VERSION ""

NS_ :

BS_:

BU_:  Battery  Charger  Host

BO_ 2552103157 ALTC_Alternator_Control: 8 Battery
 SG_ ALT_Pack_Max_Volt_Setpoint : 0|16@1+ (0.001,0) [0|65.535] "V" Host

BO_ 2565341429 BATT_dm11Response: 8 Battery
 SG_ BATT_dm11Resv : 0|64@1+ (1,0) [0|255] "" Host

BO_ 2565472256 HOST_J1939_DM_Request: 3 Host
 SG_ HOST_requested_pgn : 0|24@1+ (1,0) [0|281474976710655] "" Battery

BO_ 2565472502 BATT_dmRequest_0: 3 Battery
 SG_ BATT_dm1ReqPgn_0 : 0|24@1+ (1,0) [0|255] "" Host

BO_ 2565472503 BATT_dmRequest_1: 3 Battery
 SG_ BATT_dm1ReqPgn_1 : 0|24@1+ (1,0) [0|255] "" Host

BO_ 2565472504 BATT_dmRequest_2: 3 Battery
 SG_ BATT_dm1ReqPgn_2 : 0|24@1+ (1,0) [0|255] "" Host

BO_ 2565472505 BATT_dmRequest_3: 3 Battery
 SG_ BATT_dm1ReqPgn_3 : 0|24@1+ (1,0) [0|255] "" Host

BO_ 2565472506 BATT_dmRequest_4: 3 Battery
 SG_ BATT_dm1ReqPgn_4 : 0|24@1+ (1,0) [0|255] "" Host

BO_ 2565472507 BATT_dmRequest_5: 3 Battery
 SG_ BATT_dm1ReqPgn_5 : 0|24@1+ (1,0) [0|255] "" Host

BO_ 2565472508 BATT_dmRequest_6: 3 Battery
 SG_ BATT_dm1ReqPgn_6 : 0|24@1+ (1,0) [0|255] "" Host

BO_ 2565472509 BATT_dmRequest_7: 3 Battery
 SG_ BATT_dm1ReqPgn_7 : 0|24@1+ (1,0) [0|255] "" Host

BO_ 2565472510 BATT_dmRequest_8: 3 Battery
 SG_ BATT_dm1ReqPgn_8 : 0|24@1+ (1,0) [0|255] "" Host

BO_ 2565472511 BATT_dmRequest_9: 3 Battery
 SG_ BATT_dm1ReqPgn_9 : 0|24@1+ (1,0) [0|255] "" Host

BO_ 2565538038 BATT_dmTransportMsg_0: 8 Battery
 SG_ BATT_dmPayLoad_0 : 8|56@1+ (1,0) [0|72057594037927904] "" Host
 SG_ BATT_dmSeqNum_0 : 0|8@1+ (1,0) [0|255] "" Host

BO_ 2565538039 BATT_dmTransportMsg_1: 8 Battery
 SG_ BATT_dmPayLoad_1 : 8|56@1+ (1,0) [0|72057594037927904] "" Host
 SG_ BATT_dmSeqNum_1 : 0|8@1+ (1,0) [0|255] "" Host

BO_ 2565538040 BATT_dmTransportMsg_2: 8 Battery
 SG_ BATT_dmPayLoad_2 : 8|56@1+ (1,0) [0|72057594037927904] "" Host
 SG_ BATT_dmSeqNum_2 : 0|8@1+ (1,0) [0|255] "" Host

BO_ 2565538041 BATT_dmTransportMsg_3: 8 Battery
 SG_ BATT_dmPayLoad_3 : 8|56@1+ (1,0) [0|72057594037927904] "" Host
 SG_ BATT_dmSeqNum_3 : 0|8@1+ (1,0) [0|255] "" Host

BO_ 2565538042 BATT_dmTransportMsg_4: 8 Battery
 SG_ BATT_dmPayLoad_4 : 8|56@1+ (1,0) [0|72057594037927904] "" Host
 SG_ BATT_dmSeqNum_4 : 0|8@1+ (1,0) [0|255] "" Host

BO_ 2565538043 BATT_dmTransportMsg_5: 8 Battery
 SG_ BATT_dmPayLoad_5 : 8|56@1+ (1,0) [0|72057594037927904] "" Host
 SG_ BATT_dmSeqNum_5 : 0|8@1+ (1,0) [0|255] "" Host

BO_ 2565538044 BATT_dmTransportMsg_6: 8 Battery
 SG_ BATT_dmPayLoad_6 : 8|56@1+ (1,0) [0|72057594037927904] "" Host
 SG_ BATT_dmSeqNum_6 : 0|8@1+ (1,0) [0|255] "" Host

BO_ 2565538045 BATT_dmTransportMsg_7: 8 Battery
 SG_ BATT_dmPayLoad_7 : 8|56@1+ (1,0) [0|72057594037927904] "" Host
 SG_ BATT_dmSeqNum_7 : 0|8@1+ (1,0) [0|255] "" Host

BO_ 2565538046 BATT_dmTransportMsg_8: 8 Battery
 SG_ BATT_dmPayLoad_8 : 8|56@1+ (1,0) [0|72057594037927904] "" Host
 SG_ BATT_dmSeqNum_8 : 0|8@1+ (1,0) [0|255] "" Host

BO_ 2565538047 BATT_dmTransportMsg_9: 8 Battery
 SG_ BATT_dmPayLoad_9 : 8|56@1+ (1,0) [0|72057594037927904] "" Host
 SG_ BATT_dmSeqNum_9 : 0|8@1+ (1,0) [0|255] "" Host

BO_ 2565603574 BATT_dmBam_0: 8 Battery
 SG_ BATT_bamResv_0 : 32|8@1+ (1,0) [0|255] "" Host
 SG_ BATT_bamPgn_0 : 40|24@1+ (1,0) [0|255] "" Host
 SG_ BATT_bamNumOfPackets_0 : 24|8@1+ (1,0) [0|255] "" Host
 SG_ BATT_bamDataLength_0 : 8|16@1+ (1,0) [0|255] "" Host
 SG_ BATT_bamCtrlByte_0 : 0|8@1+ (1,0) [0|255] "" Host

BO_ 2565603575 BATT_dmBam_1: 8 Battery
 SG_ BATT_bamResv_1 : 32|8@1+ (1,0) [0|255] "" Host
 SG_ BATT_bamPgn_1 : 40|24@1+ (1,0) [0|255] "" Host
 SG_ BATT_bamNumOfPackets_1 : 24|8@1+ (1,0) [0|255] "" Host
 SG_ BATT_bamDataLength_1 : 8|16@1+ (1,0) [0|255] "" Host
 SG_ BATT_bamCtrlByte_1 : 0|8@1+ (1,0) [0|255] "" Host

BO_ 2565603576 BATT_dmBam_2: 8 Battery
 SG_ BATT_bamResv_2 : 32|8@1+ (1,0) [0|255] "" Host
 SG_ BATT_bamPgn_2 : 40|24@1+ (1,0) [0|255] "" Host
 SG_ BATT_bamNumOfPackets_2 : 24|8@1+ (1,0) [0|255] "" Host
 SG_ BATT_bamDataLength_2 : 8|16@1+ (1,0) [0|255] "" Host
 SG_ BATT_bamCtrlByte_2 : 0|8@1+ (1,0) [0|255] "" Host

BO_ 2565603577 BATT_dmBam_3: 8 Battery
 SG_ BATT_bamResv_3 : 32|8@1+ (1,0) [0|255] "" Host
 SG_ BATT_bamPgn_3 : 40|24@1+ (1,0) [0|255] "" Host
 SG_ BATT_bamNumOfPackets_3 : 24|8@1+ (1,0) [0|255] "" Host
 SG_ BATT_bamDataLength_3 : 8|16@1+ (1,0) [0|255] "" Host
 SG_ BATT_bamCtrlByte_3 : 0|8@1+ (1,0) [0|255] "" Host

BO_ 2565603578 BATT_dmBam_4: 8 Battery
 SG_ BATT_bamResv_4 : 32|8@1+ (1,0) [0|255] "" Host
 SG_ BATT_bamPgn_4 : 40|24@1+ (1,0) [0|255] "" Host
 SG_ BATT_bamNumOfPackets_4 : 24|8@1+ (1,0) [0|255] "" Host
 SG_ BATT_bamDataLength_4 : 8|16@1+ (1,0) [0|255] "" Host
 SG_ BATT_bamCtrlByte_4 : 0|8@1+ (1,0) [0|255] "" Host

BO_ 2565603579 BATT_dmBam_5: 8 Battery
 SG_ BATT_bamResv_5 : 32|8@1+ (1,0) [0|255] "" Host
 SG_ BATT_bamPgn_5 : 40|24@1+ (1,0) [0|255] "" Host
 SG_ BATT_bamNumOfPackets_5 : 24|8@1+ (1,0) [0|255] "" Host
 SG_ BATT_bamDataLength_5 : 8|16@1+ (1,0) [0|255] "" Host
 SG_ BATT_bamCtrlByte_5 : 0|8@1+ (1,0) [0|255] "" Host

BO_ 2565603580 BATT_dmBam_6: 8 Battery
 SG_ BATT_bamResv_6 : 32|8@1+ (1,0) [0|255] "" Host
 SG_ BATT_bamPgn_6 : 40|24@1+ (1,0) [0|255] "" Host
 SG_ BATT_bamNumOfPackets_6 : 24|8@1+ (1,0) [0|255] "" Host
 SG_ BATT_bamDataLength_6 : 8|16@1+ (1,0) [0|255] "" Host
 SG_ BATT_bamCtrlByte_6 : 0|8@1+ (1,0) [0|255] "" Host

BO_ 2565603581 BATT_dmBam_7: 8 Battery
 SG_ BATT_bamResv_7 : 32|8@1+ (1,0) [0|255] "" Host
 SG_ BATT_bamPgn_7 : 40|24@1+ (1,0) [0|255] "" Host
 SG_ BATT_bamNumOfPackets_7 : 24|8@1+ (1,0) [0|255] "" Host
 SG_ BATT_bamDataLength_7 : 8|16@1+ (1,0) [0|255] "" Host
 SG_ BATT_bamCtrlByte_7 : 0|8@1+ (1,0) [0|255] "" Host

BO_ 2565603582 BATT_dmBam_8: 8 Battery
 SG_ BATT_bamResv_8 : 32|8@1+ (1,0) [0|255] "" Host
 SG_ BATT_bamPgn_8 : 40|24@1+ (1,0) [0|255] "" Host
 SG_ BATT_bamNumOfPackets_8 : 24|8@1+ (1,0) [0|255] "" Host
 SG_ BATT_bamDataLength_8 : 8|16@1+ (1,0) [0|255] "" Host
 SG_ BATT_bamCtrlByte_8 : 0|8@1+ (1,0) [0|255] "" Host

BO_ 2565603583 BATT_dmBam_9: 8 Battery
 SG_ BATT_bamResv_9 : 32|8@1+ (1,0) [0|255] "" Host
 SG_ BATT_bamPgn_9 : 40|24@1+ (1,0) [0|255] "" Host
 SG_ BATT_bamNumOfPackets_9 : 24|8@1+ (1,0) [0|255] "" Host
 SG_ BATT_bamDataLength_9 : 8|16@1+ (1,0) [0|255] "" Host
 SG_ BATT_bamCtrlByte_9 : 0|8@1+ (1,0) [0|255] "" Host

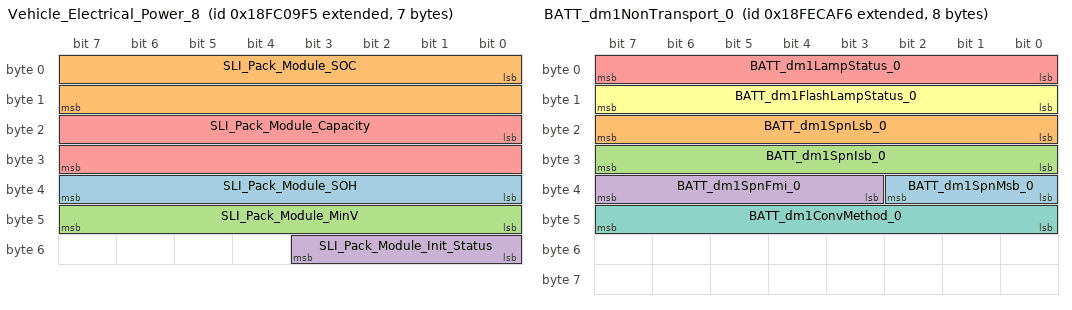
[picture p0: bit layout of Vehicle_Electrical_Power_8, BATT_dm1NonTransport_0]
BO_ 2566654453 Vehicle_Electrical_Power_8: 7 Battery
 SG_ SLI_Pack_Module_SOH : 32|8@1+ (0.5,0) [0|125] "%" Host
 SG_ SLI_Pack_Module_SOC : 0|16@1+ (0.002,0) [0|160.637] "%" Host
 SG_ SLI_Pack_Module_MinV : 40|8@1+ (0.2,0) [0|50] "V" Host
 SG_ SLI_Pack_Module_Init_Status : 48|4@1+ (1,0) [0|15] "" Host
 SG_ SLI_Pack_Module_Capacity : 16|16@1+ (1,0) [0|64255] "Ah" Host

BO_ 2566654709 Vehicle_Electrical_Power_7: 8 Battery
 SG_ SLI_Pack_Module_Voltage : 24|16@1+ (0.05,0) [0|3212.75] "V" Host
 SG_ SLI_Pack_Module_Temp : 16|8@1+ (1,-40) [-40|210] "C" Host
 SG_ SLI_Pack_Module_SOC_Net_Current : 0|16@1+ (0.05,-1600) [-1600|1612.75] "A" Host

BO_ 2566834934 BATT_dm1NonTransport_0: 8 Battery
 SG_ BATT_dm1SpnMsb_0 : 32|3@1+ (1,0) [0|7] "" Host
 SG_ BATT_dm1SpnLsb_0 : 16|8@1+ (1,0) [0|255] "" Host
 SG_ BATT_dm1SpnIsb_0 : 24|8@1+ (1,0) [0|255] "" Host
 SG_ BATT_dm1SpnFmi_0 : 35|5@1+ (1,0) [0|255] "" Host
 SG_ BATT_dm1LampStatus_0 : 0|8@1+ (1,0) [0|255] "" Host
 SG_ BATT_dm1FlashLampStatus_0 : 8|8@1+ (1,0) [0|255] "" Host
 SG_ BATT_dm1ConvMethod_0 : 40|8@1+ (1,0) [0|255] "" Host

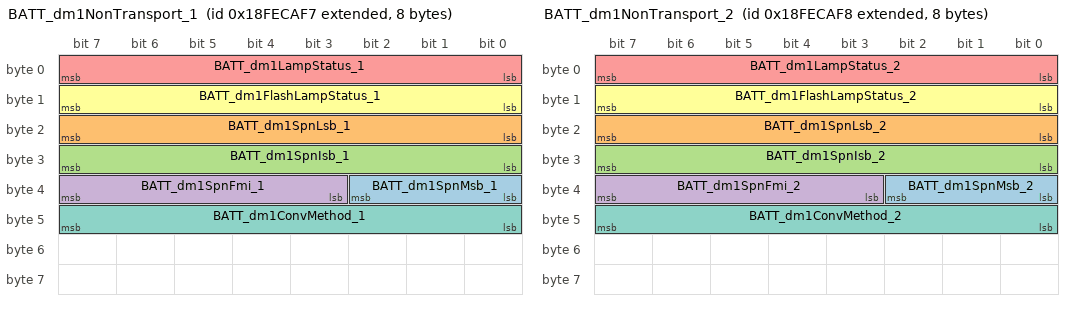
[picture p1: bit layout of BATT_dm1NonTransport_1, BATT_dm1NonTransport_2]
BO_ 2566834935 BATT_dm1NonTransport_1: 8 Battery
 SG_ BATT_dm1SpnMsb_1 : 32|3@1+ (1,0) [0|7] "" Host
 SG_ BATT_dm1SpnLsb_1 : 16|8@1+ (1,0) [0|255] "" Host
 SG_ BATT_dm1SpnIsb_1 : 24|8@1+ (1,0) [0|255] "" Host
 SG_ BATT_dm1SpnFmi_1 : 35|5@1+ (1,0) [0|255] "" Host
 SG_ BATT_dm1LampStatus_1 : 0|8@1+ (1,0) [0|255] "" Host
 SG_ BATT_dm1FlashLampStatus_1 : 8|8@1+ (1,0) [0|255] "" Host
 SG_ BATT_dm1ConvMethod_1 : 40|8@1+ (1,0) [0|255] "" Host

BO_ 2566834936 BATT_dm1NonTransport_2: 8 Battery
 SG_ BATT_dm1SpnMsb_2 : 32|3@1+ (1,0) [0|7] "" Host
 SG_ BATT_dm1SpnLsb_2 : 16|8@1+ (1,0) [0|255] "" Host
 SG_ BATT_dm1SpnIsb_2 : 24|8@1+ (1,0) [0|255] "" Host
 SG_ BATT_dm1SpnFmi_2 : 35|5@1+ (1,0) [0|255] "" Host
 SG_ BATT_dm1LampStatus_2 : 0|8@1+ (1,0) [0|255] "" Host
 SG_ BATT_dm1FlashLampStatus_2 : 8|8@1+ (1,0) [0|255] "" Host
 SG_ BATT_dm1ConvMethod_2 : 40|8@1+ (1,0) [0|255] "" Host

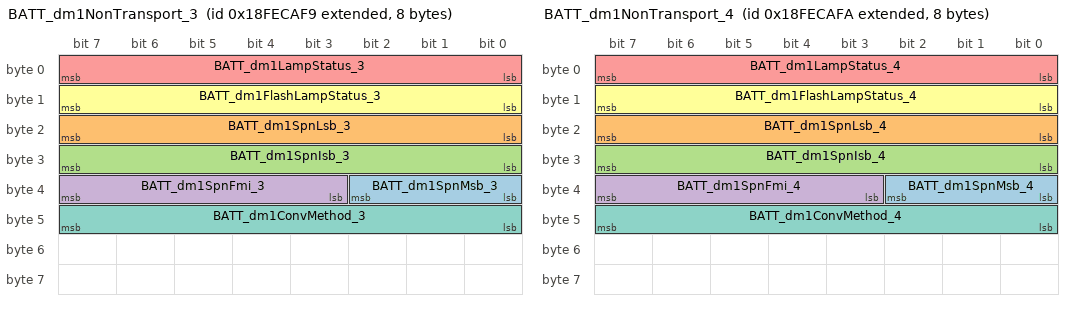
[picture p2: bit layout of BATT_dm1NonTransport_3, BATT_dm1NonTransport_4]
BO_ 2566834937 BATT_dm1NonTransport_3: 8 Battery
 SG_ BATT_dm1SpnMsb_3 : 32|3@1+ (1,0) [0|7] "" Host
 SG_ BATT_dm1SpnLsb_3 : 16|8@1+ (1,0) [0|255] "" Host
 SG_ BATT_dm1SpnIsb_3 : 24|8@1+ (1,0) [0|255] "" Host
 SG_ BATT_dm1SpnFmi_3 : 35|5@1+ (1,0) [0|255] "" Host
 SG_ BATT_dm1LampStatus_3 : 0|8@1+ (1,0) [0|255] "" Host
 SG_ BATT_dm1FlashLampStatus_3 : 8|8@1+ (1,0) [0|255] "" Host
 SG_ BATT_dm1ConvMethod_3 : 40|8@1+ (1,0) [0|255] "" Host

BO_ 2566834938 BATT_dm1NonTransport_4: 8 Battery
 SG_ BATT_dm1SpnMsb_4 : 32|3@1+ (1,0) [0|7] "" Host
 SG_ BATT_dm1SpnLsb_4 : 16|8@1+ (1,0) [0|255] "" Host
 SG_ BATT_dm1SpnIsb_4 : 24|8@1+ (1,0) [0|255] "" Host
 SG_ BATT_dm1SpnFmi_4 : 35|5@1+ (1,0) [0|255] "" Host
 SG_ BATT_dm1LampStatus_4 : 0|8@1+ (1,0) [0|255] "" Host
 SG_ BATT_dm1FlashLampStatus_4 : 8|8@1+ (1,0) [0|255] "" Host
 SG_ BATT_dm1ConvMethod_4 : 40|8@1+ (1,0) [0|255] "" Host

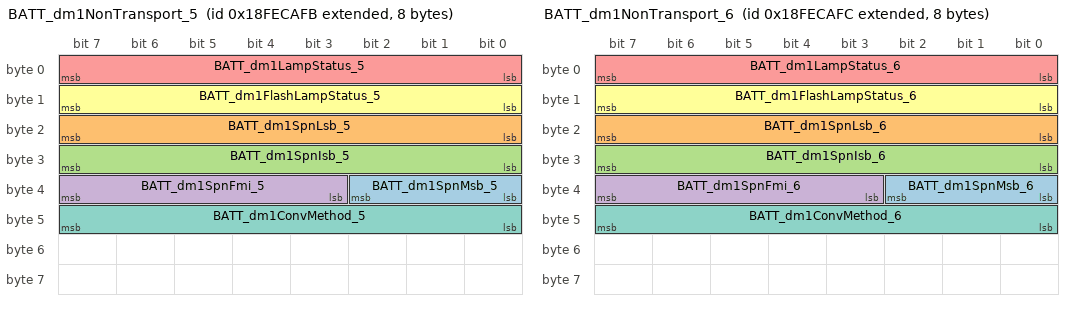
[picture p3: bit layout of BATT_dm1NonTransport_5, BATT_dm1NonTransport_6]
BO_ 2566834939 BATT_dm1NonTransport_5: 8 Battery
 SG_ BATT_dm1SpnMsb_5 : 32|3@1+ (1,0) [0|7] "" Host
 SG_ BATT_dm1SpnLsb_5 : 16|8@1+ (1,0) [0|255] "" Host
 SG_ BATT_dm1SpnIsb_5 : 24|8@1+ (1,0) [0|255] "" Host
 SG_ BATT_dm1SpnFmi_5 : 35|5@1+ (1,0) [0|255] "" Host
 SG_ BATT_dm1LampStatus_5 : 0|8@1+ (1,0) [0|255] "" Host
 SG_ BATT_dm1FlashLampStatus_5 : 8|8@1+ (1,0) [0|255] "" Host
 SG_ BATT_dm1ConvMethod_5 : 40|8@1+ (1,0) [0|255] "" Host

BO_ 2566834940 BATT_dm1NonTransport_6: 8 Battery
 SG_ BATT_dm1SpnMsb_6 : 32|3@1+ (1,0) [0|7] "" Host
 SG_ BATT_dm1SpnLsb_6 : 16|8@1+ (1,0) [0|255] "" Host
 SG_ BATT_dm1SpnIsb_6 : 24|8@1+ (1,0) [0|255] "" Host
 SG_ BATT_dm1SpnFmi_6 : 35|5@1+ (1,0) [0|255] "" Host
 SG_ BATT_dm1LampStatus_6 : 0|8@1+ (1,0) [0|255] "" Host
 SG_ BATT_dm1FlashLampStatus_6 : 8|8@1+ (1,0) [0|255] "" Host
 SG_ BATT_dm1ConvMethod_6 : 40|8@1+ (1,0) [0|255] "" Host

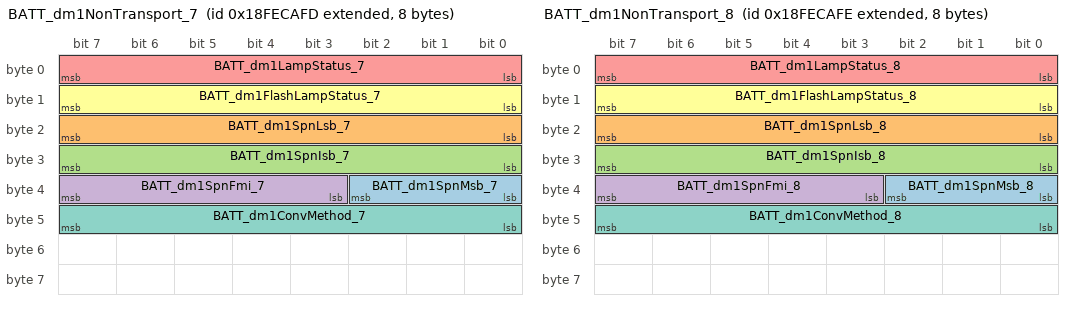
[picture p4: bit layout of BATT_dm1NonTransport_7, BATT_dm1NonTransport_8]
BO_ 2566834941 BATT_dm1NonTransport_7: 8 Battery
 SG_ BATT_dm1SpnMsb_7 : 32|3@1+ (1,0) [0|7] "" Host
 SG_ BATT_dm1SpnLsb_7 : 16|8@1+ (1,0) [0|255] "" Host
 SG_ BATT_dm1SpnIsb_7 : 24|8@1+ (1,0) [0|255] "" Host
 SG_ BATT_dm1SpnFmi_7 : 35|5@1+ (1,0) [0|255] "" Host
 SG_ BATT_dm1LampStatus_7 : 0|8@1+ (1,0) [0|255] "" Host
 SG_ BATT_dm1FlashLampStatus_7 : 8|8@1+ (1,0) [0|255] "" Host
 SG_ BATT_dm1ConvMethod_7 : 40|8@1+ (1,0) [0|255] "" Host

BO_ 2566834942 BATT_dm1NonTransport_8: 8 Battery
 SG_ BATT_dm1SpnMsb_8 : 32|3@1+ (1,0) [0|7] "" Host
 SG_ BATT_dm1SpnLsb_8 : 16|8@1+ (1,0) [0|255] "" Host
 SG_ BATT_dm1SpnIsb_8 : 24|8@1+ (1,0) [0|255] "" Host
 SG_ BATT_dm1SpnFmi_8 : 35|5@1+ (1,0) [0|255] "" Host
 SG_ BATT_dm1LampStatus_8 : 0|8@1+ (1,0) [0|255] "" Host
 SG_ BATT_dm1FlashLampStatus_8 : 8|8@1+ (1,0) [0|255] "" Host
 SG_ BATT_dm1ConvMethod_8 : 40|8@1+ (1,0) [0|255] "" Host

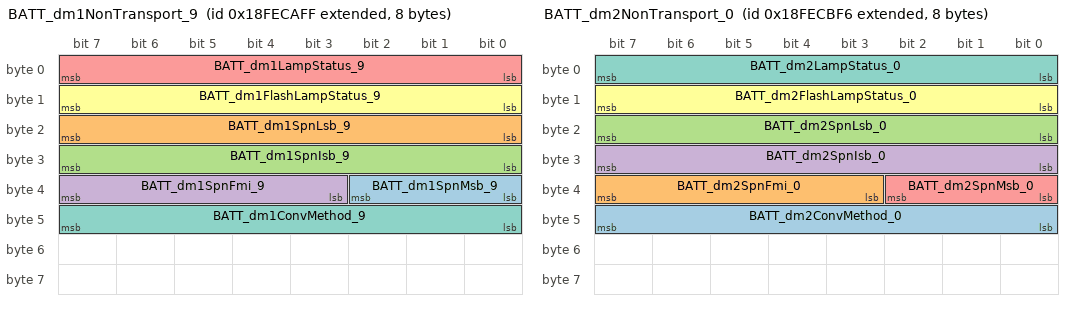
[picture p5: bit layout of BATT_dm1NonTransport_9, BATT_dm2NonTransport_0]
BO_ 2566834943 BATT_dm1NonTransport_9: 8 Battery
 SG_ BATT_dm1SpnMsb_9 : 32|3@1+ (1,0) [0|7] "" Host
 SG_ BATT_dm1SpnLsb_9 : 16|8@1+ (1,0) [0|255] "" Host
 SG_ BATT_dm1SpnIsb_9 : 24|8@1+ (1,0) [0|255] "" Host
 SG_ BATT_dm1SpnFmi_9 : 35|5@1+ (1,0) [0|255] "" Host
 SG_ BATT_dm1LampStatus_9 : 0|8@1+ (1,0) [0|255] "" Host
 SG_ BATT_dm1FlashLampStatus_9 : 8|8@1+ (1,0) [0|255] "" Host
 SG_ BATT_dm1ConvMethod_9 : 40|8@1+ (1,0) [0|255] "" Host

BO_ 2566835190 BATT_dm2NonTransport_0: 8 Battery
 SG_ BATT_dm2ConvMethod_0 : 40|8@1+ (1,0) [0|255] "" Host
 SG_ BATT_dm2SpnFmi_0 : 35|5@1+ (1,0) [0|255] "" Host
 SG_ BATT_dm2SpnLsb_0 : 16|8@1+ (1,0) [0|255] "" Host
 SG_ BATT_dm2SpnIsb_0 : 24|8@1+ (1,0) [0|255] "" Host
 SG_ BATT_dm2SpnMsb_0 : 32|3@1+ (1,0) [0|255] "" Host
 SG_ BATT_dm2FlashLampStatus_0 : 8|8@1+ (1,0) [0|255] "" Host
 SG_ BATT_dm2LampStatus_0 : 0|8@1+ (1,0) [0|255] "" Host

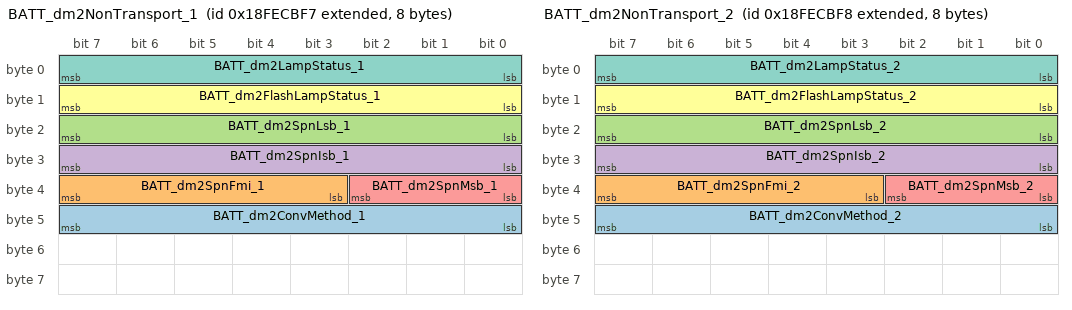
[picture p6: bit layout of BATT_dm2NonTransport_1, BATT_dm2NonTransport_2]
BO_ 2566835191 BATT_dm2NonTransport_1: 8 Battery
 SG_ BATT_dm2ConvMethod_1 : 40|8@1+ (1,0) [0|255] "" Host
 SG_ BATT_dm2SpnFmi_1 : 35|5@1+ (1,0) [0|255] "" Host
 SG_ BATT_dm2SpnLsb_1 : 16|8@1+ (1,0) [0|255] "" Host
 SG_ BATT_dm2SpnIsb_1 : 24|8@1+ (1,0) [0|255] "" Host
 SG_ BATT_dm2SpnMsb_1 : 32|3@1+ (1,0) [0|255] "" Host
 SG_ BATT_dm2FlashLampStatus_1 : 8|8@1+ (1,0) [0|255] "" Host
 SG_ BATT_dm2LampStatus_1 : 0|8@1+ (1,0) [0|255] "" Host

BO_ 2566835192 BATT_dm2NonTransport_2: 8 Battery
 SG_ BATT_dm2ConvMethod_2 : 40|8@1+ (1,0) [0|255] "" Host
 SG_ BATT_dm2SpnFmi_2 : 35|5@1+ (1,0) [0|255] "" Host
 SG_ BATT_dm2SpnLsb_2 : 16|8@1+ (1,0) [0|255] "" Host
 SG_ BATT_dm2SpnIsb_2 : 24|8@1+ (1,0) [0|255] "" Host
 SG_ BATT_dm2SpnMsb_2 : 32|3@1+ (1,0) [0|255] "" Host
 SG_ BATT_dm2FlashLampStatus_2 : 8|8@1+ (1,0) [0|255] "" Host
 SG_ BATT_dm2LampStatus_2 : 0|8@1+ (1,0) [0|255] "" Host

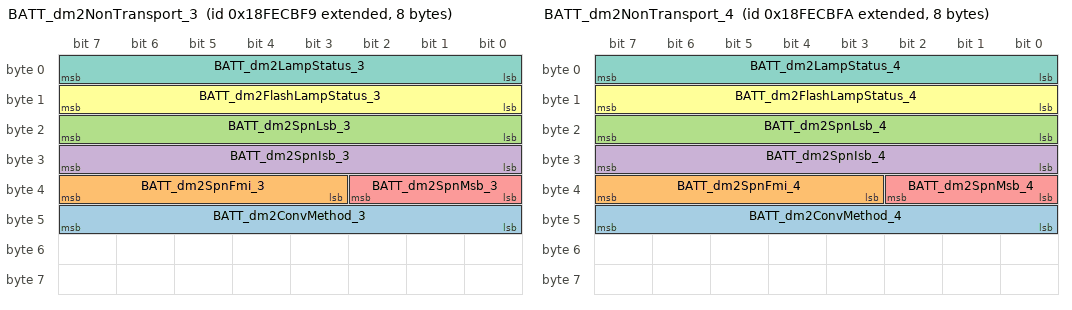
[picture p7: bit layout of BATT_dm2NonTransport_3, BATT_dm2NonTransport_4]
BO_ 2566835193 BATT_dm2NonTransport_3: 8 Battery
 SG_ BATT_dm2ConvMethod_3 : 40|8@1+ (1,0) [0|255] "" Host
 SG_ BATT_dm2SpnFmi_3 : 35|5@1+ (1,0) [0|255] "" Host
 SG_ BATT_dm2SpnLsb_3 : 16|8@1+ (1,0) [0|255] "" Host
 SG_ BATT_dm2SpnIsb_3 : 24|8@1+ (1,0) [0|255] "" Host
 SG_ BATT_dm2SpnMsb_3 : 32|3@1+ (1,0) [0|255] "" Host
 SG_ BATT_dm2FlashLampStatus_3 : 8|8@1+ (1,0) [0|255] "" Host
 SG_ BATT_dm2LampStatus_3 : 0|8@1+ (1,0) [0|255] "" Host

BO_ 2566835194 BATT_dm2NonTransport_4: 8 Battery
 SG_ BATT_dm2ConvMethod_4 : 40|8@1+ (1,0) [0|255] "" Host
 SG_ BATT_dm2SpnFmi_4 : 35|5@1+ (1,0) [0|255] "" Host
 SG_ BATT_dm2SpnLsb_4 : 16|8@1+ (1,0) [0|255] "" Host
 SG_ BATT_dm2SpnIsb_4 : 24|8@1+ (1,0) [0|255] "" Host
 SG_ BATT_dm2SpnMsb_4 : 32|3@1+ (1,0) [0|255] "" Host
 SG_ BATT_dm2FlashLampStatus_4 : 8|8@1+ (1,0) [0|255] "" Host
 SG_ BATT_dm2LampStatus_4 : 0|8@1+ (1,0) [0|255] "" Host

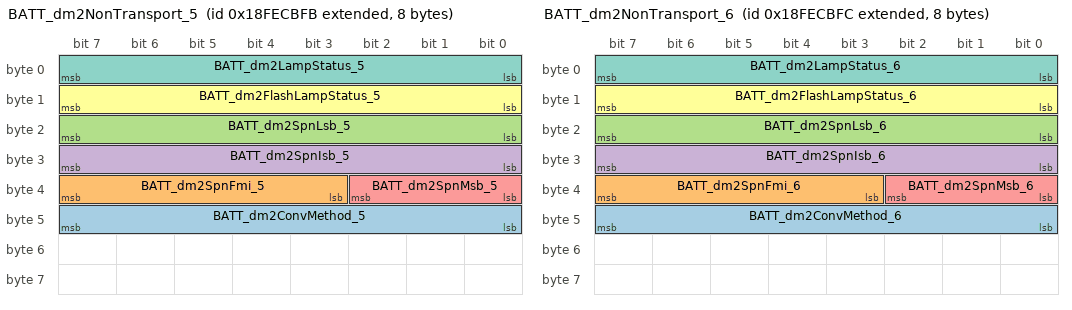
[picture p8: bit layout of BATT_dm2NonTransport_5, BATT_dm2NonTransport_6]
BO_ 2566835195 BATT_dm2NonTransport_5: 8 Battery
 SG_ BATT_dm2ConvMethod_5 : 40|8@1+ (1,0) [0|255] "" Host
 SG_ BATT_dm2SpnFmi_5 : 35|5@1+ (1,0) [0|255] "" Host
 SG_ BATT_dm2SpnLsb_5 : 16|8@1+ (1,0) [0|255] "" Host
 SG_ BATT_dm2SpnIsb_5 : 24|8@1+ (1,0) [0|255] "" Host
 SG_ BATT_dm2SpnMsb_5 : 32|3@1+ (1,0) [0|255] "" Host
 SG_ BATT_dm2FlashLampStatus_5 : 8|8@1+ (1,0) [0|255] "" Host
 SG_ BATT_dm2LampStatus_5 : 0|8@1+ (1,0) [0|255] "" Host

BO_ 2566835196 BATT_dm2NonTransport_6: 8 Battery
 SG_ BATT_dm2ConvMethod_6 : 40|8@1+ (1,0) [0|255] "" Host
 SG_ BATT_dm2SpnFmi_6 : 35|5@1+ (1,0) [0|255] "" Host
 SG_ BATT_dm2SpnLsb_6 : 16|8@1+ (1,0) [0|255] "" Host
 SG_ BATT_dm2SpnIsb_6 : 24|8@1+ (1,0) [0|255] "" Host
 SG_ BATT_dm2SpnMsb_6 : 32|3@1+ (1,0) [0|255] "" Host
 SG_ BATT_dm2FlashLampStatus_6 : 8|8@1+ (1,0) [0|255] "" Host
 SG_ BATT_dm2LampStatus_6 : 0|8@1+ (1,0) [0|255] "" Host

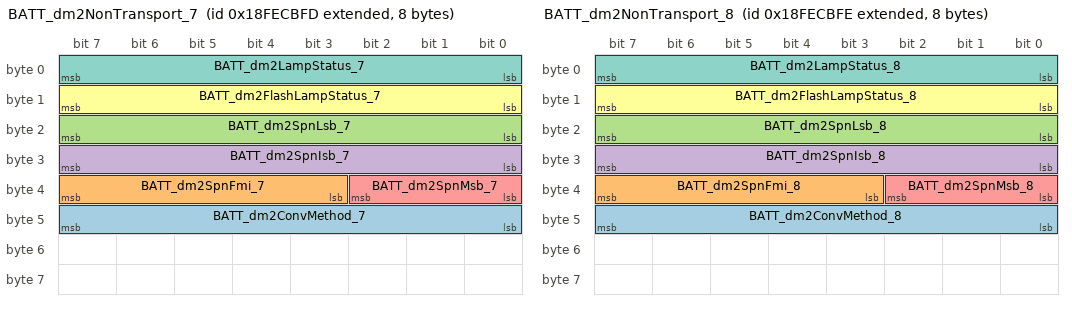
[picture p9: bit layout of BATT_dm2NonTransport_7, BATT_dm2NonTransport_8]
BO_ 2566835197 BATT_dm2NonTransport_7: 8 Battery
 SG_ BATT_dm2ConvMethod_7 : 40|8@1+ (1,0) [0|255] "" Host
 SG_ BATT_dm2SpnFmi_7 : 35|5@1+ (1,0) [0|255] "" Host
 SG_ BATT_dm2SpnLsb_7 : 16|8@1+ (1,0) [0|255] "" Host
 SG_ BATT_dm2SpnIsb_7 : 24|8@1+ (1,0) [0|255] "" Host
 SG_ BATT_dm2SpnMsb_7 : 32|3@1+ (1,0) [0|255] "" Host
 SG_ BATT_dm2FlashLampStatus_7 : 8|8@1+ (1,0) [0|255] "" Host
 SG_ BATT_dm2LampStatus_7 : 0|8@1+ (1,0) [0|255] "" Host

BO_ 2566835198 BATT_dm2NonTransport_8: 8 Battery
 SG_ BATT_dm2ConvMethod_8 : 40|8@1+ (1,0) [0|255] "" Host
 SG_ BATT_dm2SpnFmi_8 : 35|5@1+ (1,0) [0|255] "" Host
 SG_ BATT_dm2SpnLsb_8 : 16|8@1+ (1,0) [0|255] "" Host
 SG_ BATT_dm2SpnIsb_8 : 24|8@1+ (1,0) [0|255] "" Host
 SG_ BATT_dm2SpnMsb_8 : 32|3@1+ (1,0) [0|255] "" Host
 SG_ BATT_dm2FlashLampStatus_8 : 8|8@1+ (1,0) [0|255] "" Host
 SG_ BATT_dm2LampStatus_8 : 0|8@1+ (1,0) [0|255] "" Host

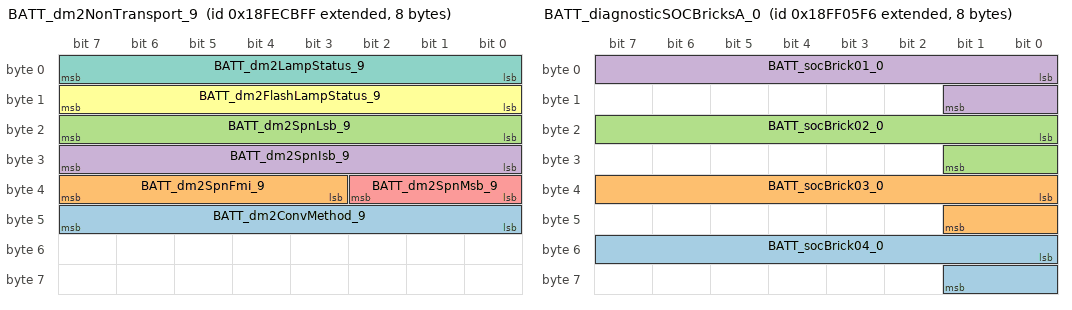
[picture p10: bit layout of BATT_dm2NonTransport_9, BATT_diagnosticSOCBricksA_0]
BO_ 2566835199 BATT_dm2NonTransport_9: 8 Battery
 SG_ BATT_dm2ConvMethod_9 : 40|8@1+ (1,0) [0|255] "" Host
 SG_ BATT_dm2SpnFmi_9 : 35|5@1+ (1,0) [0|255] "" Host
 SG_ BATT_dm2SpnLsb_9 : 16|8@1+ (1,0) [0|255] "" Host
 SG_ BATT_dm2SpnIsb_9 : 24|8@1+ (1,0) [0|255] "" Host
 SG_ BATT_dm2SpnMsb_9 : 32|3@1+ (1,0) [0|255] "" Host
 SG_ BATT_dm2FlashLampStatus_9 : 8|8@1+ (1,0) [0|255] "" Host
 SG_ BATT_dm2LampStatus_9 : 0|8@1+ (1,0) [0|255] "" Host

BO_ 2566849014 BATT_modDchLimits_0: 8 Battery
 SG_ BATT_vModDchLimit_0 : 48|16@1+ (0.005,0) [0|70] "V" Host,Battery
 SG_ BATT_iModDchLimit30s_0 : 32|16@1- (0.02,0) [-655.36|655.34] "A" Host,Battery
 SG_ BATT_iModDchLimit10s_0 : 16|16@1- (0.02,0) [-655.36|655.34] "A" Host,Battery
 SG_ BATT_iModDchLimitCont_0 : 0|16@1- (0.02,0) [-655.36|655.34] "A" Host,Battery

BO_ 2566849015 BATT_modDchLimits_1: 8 Battery
 SG_ BATT_vModDchLimit_1 : 48|16@1+ (0.005,0) [0|70] "V" Host,Battery
 SG_ BATT_iModDchLimit30s_1 : 32|16@1- (0.02,0) [-655.36|655.34] "A" Host,Battery
 SG_ BATT_iModDchLimit10s_1 : 16|16@1- (0.02,0) [-655.36|655.34] "A" Host,Battery
 SG_ BATT_iModDchLimitCont_1 : 0|16@1- (0.02,0) [-655.36|655.34] "A" Host,Battery

BO_ 2566849016 BATT_modDchLimits_2: 8 Battery
 SG_ BATT_vModDchLimit_2 : 48|16@1+ (0.005,0) [0|70] "V" Host,Battery
 SG_ BATT_iModDchLimit30s_2 : 32|16@1- (0.02,0) [-655.36|655.34] "A" Host,Battery
 SG_ BATT_iModDchLimit10s_2 : 16|16@1- (0.02,0) [-655.36|655.34] "A" Host,Battery
 SG_ BATT_iModDchLimitCont_2 : 0|16@1- (0.02,0) [-655.36|655.34] "A" Host,Battery

BO_ 2566849017 BATT_modDchLimits_3: 8 Battery
 SG_ BATT_vModDchLimit_3 : 48|16@1+ (0.005,0) [0|70] "V" Host,Battery
 SG_ BATT_iModDchLimit30s_3 : 32|16@1- (0.02,0) [-655.36|655.34] "A" Host,Battery
 SG_ BATT_iModDchLimit10s_3 : 16|16@1- (0.02,0) [-655.36|655.34] "A" Host,Battery
 SG_ BATT_iModDchLimitCont_3 : 0|16@1- (0.02,0) [-655.36|655.34] "A" Host,Battery

BO_ 2566849018 BATT_modDchLimits_4: 8 Battery
 SG_ BATT_vModDchLimit_4 : 48|16@1+ (0.005,0) [0|70] "V" Host,Battery
 SG_ BATT_iModDchLimit30s_4 : 32|16@1- (0.02,0) [-655.36|655.34] "A" Host,Battery
 SG_ BATT_iModDchLimit10s_4 : 16|16@1- (0.02,0) [-655.36|655.34] "A" Host,Battery
 SG_ BATT_iModDchLimitCont_4 : 0|16@1- (0.02,0) [-655.36|655.34] "A" Host,Battery

BO_ 2566849019 BATT_modDchLimits_5: 8 Battery
 SG_ BATT_vModDchLimit_5 : 48|16@1+ (0.005,0) [0|70] "V" Host,Battery
 SG_ BATT_iModDchLimit30s_5 : 32|16@1- (0.02,0) [-655.36|655.34] "A" Host,Battery
 SG_ BATT_iModDchLimit10s_5 : 16|16@1- (0.02,0) [-655.36|655.34] "A" Host,Battery
 SG_ BATT_iModDchLimitCont_5 : 0|16@1- (0.02,0) [-655.36|655.34] "A" Host,Battery

BO_ 2566849020 BATT_modDchLimits_6: 8 Battery
 SG_ BATT_vModDchLimit_6 : 48|16@1+ (0.005,0) [0|70] "V" Host,Battery
 SG_ BATT_iModDchLimit30s_6 : 32|16@1- (0.02,0) [-655.36|655.34] "A" Host,Battery
 SG_ BATT_iModDchLimit10s_6 : 16|16@1- (0.02,0) [-655.36|655.34] "A" Host,Battery
 SG_ BATT_iModDchLimitCont_6 : 0|16@1- (0.02,0) [-655.36|655.34] "A" Host,Battery

BO_ 2566849021 BATT_modDchLimits_7: 8 Battery
 SG_ BATT_vModDchLimit_7 : 48|16@1+ (0.005,0) [0|70] "V" Host,Battery
 SG_ BATT_iModDchLimit30s_7 : 32|16@1- (0.02,0) [-655.36|655.34] "A" Host,Battery
 SG_ BATT_iModDchLimit10s_7 : 16|16@1- (0.02,0) [-655.36|655.34] "A" Host,Battery
 SG_ BATT_iModDchLimitCont_7 : 0|16@1- (0.02,0) [-655.36|655.34] "A" Host,Battery

BO_ 2566849022 BATT_modDchLimits_8: 8 Battery
 SG_ BATT_vModDchLimit_8 : 48|16@1+ (0.005,0) [0|70] "V" Host,Battery
 SG_ BATT_iModDchLimit30s_8 : 32|16@1- (0.02,0) [-655.36|655.34] "A" Host,Battery
 SG_ BATT_iModDchLimit10s_8 : 16|16@1- (0.02,0) [-655.36|655.34] "A" Host,Battery
 SG_ BATT_iModDchLimitCont_8 : 0|16@1- (0.02,0) [-655.36|655.34] "A" Host,Battery

BO_ 2566849023 BATT_modDchLimits_9: 8 Battery
 SG_ BATT_vModDchLimit_9 : 48|16@1+ (0.005,0) [0|70] "V" Host,Battery
 SG_ BATT_iModDchLimit30s_9 : 32|16@1- (0.02,0) [-655.36|655.34] "A" Host,Battery
 SG_ BATT_iModDchLimit10s_9 : 16|16@1- (0.02,0) [-655.36|655.34] "A" Host,Battery
 SG_ BATT_iModDchLimitCont_9 : 0|16@1- (0.02,0) [-655.36|655.34] "A" Host,Battery

BO_ 2566849526 BATT_diagnosticSOHRBricksA_0: 8 Battery
 SG_ BATT_sohrBrick04_0 : 48|16@1+ (0.00075,0) [0|49.15125] "Ah" Host
 SG_ BATT_sohrBrick03_0 : 32|16@1+ (0.00075,0) [0|49.15125] "Ah" Host
 SG_ BATT_sohrBrick02_0 : 16|16@1+ (0.00075,0) [0|49.15125] "Ah" Host
 SG_ BATT_sohrBrick01_0 : 0|16@1+ (0.00075,0) [0|49.15125] "Ah" Host

BO_ 2566849527 BATT_diagnosticSOHRBricksA_1: 8 Battery
 SG_ BATT_sohrBrick04_1 : 48|16@1+ (0.00075,0) [0|49.15125] "Ah" Host
 SG_ BATT_sohrBrick03_1 : 32|16@1+ (0.00075,0) [0|49.15125] "Ah" Host
 SG_ BATT_sohrBrick02_1 : 16|16@1+ (0.00075,0) [0|49.15125] "Ah" Host
 SG_ BATT_sohrBrick01_1 : 0|16@1+ (0.00075,0) [0|49.15125] "Ah" Host

BO_ 2566849528 BATT_diagnosticSOHRBricksA_2: 8 Battery
 SG_ BATT_sohrBrick04_2 : 48|16@1+ (0.00075,0) [0|49.15125] "Ah" Host
 SG_ BATT_sohrBrick03_2 : 32|16@1+ (0.00075,0) [0|49.15125] "Ah" Host
 SG_ BATT_sohrBrick02_2 : 16|16@1+ (0.00075,0) [0|49.15125] "Ah" Host
 SG_ BATT_sohrBrick01_2 : 0|16@1+ (0.00075,0) [0|49.15125] "Ah" Host

BO_ 2566849529 BATT_diagnosticSOHRBricksA_3: 8 Battery
 SG_ BATT_sohrBrick04_3 : 48|16@1+ (0.00075,0) [0|49.15125] "Ah" Host
 SG_ BATT_sohrBrick03_3 : 32|16@1+ (0.00075,0) [0|49.15125] "Ah" Host
 SG_ BATT_sohrBrick02_3 : 16|16@1+ (0.00075,0) [0|49.15125] "Ah" Host
 SG_ BATT_sohrBrick01_3 : 0|16@1+ (0.00075,0) [0|49.15125] "Ah" Host

BO_ 2566849530 BATT_diagnosticSOHRBricksA_4: 8 Battery
 SG_ BATT_sohrBrick04_4 : 48|16@1+ (0.00075,0) [0|49.15125] "Ah" Host
 SG_ BATT_sohrBrick03_4 : 32|16@1+ (0.00075,0) [0|49.15125] "Ah" Host
 SG_ BATT_sohrBrick02_4 : 16|16@1+ (0.00075,0) [0|49.15125] "Ah" Host
 SG_ BATT_sohrBrick01_4 : 0|16@1+ (0.00075,0) [0|49.15125] "Ah" Host

BO_ 2566849531 BATT_diagnosticSOHRBricksA_5: 8 Battery
 SG_ BATT_sohrBrick04_5 : 48|16@1+ (0.00075,0) [0|49.15125] "Ah" Host
 SG_ BATT_sohrBrick03_5 : 32|16@1+ (0.00075,0) [0|49.15125] "Ah" Host
 SG_ BATT_sohrBrick02_5 : 16|16@1+ (0.00075,0) [0|49.15125] "Ah" Host
 SG_ BATT_sohrBrick01_5 : 0|16@1+ (0.00075,0) [0|49.15125] "Ah" Host

BO_ 2566849532 BATT_diagnosticSOHRBricksA_6: 8 Battery
 SG_ BATT_sohrBrick04_6 : 48|16@1+ (0.00075,0) [0|49.15125] "Ah" Host
 SG_ BATT_sohrBrick03_6 : 32|16@1+ (0.00075,0) [0|49.15125] "Ah" Host
 SG_ BATT_sohrBrick02_6 : 16|16@1+ (0.00075,0) [0|49.15125] "Ah" Host
 SG_ BATT_sohrBrick01_6 : 0|16@1+ (0.00075,0) [0|49.15125] "Ah" Host

BO_ 2566849533 BATT_diagnosticSOHRBricksA_7: 8 Battery
 SG_ BATT_sohrBrick04_7 : 48|16@1+ (0.00075,0) [0|49.15125] "Ah" Host
 SG_ BATT_sohrBrick03_7 : 32|16@1+ (0.00075,0) [0|49.15125] "Ah" Host
 SG_ BATT_sohrBrick02_7 : 16|16@1+ (0.00075,0) [0|49.15125] "Ah" Host
 SG_ BATT_sohrBrick01_7 : 0|16@1+ (0.00075,0) [0|49.15125] "Ah" Host

BO_ 2566849534 BATT_diagnosticSOHRBricksA_8: 8 Battery
 SG_ BATT_sohrBrick04_8 : 48|16@1+ (0.00075,0) [0|49.15125] "Ah" Host
 SG_ BATT_sohrBrick03_8 : 32|16@1+ (0.00075,0) [0|49.15125] "Ah" Host
 SG_ BATT_sohrBrick02_8 : 16|16@1+ (0.00075,0) [0|49.15125] "Ah" Host
 SG_ BATT_sohrBrick01_8 : 0|16@1+ (0.00075,0) [0|49.15125] "Ah" Host

BO_ 2566849535 BATT_diagnosticSOHRBricksA_9: 8 Battery
 SG_ BATT_sohrBrick04_9 : 48|16@1+ (0.00075,0) [0|49.15125] "Ah" Host
 SG_ BATT_sohrBrick03_9 : 32|16@1+ (0.00075,0) [0|49.15125] "Ah" Host
 SG_ BATT_sohrBrick02_9 : 16|16@1+ (0.00075,0) [0|49.15125] "Ah" Host
 SG_ BATT_sohrBrick01_9 : 0|16@1+ (0.00075,0) [0|49.15125] "Ah" Host

BO_ 2566850038 BATT_diagnosticSOCBricksA_0: 8 Battery
 SG_ BATT_socBrick04_0 : 48|10@1+ (0.1,0) [0|102.3] "%" Host
 SG_ BATT_socBrick03_0 : 32|10@1+ (0.1,0) [0|102.3] "%" Host
 SG_ BATT_socBrick02_0 : 16|10@1+ (0.1,0) [0|102.3] "%" Host
 SG_ BATT_socBrick01_0 : 0|10@1+ (0.1,0) [0|102.3] "%" Host

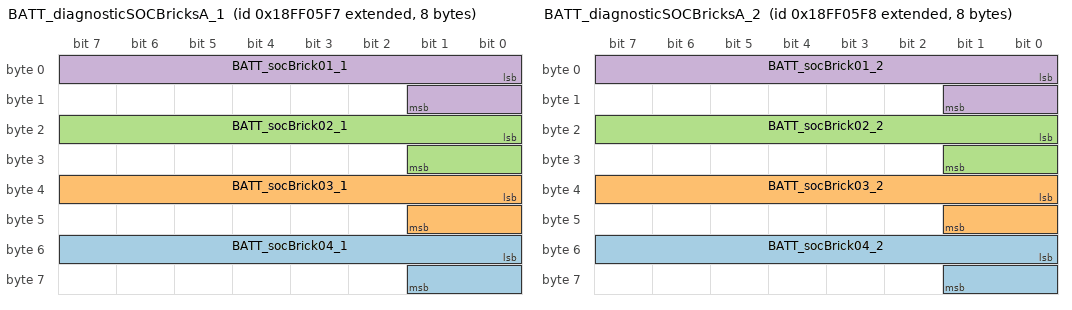
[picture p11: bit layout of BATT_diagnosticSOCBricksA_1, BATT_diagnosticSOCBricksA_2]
BO_ 2566850039 BATT_diagnosticSOCBricksA_1: 8 Battery
 SG_ BATT_socBrick04_1 : 48|10@1+ (0.1,0) [0|102.3] "%" Host
 SG_ BATT_socBrick03_1 : 32|10@1+ (0.1,0) [0|102.3] "%" Host
 SG_ BATT_socBrick02_1 : 16|10@1+ (0.1,0) [0|102.3] "%" Host
 SG_ BATT_socBrick01_1 : 0|10@1+ (0.1,0) [0|102.3] "%" Host

BO_ 2566850040 BATT_diagnosticSOCBricksA_2: 8 Battery
 SG_ BATT_socBrick04_2 : 48|10@1+ (0.1,0) [0|102.3] "%" Host
 SG_ BATT_socBrick03_2 : 32|10@1+ (0.1,0) [0|102.3] "%" Host
 SG_ BATT_socBrick02_2 : 16|10@1+ (0.1,0) [0|102.3] "%" Host
 SG_ BATT_socBrick01_2 : 0|10@1+ (0.1,0) [0|102.3] "%" Host

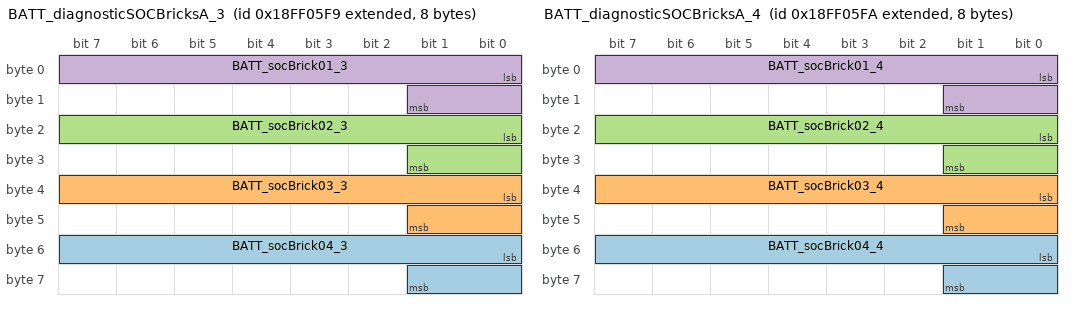
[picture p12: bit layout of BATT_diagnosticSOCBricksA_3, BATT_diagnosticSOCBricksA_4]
BO_ 2566850041 BATT_diagnosticSOCBricksA_3: 8 Battery
 SG_ BATT_socBrick04_3 : 48|10@1+ (0.1,0) [0|102.3] "%" Host
 SG_ BATT_socBrick03_3 : 32|10@1+ (0.1,0) [0|102.3] "%" Host
 SG_ BATT_socBrick02_3 : 16|10@1+ (0.1,0) [0|102.3] "%" Host
 SG_ BATT_socBrick01_3 : 0|10@1+ (0.1,0) [0|102.3] "%" Host

BO_ 2566850042 BATT_diagnosticSOCBricksA_4: 8 Battery
 SG_ BATT_socBrick04_4 : 48|10@1+ (0.1,0) [0|102.3] "%" Host
 SG_ BATT_socBrick03_4 : 32|10@1+ (0.1,0) [0|102.3] "%" Host
 SG_ BATT_socBrick02_4 : 16|10@1+ (0.1,0) [0|102.3] "%" Host
 SG_ BATT_socBrick01_4 : 0|10@1+ (0.1,0) [0|102.3] "%" Host

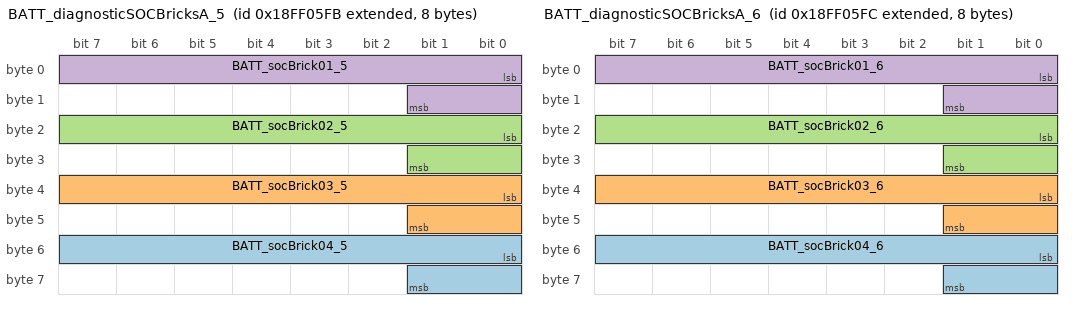
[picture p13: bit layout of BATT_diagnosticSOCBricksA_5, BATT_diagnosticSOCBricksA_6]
BO_ 2566850043 BATT_diagnosticSOCBricksA_5: 8 Battery
 SG_ BATT_socBrick04_5 : 48|10@1+ (0.1,0) [0|102.3] "%" Host
 SG_ BATT_socBrick03_5 : 32|10@1+ (0.1,0) [0|102.3] "%" Host
 SG_ BATT_socBrick02_5 : 16|10@1+ (0.1,0) [0|102.3] "%" Host
 SG_ BATT_socBrick01_5 : 0|10@1+ (0.1,0) [0|102.3] "%" Host

BO_ 2566850044 BATT_diagnosticSOCBricksA_6: 8 Battery
 SG_ BATT_socBrick04_6 : 48|10@1+ (0.1,0) [0|102.3] "%" Host
 SG_ BATT_socBrick03_6 : 32|10@1+ (0.1,0) [0|102.3] "%" Host
 SG_ BATT_socBrick02_6 : 16|10@1+ (0.1,0) [0|102.3] "%" Host
 SG_ BATT_socBrick01_6 : 0|10@1+ (0.1,0) [0|102.3] "%" Host

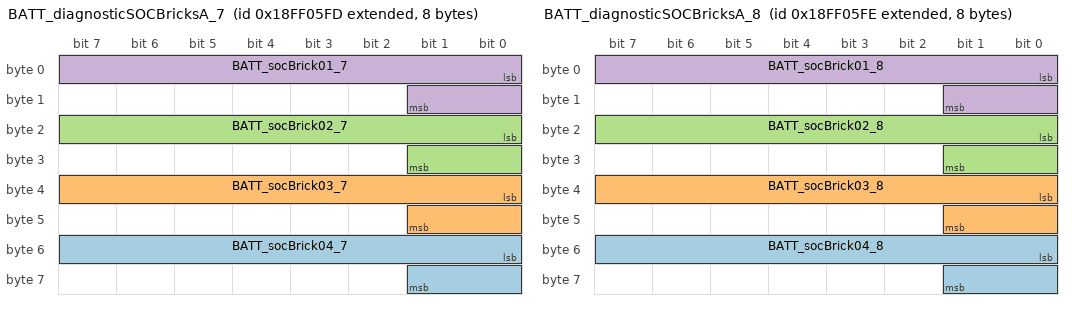
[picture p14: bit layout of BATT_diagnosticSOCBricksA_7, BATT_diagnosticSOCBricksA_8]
BO_ 2566850045 BATT_diagnosticSOCBricksA_7: 8 Battery
 SG_ BATT_socBrick04_7 : 48|10@1+ (0.1,0) [0|102.3] "%" Host
 SG_ BATT_socBrick03_7 : 32|10@1+ (0.1,0) [0|102.3] "%" Host
 SG_ BATT_socBrick02_7 : 16|10@1+ (0.1,0) [0|102.3] "%" Host
 SG_ BATT_socBrick01_7 : 0|10@1+ (0.1,0) [0|102.3] "%" Host

BO_ 2566850046 BATT_diagnosticSOCBricksA_8: 8 Battery
 SG_ BATT_socBrick04_8 : 48|10@1+ (0.1,0) [0|102.3] "%" Host
 SG_ BATT_socBrick03_8 : 32|10@1+ (0.1,0) [0|102.3] "%" Host
 SG_ BATT_socBrick02_8 : 16|10@1+ (0.1,0) [0|102.3] "%" Host
 SG_ BATT_socBrick01_8 : 0|10@1+ (0.1,0) [0|102.3] "%" Host

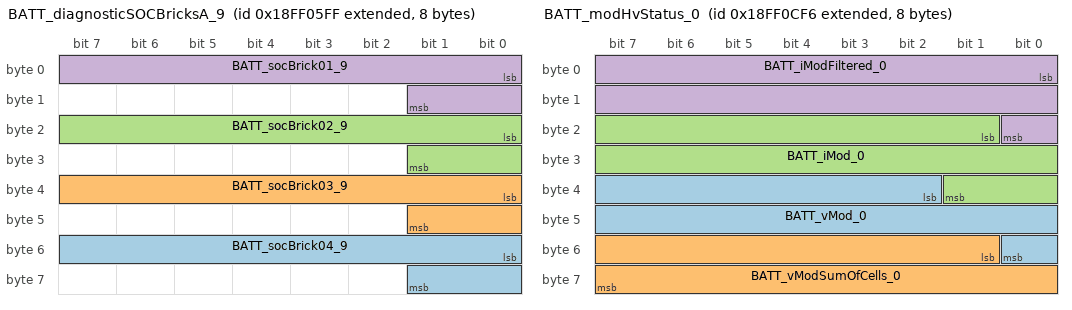
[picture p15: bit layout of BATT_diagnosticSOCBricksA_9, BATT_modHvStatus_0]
BO_ 2566850047 BATT_diagnosticSOCBricksA_9: 8 Battery
 SG_ BATT_socBrick04_9 : 48|10@1+ (0.1,0) [0|102.3] "%" Host
 SG_ BATT_socBrick03_9 : 32|10@1+ (0.1,0) [0|102.3] "%" Host
 SG_ BATT_socBrick02_9 : 16|10@1+ (0.1,0) [0|102.3] "%" Host
 SG_ BATT_socBrick01_9 : 0|10@1+ (0.1,0) [0|102.3] "%" Host

BO_ 2566850806 BATT_diagnosticResBricksA_0: 8 Battery
 SG_ BATT_resBrick04_0 : 48|16@1+ (0.01,0) [0|655.35] "mOhms" Host
 SG_ BATT_resBrick03_0 : 32|16@1+ (0.01,0) [0|655.35] "mOhms" Host
 SG_ BATT_resBrick02_0 : 16|16@1+ (0.01,0) [0|655.35] "mOhms" Host
 SG_ BATT_resBrick01_0 : 0|16@1+ (0.01,0) [0|655.35] "mOhms" Host

BO_ 2566850807 BATT_diagnosticResBricksA_1: 8 Battery
 SG_ BATT_resBrick04_1 : 48|16@1+ (0.01,0) [0|655.35] "mOhms" Host
 SG_ BATT_resBrick03_1 : 32|16@1+ (0.01,0) [0|655.35] "mOhms" Host
 SG_ BATT_resBrick02_1 : 16|16@1+ (0.01,0) [0|655.35] "mOhms" Host
 SG_ BATT_resBrick01_1 : 0|16@1+ (0.01,0) [0|655.35] "mOhms" Host

BO_ 2566850808 BATT_diagnosticResBricksA_2: 8 Battery
 SG_ BATT_resBrick04_2 : 48|16@1+ (0.01,0) [0|655.35] "mOhms" Host
 SG_ BATT_resBrick03_2 : 32|16@1+ (0.01,0) [0|655.35] "mOhms" Host
 SG_ BATT_resBrick02_2 : 16|16@1+ (0.01,0) [0|655.35] "mOhms" Host
 SG_ BATT_resBrick01_2 : 0|16@1+ (0.01,0) [0|655.35] "mOhms" Host

BO_ 2566850809 BATT_diagnosticResBricksA_3: 8 Battery
 SG_ BATT_resBrick04_3 : 48|16@1+ (0.01,0) [0|655.35] "mOhms" Host
 SG_ BATT_resBrick03_3 : 32|16@1+ (0.01,0) [0|655.35] "mOhms" Host
 SG_ BATT_resBrick02_3 : 16|16@1+ (0.01,0) [0|655.35] "mOhms" Host
 SG_ BATT_resBrick01_3 : 0|16@1+ (0.01,0) [0|655.35] "mOhms" Host

BO_ 2566850810 BATT_diagnosticResBricksA_4: 8 Battery
 SG_ BATT_resBrick04_4 : 48|16@1+ (0.01,0) [0|655.35] "mOhms" Host
 SG_ BATT_resBrick03_4 : 32|16@1+ (0.01,0) [0|655.35] "mOhms" Host
 SG_ BATT_resBrick02_4 : 16|16@1+ (0.01,0) [0|655.35] "mOhms" Host
 SG_ BATT_resBrick01_4 : 0|16@1+ (0.01,0) [0|655.35] "mOhms" Host

BO_ 2566850811 BATT_diagnosticResBricksA_5: 8 Battery
 SG_ BATT_resBrick04_5 : 48|16@1+ (0.01,0) [0|655.35] "mOhms" Host
 SG_ BATT_resBrick03_5 : 32|16@1+ (0.01,0) [0|655.35] "mOhms" Host
 SG_ BATT_resBrick02_5 : 16|16@1+ (0.01,0) [0|655.35] "mOhms" Host
 SG_ BATT_resBrick01_5 : 0|16@1+ (0.01,0) [0|655.35] "mOhms" Host

BO_ 2566850812 BATT_diagnosticResBricksA_6: 8 Battery
 SG_ BATT_resBrick04_6 : 48|16@1+ (0.01,0) [0|655.35] "mOhms" Host
 SG_ BATT_resBrick03_6 : 32|16@1+ (0.01,0) [0|655.35] "mOhms" Host
 SG_ BATT_resBrick02_6 : 16|16@1+ (0.01,0) [0|655.35] "mOhms" Host
 SG_ BATT_resBrick01_6 : 0|16@1+ (0.01,0) [0|655.35] "mOhms" Host

BO_ 2566850813 BATT_diagnosticResBricksA_7: 8 Battery
 SG_ BATT_resBrick04_7 : 48|16@1+ (0.01,0) [0|655.35] "mOhms" Host
 SG_ BATT_resBrick03_7 : 32|16@1+ (0.01,0) [0|655.35] "mOhms" Host
 SG_ BATT_resBrick02_7 : 16|16@1+ (0.01,0) [0|655.35] "mOhms" Host
 SG_ BATT_resBrick01_7 : 0|16@1+ (0.01,0) [0|655.35] "mOhms" Host

BO_ 2566850814 BATT_diagnosticResBricksA_8: 8 Battery
 SG_ BATT_resBrick04_8 : 48|16@1+ (0.01,0) [0|655.35] "mOhms" Host
 SG_ BATT_resBrick03_8 : 32|16@1+ (0.01,0) [0|655.35] "mOhms" Host
 SG_ BATT_resBrick02_8 : 16|16@1+ (0.01,0) [0|655.35] "mOhms" Host
 SG_ BATT_resBrick01_8 : 0|16@1+ (0.01,0) [0|655.35] "mOhms" Host

BO_ 2566850815 BATT_diagnosticResBricksA_9: 8 Battery
 SG_ BATT_resBrick04_9 : 48|16@1+ (0.01,0) [0|655.35] "mOhms" Host
 SG_ BATT_resBrick03_9 : 32|16@1+ (0.01,0) [0|655.35] "mOhms" Host
 SG_ BATT_resBrick02_9 : 16|16@1+ (0.01,0) [0|655.35] "mOhms" Host
 SG_ BATT_resBrick01_9 : 0|16@1+ (0.01,0) [0|655.35] "mOhms" Host

BO_ 2566851062 BATT_modTemperaturesA: 8 Battery
 SG_ BATT_tModule2 : 32|16@1- (0.1,0) [-40|125] "deg C" Host
 SG_ BATT_tModule1 : 16|16@1- (0.1,0) [-40|125] "deg C" Host
 SG_ BATT_tBoard : 0|16@1- (0.1,0) [-40|125] "deg C" Host

BO_ 2566851318 BATT_modStatus_0: 8 Battery
 SG_ BATT_modUVP_0 : 13|1@1+ (1,0) [0|1] "" Battery
 SG_ BATT_modWeldStat_0 : 12|1@1+ (1,0) [0|1] "" Battery
 SG_ BATT_modNumModsDataValid_0 : 60|4@1+ (1,0) [0|15] "" Battery,Host
 SG_ BATT_modNumModsOnNetwork_0 : 52|4@1+ (1,0) [0|15] "" Battery,Host
 SG_ BATT_modNumModsOnHvBus_0 : 56|4@1+ (1,0) [0|15] "" Battery,Host
 SG_ BATT_modNumModsConfigured_0 : 48|4@1+ (1,0) [0|15] "" Battery,Host
 SG_ BATT_ArbitrationComplete_0 : 15|1@1+ (1,0) [0|1] "" Battery,Host
 SG_ BATT_modStateRequested_0 : 46|2@1+ (1,0) [0|3] "" Battery,Host
 SG_ BATT_modDataValid_0 : 7|1@1+ (1,0) [0|1] "" Battery,Host
 SG_ BATT_prechargeState_0 : 43|3@1+ (1,0) [0|7] "" Battery,Host
 SG_ BATT_fetPchgCommand_0 : 42|1@1+ (1,0) [0|1] "" Battery,Host
 SG_ BATT_fetDsgCommand_0 : 40|1@1+ (1,0) [0|1] "" Battery,Host
 SG_ BATT_fetChgCommand_0 : 41|1@1+ (1,0) [0|1] "" Battery,Host
 SG_ BATT_fetDsgStatus_0 : 36|4@1+ (1,0) [0|15] "" Battery,Host
 SG_ BATT_fetChgStatus_0 : 32|4@1+ (1,0) [0|15] "" Battery,Host
 SG_ BATT_timeRampdown_0 : 24|6@1+ (1,0) [0|63] "seconds" Battery,Host
 SG_ BATT_inhRegen_0 : 31|1@1+ (1,0) [0|1] "" Battery,Host
 SG_ BATT_inhFullPower_0 : 23|1@1+ (1,0) [0|1] "" Battery,Host
 SG_ BATT_inhDriveEntry_0 : 22|1@1+ (1,0) [0|1] "" Battery,Host
 SG_ BATT_inhDrive_0 : 21|1@1+ (1,0) [0|1] "" Battery,Host
 SG_ BATT_inhContPower_0 : 30|1@1+ (1,0) [0|1] "" Battery,Host
 SG_ BATT_inhChargeEntry_0 : 19|1@1+ (1,0) [0|1] "" Battery,Host
 SG_ BATT_inhCharge_0 : 20|1@1+ (1,0) [0|1] "" Battery,Host
 SG_ BATT_modPackState_0 : 8|4@1+ (1,0) [0|15] "" Battery,Host
 SG_ BATT_modChildState_0 : 3|4@1+ (1,0) [0|15] "" Battery,Host
 SG_ BATT_modParentState_0 : 0|3@1+ (1,0) [0|4] "" Battery,Host

BO_ 2566851319 BATT_modStatus_1: 8 Battery
 SG_ BATT_modUVP_1 : 13|1@1+ (1,0) [0|1] "" Battery
 SG_ BATT_modWeldStat_1 : 12|1@1+ (1,0) [0|1] "" Battery
 SG_ BATT_modNumModsDataValid_1 : 60|4@1+ (1,0) [0|15] "" Battery,Host
 SG_ BATT_modNumModsOnNetwork_1 : 52|4@1+ (1,0) [0|15] "" Battery,Host
 SG_ BATT_modNumModsOnHvBus_1 : 56|4@1+ (1,0) [0|15] "" Battery,Host
 SG_ BATT_modNumModsConfigured_1 : 48|4@1+ (1,0) [0|15] "" Battery,Host
 SG_ BATT_ArbitrationComplete_1 : 15|1@1+ (1,0) [0|1] "" Battery,Host
 SG_ BATT_modStateRequested_1 : 46|2@1+ (1,0) [0|3] "" Battery,Host
 SG_ BATT_modDataValid_1 : 7|1@1+ (1,0) [0|1] "" Battery,Host
 SG_ BATT_prechargeState_1 : 43|3@1+ (1,0) [0|7] "" Battery,Host
 SG_ BATT_fetPchgCommand_1 : 42|1@1+ (1,0) [0|1] "" Battery,Host
 SG_ BATT_fetDsgCommand_1 : 40|1@1+ (1,0) [0|1] "" Battery,Host
 SG_ BATT_fetChgCommand_1 : 41|1@1+ (1,0) [0|1] "" Battery,Host
 SG_ BATT_fetDsgStatus_1 : 36|4@1+ (1,0) [0|15] "" Battery,Host
 SG_ BATT_fetChgStatus_1 : 32|4@1+ (1,0) [0|15] "" Battery,Host
 SG_ BATT_timeRampdown_1 : 24|6@1+ (1,0) [0|63] "seconds" Battery,Host
 SG_ BATT_inhRegen_1 : 31|1@1+ (1,0) [0|1] "" Battery,Host
 SG_ BATT_inhFullPower_1 : 23|1@1+ (1,0) [0|1] "" Battery,Host
 SG_ BATT_inhDriveEntry_1 : 22|1@1+ (1,0) [0|1] "" Battery,Host
 SG_ BATT_inhDrive_1 : 21|1@1+ (1,0) [0|1] "" Battery,Host
 SG_ BATT_inhContPower_1 : 30|1@1+ (1,0) [0|1] "" Battery,Host
 SG_ BATT_inhChargeEntry_1 : 19|1@1+ (1,0) [0|1] "" Battery,Host
 SG_ BATT_inhCharge_1 : 20|1@1+ (1,0) [0|1] "" Battery,Host
 SG_ BATT_modPackState_1 : 8|4@1+ (1,0) [0|15] "" Battery,Host
 SG_ BATT_modChildState_1 : 3|4@1+ (1,0) [0|15] "" Battery,Host
 SG_ BATT_modParentState_1 : 0|3@1+ (1,0) [0|4] "" Battery,Host

BO_ 2566851320 BATT_modStatus_2: 8 Battery
 SG_ BATT_modUVP_2 : 13|1@1+ (1,0) [0|1] "" Battery
 SG_ BATT_modWeldStat_2 : 12|1@1+ (1,0) [0|1] "" Battery
 SG_ BATT_modNumModsDataValid_2 : 60|4@1+ (1,0) [0|15] "" Battery,Host
 SG_ BATT_modNumModsOnNetwork_2 : 52|4@1+ (1,0) [0|15] "" Battery,Host
 SG_ BATT_modNumModsOnHvBus_2 : 56|4@1+ (1,0) [0|15] "" Battery,Host
 SG_ BATT_modNumModsConfigured_2 : 48|4@1+ (1,0) [0|15] "" Battery,Host
 SG_ BATT_ArbitrationComplete_2 : 15|1@1+ (1,0) [0|1] "" Battery,Host
 SG_ BATT_modStateRequested_2 : 46|2@1+ (1,0) [0|3] "" Battery,Host
 SG_ BATT_modDataValid_2 : 7|1@1+ (1,0) [0|1] "" Battery,Host
 SG_ BATT_prechargeState_2 : 43|3@1+ (1,0) [0|7] "" Battery,Host
 SG_ BATT_fetPchgCommand_2 : 42|1@1+ (1,0) [0|1] "" Battery,Host
 SG_ BATT_fetDsgCommand_2 : 40|1@1+ (1,0) [0|1] "" Battery,Host
 SG_ BATT_fetChgCommand_2 : 41|1@1+ (1,0) [0|1] "" Battery,Host
 SG_ BATT_fetDsgStatus_2 : 36|4@1+ (1,0) [0|15] "" Battery,Host
 SG_ BATT_fetChgStatus_2 : 32|4@1+ (1,0) [0|15] "" Battery,Host
 SG_ BATT_timeRampdown_2 : 24|6@1+ (1,0) [0|63] "seconds" Battery,Host
 SG_ BATT_inhRegen_2 : 31|1@1+ (1,0) [0|1] "" Battery,Host
 SG_ BATT_inhFullPower_2 : 23|1@1+ (1,0) [0|1] "" Battery,Host
 SG_ BATT_inhDriveEntry_2 : 22|1@1+ (1,0) [0|1] "" Battery,Host
 SG_ BATT_inhDrive_2 : 21|1@1+ (1,0) [0|1] "" Battery,Host
 SG_ BATT_inhContPower_2 : 30|1@1+ (1,0) [0|1] "" Battery,Host
 SG_ BATT_inhChargeEntry_2 : 19|1@1+ (1,0) [0|1] "" Battery,Host
 SG_ BATT_inhCharge_2 : 20|1@1+ (1,0) [0|1] "" Battery,Host
 SG_ BATT_modPackState_2 : 8|4@1+ (1,0) [0|15] "" Battery,Host
 SG_ BATT_modChildState_2 : 3|4@1+ (1,0) [0|15] "" Battery,Host
 SG_ BATT_modParentState_2 : 0|3@1+ (1,0) [0|4] "" Battery,Host

BO_ 2566851321 BATT_modStatus_3: 8 Battery
 SG_ BATT_modUVP_3 : 13|1@1+ (1,0) [0|1] "" Battery
 SG_ BATT_modWeldStat_3 : 12|1@1+ (1,0) [0|1] "" Battery
 SG_ BATT_modNumModsDataValid_3 : 60|4@1+ (1,0) [0|15] "" Battery,Host
 SG_ BATT_modNumModsOnNetwork_3 : 52|4@1+ (1,0) [0|15] "" Battery,Host
 SG_ BATT_modNumModsOnHvBus_3 : 56|4@1+ (1,0) [0|15] "" Battery,Host
 SG_ BATT_modNumModsConfigured_3 : 48|4@1+ (1,0) [0|15] "" Battery,Host
 SG_ BATT_ArbitrationComplete_3 : 15|1@1+ (1,0) [0|1] "" Battery,Host
 SG_ BATT_modStateRequested_3 : 46|2@1+ (1,0) [0|3] "" Battery,Host
 SG_ BATT_modDataValid_3 : 7|1@1+ (1,0) [0|1] "" Battery,Host
 SG_ BATT_prechargeState_3 : 43|3@1+ (1,0) [0|7] "" Battery,Host
 SG_ BATT_fetPchgCommand_3 : 42|1@1+ (1,0) [0|1] "" Battery,Host
 SG_ BATT_fetDsgCommand_3 : 40|1@1+ (1,0) [0|1] "" Battery,Host
 SG_ BATT_fetChgCommand_3 : 41|1@1+ (1,0) [0|1] "" Battery,Host
 SG_ BATT_fetDsgStatus_3 : 36|4@1+ (1,0) [0|15] "" Battery,Host
 SG_ BATT_fetChgStatus_3 : 32|4@1+ (1,0) [0|15] "" Battery,Host
 SG_ BATT_timeRampdown_3 : 24|6@1+ (1,0) [0|63] "seconds" Battery,Host
 SG_ BATT_inhRegen_3 : 31|1@1+ (1,0) [0|1] "" Battery,Host
 SG_ BATT_inhFullPower_3 : 23|1@1+ (1,0) [0|1] "" Battery,Host
 SG_ BATT_inhDriveEntry_3 : 22|1@1+ (1,0) [0|1] "" Battery,Host
 SG_ BATT_inhDrive_3 : 21|1@1+ (1,0) [0|1] "" Battery,Host
 SG_ BATT_inhContPower_3 : 30|1@1+ (1,0) [0|1] "" Battery,Host
 SG_ BATT_inhChargeEntry_3 : 19|1@1+ (1,0) [0|1] "" Battery,Host
 SG_ BATT_inhCharge_3 : 20|1@1+ (1,0) [0|1] "" Battery,Host
 SG_ BATT_modPackState_3 : 8|4@1+ (1,0) [0|15] "" Battery,Host
 SG_ BATT_modChildState_3 : 3|4@1+ (1,0) [0|15] "" Battery,Host
 SG_ BATT_modParentState_3 : 0|3@1+ (1,0) [0|4] "" Battery,Host

BO_ 2566851322 BATT_modStatus_4: 8 Battery
 SG_ BATT_modUVP_4 : 13|1@1+ (1,0) [0|1] "" Battery
 SG_ BATT_modWeldStat_4 : 12|1@1+ (1,0) [0|1] "" Battery
 SG_ BATT_modNumModsDataValid_4 : 60|4@1+ (1,0) [0|15] "" Battery,Host
 SG_ BATT_modNumModsOnNetwork_4 : 52|4@1+ (1,0) [0|15] "" Battery,Host
 SG_ BATT_modNumModsOnHvBus_4 : 56|4@1+ (1,0) [0|15] "" Battery,Host
 SG_ BATT_modNumModsConfigured_4 : 48|4@1+ (1,0) [0|15] "" Battery,Host
 SG_ BATT_ArbitrationComplete_4 : 15|1@1+ (1,0) [0|1] "" Battery,Host
 SG_ BATT_modStateRequested_4 : 46|2@1+ (1,0) [0|3] "" Battery,Host
 SG_ BATT_modDataValid_4 : 7|1@1+ (1,0) [0|1] "" Battery,Host
 SG_ BATT_prechargeState_4 : 43|3@1+ (1,0) [0|7] "" Battery,Host
 SG_ BATT_fetPchgCommand_4 : 42|1@1+ (1,0) [0|1] "" Battery,Host
 SG_ BATT_fetDsgCommand_4 : 40|1@1+ (1,0) [0|1] "" Battery,Host
 SG_ BATT_fetChgCommand_4 : 41|1@1+ (1,0) [0|1] "" Battery,Host
 SG_ BATT_fetDsgStatus_4 : 36|4@1+ (1,0) [0|15] "" Battery,Host
 SG_ BATT_fetChgStatus_4 : 32|4@1+ (1,0) [0|15] "" Battery,Host
 SG_ BATT_timeRampdown_4 : 24|6@1+ (1,0) [0|63] "seconds" Battery,Host
 SG_ BATT_inhRegen_4 : 31|1@1+ (1,0) [0|1] "" Battery,Host
 SG_ BATT_inhFullPower_4 : 23|1@1+ (1,0) [0|1] "" Battery,Host
 SG_ BATT_inhDriveEntry_4 : 22|1@1+ (1,0) [0|1] "" Battery,Host
 SG_ BATT_inhDrive_4 : 21|1@1+ (1,0) [0|1] "" Battery,Host
 SG_ BATT_inhContPower_4 : 30|1@1+ (1,0) [0|1] "" Battery,Host
 SG_ BATT_inhChargeEntry_4 : 19|1@1+ (1,0) [0|1] "" Battery,Host
 SG_ BATT_inhCharge_4 : 20|1@1+ (1,0) [0|1] "" Battery,Host
 SG_ BATT_modPackState_4 : 8|4@1+ (1,0) [0|15] "" Battery,Host
 SG_ BATT_modChildState_4 : 3|4@1+ (1,0) [0|15] "" Battery,Host
 SG_ BATT_modParentState_4 : 0|3@1+ (1,0) [0|4] "" Battery,Host

BO_ 2566851323 BATT_modStatus_5: 8 Battery
 SG_ BATT_modUVP_5 : 13|1@1+ (1,0) [0|1] "" Battery
 SG_ BATT_modWeldStat_5 : 12|1@1+ (1,0) [0|1] "" Battery
 SG_ BATT_modNumModsDataValid_5 : 60|4@1+ (1,0) [0|15] "" Battery,Host
 SG_ BATT_modNumModsOnNetwork_5 : 52|4@1+ (1,0) [0|15] "" Battery,Host
 SG_ BATT_modNumModsOnHvBus_5 : 56|4@1+ (1,0) [0|15] "" Battery,Host
 SG_ BATT_modNumModsConfigured_5 : 48|4@1+ (1,0) [0|15] "" Battery,Host
 SG_ BATT_ArbitrationComplete_5 : 15|1@1+ (1,0) [0|1] "" Battery,Host
 SG_ BATT_modStateRequested_5 : 46|2@1+ (1,0) [0|3] "" Battery,Host
 SG_ BATT_modDataValid_5 : 7|1@1+ (1,0) [0|1] "" Battery,Host
 SG_ BATT_prechargeState_5 : 43|3@1+ (1,0) [0|7] "" Battery,Host
 SG_ BATT_fetPchgCommand_5 : 42|1@1+ (1,0) [0|1] "" Battery,Host
 SG_ BATT_fetDsgCommand_5 : 40|1@1+ (1,0) [0|1] "" Battery,Host
 SG_ BATT_fetChgCommand_5 : 41|1@1+ (1,0) [0|1] "" Battery,Host
 SG_ BATT_fetDsgStatus_5 : 36|4@1+ (1,0) [0|15] "" Battery,Host
 SG_ BATT_fetChgStatus_5 : 32|4@1+ (1,0) [0|15] "" Battery,Host
 SG_ BATT_timeRampdown_5 : 24|6@1+ (1,0) [0|63] "seconds" Battery,Host
 SG_ BATT_inhRegen_5 : 31|1@1+ (1,0) [0|1] "" Battery,Host
 SG_ BATT_inhFullPower_5 : 23|1@1+ (1,0) [0|1] "" Battery,Host
 SG_ BATT_inhDriveEntry_5 : 22|1@1+ (1,0) [0|1] "" Battery,Host
 SG_ BATT_inhDrive_5 : 21|1@1+ (1,0) [0|1] "" Battery,Host
 SG_ BATT_inhContPower_5 : 30|1@1+ (1,0) [0|1] "" Battery,Host
 SG_ BATT_inhChargeEntry_5 : 19|1@1+ (1,0) [0|1] "" Battery,Host
 SG_ BATT_inhCharge_5 : 20|1@1+ (1,0) [0|1] "" Battery,Host
 SG_ BATT_modPackState_5 : 8|4@1+ (1,0) [0|15] "" Battery,Host
 SG_ BATT_modChildState_5 : 3|4@1+ (1,0) [0|15] "" Battery,Host
 SG_ BATT_modParentState_5 : 0|3@1+ (1,0) [0|4] "" Battery,Host

BO_ 2566851324 BATT_modStatus_6: 8 Battery
 SG_ BATT_modUVP_6 : 13|1@1+ (1,0) [0|1] "" Battery
 SG_ BATT_modWeldStat_6 : 12|1@1+ (1,0) [0|1] "" Battery
 SG_ BATT_modNumModsDataValid_6 : 60|4@1+ (1,0) [0|15] "" Battery,Host
 SG_ BATT_modNumModsOnNetwork_6 : 52|4@1+ (1,0) [0|15] "" Battery,Host
 SG_ BATT_modNumModsOnHvBus_6 : 56|4@1+ (1,0) [0|15] "" Battery,Host
 SG_ BATT_modNumModsConfigured_6 : 48|4@1+ (1,0) [0|15] "" Battery,Host
 SG_ BATT_ArbitrationComplete_6 : 15|1@1+ (1,0) [0|1] "" Battery,Host
 SG_ BATT_modStateRequested_6 : 46|2@1+ (1,0) [0|3] "" Battery,Host
 SG_ BATT_modDataValid_6 : 7|1@1+ (1,0) [0|1] "" Battery,Host
 SG_ BATT_prechargeState_6 : 43|3@1+ (1,0) [0|7] "" Battery,Host
 SG_ BATT_fetPchgCommand_6 : 42|1@1+ (1,0) [0|1] "" Battery,Host
 SG_ BATT_fetDsgCommand_6 : 40|1@1+ (1,0) [0|1] "" Battery,Host
 SG_ BATT_fetChgCommand_6 : 41|1@1+ (1,0) [0|1] "" Battery,Host
 SG_ BATT_fetDsgStatus_6 : 36|4@1+ (1,0) [0|15] "" Battery,Host
 SG_ BATT_fetChgStatus_6 : 32|4@1+ (1,0) [0|15] "" Battery,Host
 SG_ BATT_timeRampdown_6 : 24|6@1+ (1,0) [0|63] "seconds" Battery,Host
 SG_ BATT_inhRegen_6 : 31|1@1+ (1,0) [0|1] "" Battery,Host
 SG_ BATT_inhFullPower_6 : 23|1@1+ (1,0) [0|1] "" Battery,Host
 SG_ BATT_inhDriveEntry_6 : 22|1@1+ (1,0) [0|1] "" Battery,Host
 SG_ BATT_inhDrive_6 : 21|1@1+ (1,0) [0|1] "" Battery,Host
 SG_ BATT_inhContPower_6 : 30|1@1+ (1,0) [0|1] "" Battery,Host
 SG_ BATT_inhChargeEntry_6 : 19|1@1+ (1,0) [0|1] "" Battery,Host
 SG_ BATT_inhCharge_6 : 20|1@1+ (1,0) [0|1] "" Battery,Host
 SG_ BATT_modPackState_6 : 8|4@1+ (1,0) [0|15] "" Battery,Host
 SG_ BATT_modChildState_6 : 3|4@1+ (1,0) [0|15] "" Battery,Host
 SG_ BATT_modParentState_6 : 0|3@1+ (1,0) [0|4] "" Battery,Host

BO_ 2566851325 BATT_modStatus_7: 8 Battery
 SG_ BATT_modUVP_7 : 13|1@1+ (1,0) [0|1] "" Battery
 SG_ BATT_modWeldStat_7 : 12|1@1+ (1,0) [0|1] "" Battery
 SG_ BATT_modNumModsDataValid_7 : 60|4@1+ (1,0) [0|15] "" Battery,Host
 SG_ BATT_modNumModsOnNetwork_7 : 52|4@1+ (1,0) [0|15] "" Battery,Host
 SG_ BATT_modNumModsOnHvBus_7 : 56|4@1+ (1,0) [0|15] "" Battery,Host
 SG_ BATT_modNumModsConfigured_7 : 48|4@1+ (1,0) [0|15] "" Battery,Host
 SG_ BATT_ArbitrationComplete_7 : 15|1@1+ (1,0) [0|1] "" Battery,Host
 SG_ BATT_modStateRequested_7 : 46|2@1+ (1,0) [0|3] "" Battery,Host
 SG_ BATT_modDataValid_7 : 7|1@1+ (1,0) [0|1] "" Battery,Host
 SG_ BATT_prechargeState_7 : 43|3@1+ (1,0) [0|7] "" Battery,Host
 SG_ BATT_fetPchgCommand_7 : 42|1@1+ (1,0) [0|1] "" Battery,Host
 SG_ BATT_fetDsgCommand_7 : 40|1@1+ (1,0) [0|1] "" Battery,Host
 SG_ BATT_fetChgCommand_7 : 41|1@1+ (1,0) [0|1] "" Battery,Host
 SG_ BATT_fetDsgStatus_7 : 36|4@1+ (1,0) [0|15] "" Battery,Host
 SG_ BATT_fetChgStatus_7 : 32|4@1+ (1,0) [0|15] "" Battery,Host
 SG_ BATT_timeRampdown_7 : 24|6@1+ (1,0) [0|63] "seconds" Battery,Host
 SG_ BATT_inhRegen_7 : 31|1@1+ (1,0) [0|1] "" Battery,Host
 SG_ BATT_inhFullPower_7 : 23|1@1+ (1,0) [0|1] "" Battery,Host
 SG_ BATT_inhDriveEntry_7 : 22|1@1+ (1,0) [0|1] "" Battery,Host
 SG_ BATT_inhDrive_7 : 21|1@1+ (1,0) [0|1] "" Battery,Host
 SG_ BATT_inhContPower_7 : 30|1@1+ (1,0) [0|1] "" Battery,Host
 SG_ BATT_inhChargeEntry_7 : 19|1@1+ (1,0) [0|1] "" Battery,Host
 SG_ BATT_inhCharge_7 : 20|1@1+ (1,0) [0|1] "" Battery,Host
 SG_ BATT_modPackState_7 : 8|4@1+ (1,0) [0|15] "" Battery,Host
 SG_ BATT_modChildState_7 : 3|4@1+ (1,0) [0|15] "" Battery,Host
 SG_ BATT_modParentState_7 : 0|3@1+ (1,0) [0|4] "" Battery,Host

BO_ 2566851326 BATT_modStatus_8: 8 Battery
 SG_ BATT_modUVP_8 : 13|1@1+ (1,0) [0|1] "" Battery
 SG_ BATT_modWeldStat_8 : 12|1@1+ (1,0) [0|1] "" Battery
 SG_ BATT_modNumModsDataValid_8 : 60|4@1+ (1,0) [0|15] "" Battery,Host
 SG_ BATT_modNumModsOnNetwork_8 : 52|4@1+ (1,0) [0|15] "" Battery,Host
 SG_ BATT_modNumModsOnHvBus_8 : 56|4@1+ (1,0) [0|15] "" Battery,Host
 SG_ BATT_modNumModsConfigured_8 : 48|4@1+ (1,0) [0|15] "" Battery,Host
 SG_ BATT_ArbitrationComplete_8 : 15|1@1+ (1,0) [0|1] "" Battery,Host
 SG_ BATT_modStateRequested_8 : 46|2@1+ (1,0) [0|3] "" Battery,Host
 SG_ BATT_modDataValid_8 : 7|1@1+ (1,0) [0|1] "" Battery,Host
 SG_ BATT_prechargeState_8 : 43|3@1+ (1,0) [0|7] "" Battery,Host
 SG_ BATT_fetPchgCommand_8 : 42|1@1+ (1,0) [0|1] "" Battery,Host
 SG_ BATT_fetDsgCommand_8 : 40|1@1+ (1,0) [0|1] "" Battery,Host
 SG_ BATT_fetChgCommand_8 : 41|1@1+ (1,0) [0|1] "" Battery,Host
 SG_ BATT_fetDsgStatus_8 : 36|4@1+ (1,0) [0|15] "" Battery,Host
 SG_ BATT_fetChgStatus_8 : 32|4@1+ (1,0) [0|15] "" Battery,Host
 SG_ BATT_timeRampdown_8 : 24|6@1+ (1,0) [0|63] "seconds" Battery,Host
 SG_ BATT_inhRegen_8 : 31|1@1+ (1,0) [0|1] "" Battery,Host
 SG_ BATT_inhFullPower_8 : 23|1@1+ (1,0) [0|1] "" Battery,Host
 SG_ BATT_inhDriveEntry_8 : 22|1@1+ (1,0) [0|1] "" Battery,Host
 SG_ BATT_inhDrive_8 : 21|1@1+ (1,0) [0|1] "" Battery,Host
 SG_ BATT_inhContPower_8 : 30|1@1+ (1,0) [0|1] "" Battery,Host
 SG_ BATT_inhChargeEntry_8 : 19|1@1+ (1,0) [0|1] "" Battery,Host
 SG_ BATT_inhCharge_8 : 20|1@1+ (1,0) [0|1] "" Battery,Host
 SG_ BATT_modPackState_8 : 8|4@1+ (1,0) [0|15] "" Battery,Host
 SG_ BATT_modChildState_8 : 3|4@1+ (1,0) [0|15] "" Battery,Host
 SG_ BATT_modParentState_8 : 0|3@1+ (1,0) [0|4] "" Battery,Host

BO_ 2566851327 BATT_modStatus_9: 8 Battery
 SG_ BATT_modUVP_9 : 13|1@1+ (1,0) [0|1] "" Battery
 SG_ BATT_modWeldStat_9 : 12|1@1+ (1,0) [0|1] "" Battery
 SG_ BATT_modNumModsDataValid_9 : 60|4@1+ (1,0) [0|15] "" Battery,Host
 SG_ BATT_modNumModsOnNetwork_9 : 52|4@1+ (1,0) [0|15] "" Battery,Host
 SG_ BATT_modNumModsOnHvBus_9 : 56|4@1+ (1,0) [0|15] "" Battery,Host
 SG_ BATT_modNumModsConfigured_9 : 48|4@1+ (1,0) [0|15] "" Battery,Host
 SG_ BATT_ArbitrationComplete_9 : 15|1@1+ (1,0) [0|1] "" Battery,Host
 SG_ BATT_modStateRequested_9 : 46|2@1+ (1,0) [0|3] "" Battery,Host
 SG_ BATT_modDataValid_9 : 7|1@1+ (1,0) [0|1] "" Battery,Host
 SG_ BATT_prechargeState_9 : 43|3@1+ (1,0) [0|7] "" Battery,Host
 SG_ BATT_fetPchgCommand_9 : 42|1@1+ (1,0) [0|1] "" Battery,Host
 SG_ BATT_fetDsgCommand_9 : 40|1@1+ (1,0) [0|1] "" Battery,Host
 SG_ BATT_fetChgCommand_9 : 41|1@1+ (1,0) [0|1] "" Battery,Host
 SG_ BATT_fetDsgStatus_9 : 36|4@1+ (1,0) [0|15] "" Battery,Host
 SG_ BATT_fetChgStatus_9 : 32|4@1+ (1,0) [0|15] "" Battery,Host
 SG_ BATT_timeRampdown_9 : 24|6@1+ (1,0) [0|63] "seconds" Battery,Host
 SG_ BATT_inhRegen_9 : 31|1@1+ (1,0) [0|1] "" Battery,Host
 SG_ BATT_inhFullPower_9 : 23|1@1+ (1,0) [0|1] "" Battery,Host
 SG_ BATT_inhDriveEntry_9 : 22|1@1+ (1,0) [0|1] "" Battery,Host
 SG_ BATT_inhDrive_9 : 21|1@1+ (1,0) [0|1] "" Battery,Host
 SG_ BATT_inhContPower_9 : 30|1@1+ (1,0) [0|1] "" Battery,Host
 SG_ BATT_inhChargeEntry_9 : 19|1@1+ (1,0) [0|1] "" Battery,Host
 SG_ BATT_inhCharge_9 : 20|1@1+ (1,0) [0|1] "" Battery,Host
 SG_ BATT_modPackState_9 : 8|4@1+ (1,0) [0|15] "" Battery,Host
 SG_ BATT_modChildState_9 : 3|4@1+ (1,0) [0|15] "" Battery,Host
 SG_ BATT_modParentState_9 : 0|3@1+ (1,0) [0|4] "" Battery,Host

BO_ 2566851830 BATT_modHvStatus_0: 8 Battery
 SG_ BATT_vMod_0 : 34|15@1+ (0.01,0) [0|70] "V" Battery,Host
 SG_ BATT_vModSumOfCells_0 : 49|15@1+ (0.01,0) [0|70] "V" Battery,Host
 SG_ BATT_iMod_0 : 17|17@1- (0.01,-400) [-1055.36|255.35] "A" Battery,Host
 SG_ BATT_iModFiltered_0 : 0|17@1- (0.01,-400) [-1055.36|255.35] "A" Battery,Host

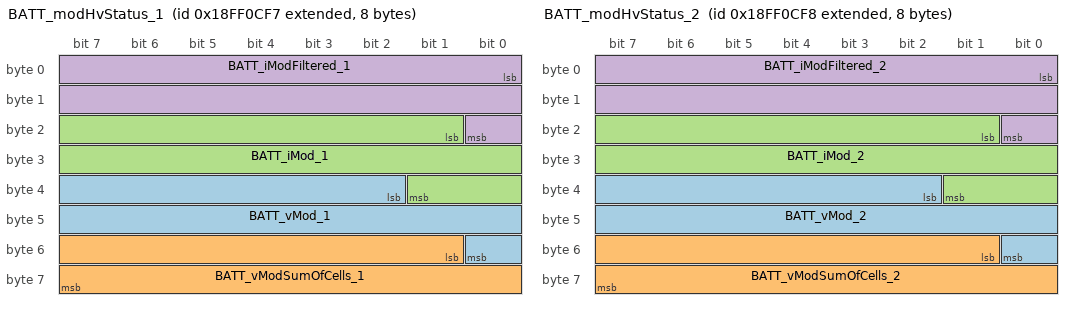
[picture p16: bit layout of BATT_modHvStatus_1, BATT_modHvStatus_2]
BO_ 2566851831 BATT_modHvStatus_1: 8 Battery
 SG_ BATT_vMod_1 : 34|15@1+ (0.01,0) [0|70] "V" Battery,Host
 SG_ BATT_vModSumOfCells_1 : 49|15@1+ (0.01,0) [0|70] "V" Battery,Host
 SG_ BATT_iMod_1 : 17|17@1- (0.01,-400) [-1055.36|255.35] "A" Battery,Host
 SG_ BATT_iModFiltered_1 : 0|17@1- (0.01,-400) [-1055.36|255.35] "A" Battery,Host

BO_ 2566851832 BATT_modHvStatus_2: 8 Battery
 SG_ BATT_vMod_2 : 34|15@1+ (0.01,0) [0|70] "V" Battery,Host
 SG_ BATT_vModSumOfCells_2 : 49|15@1+ (0.01,0) [0|70] "V" Battery,Host
 SG_ BATT_iMod_2 : 17|17@1- (0.01,-400) [-1055.36|255.35] "A" Battery,Host
 SG_ BATT_iModFiltered_2 : 0|17@1- (0.01,-400) [-1055.36|255.35] "A" Battery,Host

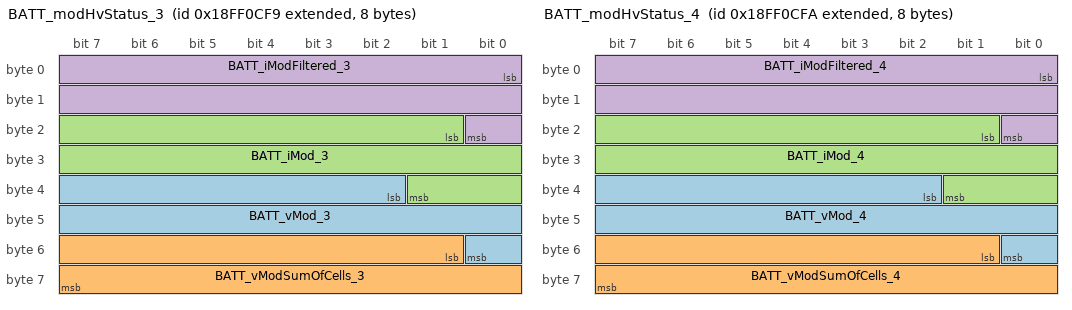
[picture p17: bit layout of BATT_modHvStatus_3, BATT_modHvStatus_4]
BO_ 2566851833 BATT_modHvStatus_3: 8 Battery
 SG_ BATT_vMod_3 : 34|15@1+ (0.01,0) [0|70] "V" Battery,Host
 SG_ BATT_vModSumOfCells_3 : 49|15@1+ (0.01,0) [0|70] "V" Battery,Host
 SG_ BATT_iMod_3 : 17|17@1- (0.01,-400) [-1055.36|255.35] "A" Battery,Host
 SG_ BATT_iModFiltered_3 : 0|17@1- (0.01,-400) [-1055.36|255.35] "A" Battery,Host

BO_ 2566851834 BATT_modHvStatus_4: 8 Battery
 SG_ BATT_vMod_4 : 34|15@1+ (0.01,0) [0|70] "V" Battery,Host
 SG_ BATT_vModSumOfCells_4 : 49|15@1+ (0.01,0) [0|70] "V" Battery,Host
 SG_ BATT_iMod_4 : 17|17@1- (0.01,-400) [-1055.36|255.35] "A" Battery,Host
 SG_ BATT_iModFiltered_4 : 0|17@1- (0.01,-400) [-1055.36|255.35] "A" Battery,Host

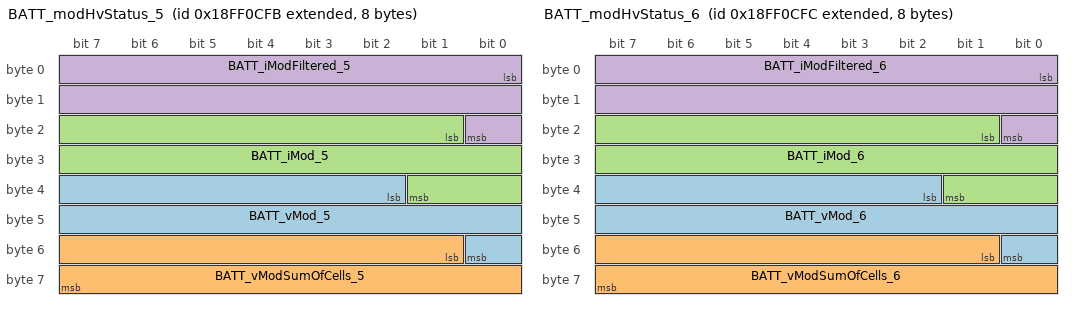
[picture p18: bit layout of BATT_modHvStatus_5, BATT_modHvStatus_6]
BO_ 2566851835 BATT_modHvStatus_5: 8 Battery
 SG_ BATT_vMod_5 : 34|15@1+ (0.01,0) [0|70] "V" Battery,Host
 SG_ BATT_vModSumOfCells_5 : 49|15@1+ (0.01,0) [0|70] "V" Battery,Host
 SG_ BATT_iMod_5 : 17|17@1- (0.01,-400) [-1055.36|255.35] "A" Battery,Host
 SG_ BATT_iModFiltered_5 : 0|17@1- (0.01,-400) [-1055.36|255.35] "A" Battery,Host

BO_ 2566851836 BATT_modHvStatus_6: 8 Battery
 SG_ BATT_vMod_6 : 34|15@1+ (0.01,0) [0|70] "V" Battery,Host
 SG_ BATT_vModSumOfCells_6 : 49|15@1+ (0.01,0) [0|70] "V" Battery,Host
 SG_ BATT_iMod_6 : 17|17@1- (0.01,-400) [-1055.36|255.35] "A" Battery,Host
 SG_ BATT_iModFiltered_6 : 0|17@1- (0.01,-400) [-1055.36|255.35] "A" Battery,Host

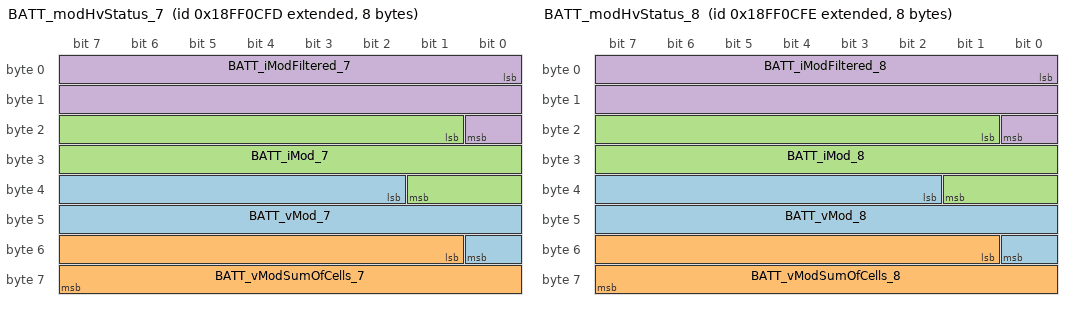
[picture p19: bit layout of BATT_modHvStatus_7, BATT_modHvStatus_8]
BO_ 2566851837 BATT_modHvStatus_7: 8 Battery
 SG_ BATT_vMod_7 : 34|15@1+ (0.01,0) [0|70] "V" Battery,Host
 SG_ BATT_vModSumOfCells_7 : 49|15@1+ (0.01,0) [0|70] "V" Battery,Host
 SG_ BATT_iMod_7 : 17|17@1- (0.01,-400) [-1055.36|255.35] "A" Battery,Host
 SG_ BATT_iModFiltered_7 : 0|17@1- (0.01,-400) [-1055.36|255.35] "A" Battery,Host

BO_ 2566851838 BATT_modHvStatus_8: 8 Battery
 SG_ BATT_vMod_8 : 34|15@1+ (0.01,0) [0|70] "V" Battery,Host
 SG_ BATT_vModSumOfCells_8 : 49|15@1+ (0.01,0) [0|70] "V" Battery,Host
 SG_ BATT_iMod_8 : 17|17@1- (0.01,-400) [-1055.36|255.35] "A" Battery,Host
 SG_ BATT_iModFiltered_8 : 0|17@1- (0.01,-400) [-1055.36|255.35] "A" Battery,Host

CM_ "Version 0.2.0";
CM_ BO_ 2552103157 "Battery limits";
CM_ BO_ 2565341429 "DM11- Acknowledgement";
CM_ SG_ 2565341429 BATT_dm11Resv "Reserved Bytes";
CM_ SG_ 2565472256 HOST_requested_pgn "Requested PGN";
CM_ BO_ 2565472502 "Diagnostic Message Request.";
CM_ SG_ 2565472502 BATT_dm1ReqPgn_0 "Requested PGN
DM2 - 0x00FECB
DM11 - 0x00FED3";
CM_ BO_ 2565472503 "Diagnostic Message Request.";
CM_ SG_ 2565472503 BATT_dm1ReqPgn_1 "Requested PGN
DM2 - 0x00FECB
DM11 - 0x00FED3";
CM_ BO_ 2565472504 "Diagnostic Message Request.";
CM_ SG_ 2565472504 BATT_dm1ReqPgn_2 "Requested PGN
DM2 - 0x00FECB
DM11 - 0x00FED3";
CM_ BO_ 2565472505 "Diagnostic Message Request.";
CM_ SG_ 2565472505 BATT_dm1ReqPgn_3 "Requested PGN
DM2 - 0x00FECB
DM11 - 0x00FED3";
CM_ BO_ 2565472506 "Diagnostic Message Request.";
CM_ SG_ 2565472506 BATT_dm1ReqPgn_4 "Requested PGN
DM2 - 0x00FECB
DM11 - 0x00FED3";
CM_ BO_ 2565472507 "Diagnostic Message Request.";
CM_ SG_ 2565472507 BATT_dm1ReqPgn_5 "Requested PGN
DM2 - 0x00FECB
DM11 - 0x00FED3";
CM_ BO_ 2565472508 "Diagnostic Message Request.";
CM_ SG_ 2565472508 BATT_dm1ReqPgn_6 "Requested PGN
DM2 - 0x00FECB
DM11 - 0x00FED3";
CM_ BO_ 2565472509 "Diagnostic Message Request.";
CM_ SG_ 2565472509 BATT_dm1ReqPgn_7 "Requested PGN
DM2 - 0x00FECB
DM11 - 0x00FED3";
CM_ BO_ 2565472510 "Diagnostic Message Request.";
CM_ SG_ 2565472510 BATT_dm1ReqPgn_8 "Requested PGN
DM2 - 0x00FECB
DM11 - 0x00FED3";
CM_ BO_ 2565472511 "Diagnostic Message Request.";
CM_ SG_ 2565472511 BATT_dm1ReqPgn_9 "Requested PGN
DM2 - 0x00FECB
DM11 - 0x00FED3";
CM_ BO_ 2565538038 "Transport protocol message";
CM_ SG_ 2565538038 BATT_dmPayLoad_0 "DM1 Tx protocol Pay Load";
CM_ SG_ 2565538038 BATT_dmSeqNum_0 "DM1 Tx Sequence number
";
CM_ BO_ 2565538039 "Transport protocol message";
CM_ SG_ 2565538039 BATT_dmPayLoad_1 "DM1 Tx protocol Pay Load";
CM_ SG_ 2565538039 BATT_dmSeqNum_1 "DM1 Tx Sequence number
";
CM_ BO_ 2565538040 "Transport protocol message";
CM_ SG_ 2565538040 BATT_dmPayLoad_2 "DM1 Tx protocol Pay Load";
CM_ SG_ 2565538040 BATT_dmSeqNum_2 "DM1 Tx Sequence number
";
CM_ BO_ 2565538041 "Transport protocol message";
CM_ SG_ 2565538041 BATT_dmPayLoad_3 "DM1 Tx protocol Pay Load";
CM_ SG_ 2565538041 BATT_dmSeqNum_3 "DM1 Tx Sequence number
";
CM_ BO_ 2565538042 "Transport protocol message";
CM_ SG_ 2565538042 BATT_dmPayLoad_4 "DM1 Tx protocol Pay Load";
CM_ SG_ 2565538042 BATT_dmSeqNum_4 "DM1 Tx Sequence number
";
CM_ BO_ 2565538043 "Transport protocol message";
CM_ SG_ 2565538043 BATT_dmPayLoad_5 "DM1 Tx protocol Pay Load";
CM_ SG_ 2565538043 BATT_dmSeqNum_5 "DM1 Tx Sequence number
";
CM_ BO_ 2565538044 "Transport protocol message";
CM_ SG_ 2565538044 BATT_dmPayLoad_6 "DM1 Tx protocol Pay Load";
CM_ SG_ 2565538044 BATT_dmSeqNum_6 "DM1 Tx Sequence number
";
CM_ BO_ 2565538045 "Transport protocol message";
CM_ SG_ 2565538045 BATT_dmPayLoad_7 "DM1 Tx protocol Pay Load";
CM_ SG_ 2565538045 BATT_dmSeqNum_7 "DM1 Tx Sequence number
";
CM_ BO_ 2565538046 "Transport protocol message";
CM_ SG_ 2565538046 BATT_dmPayLoad_8 "DM1 Tx protocol Pay Load";
CM_ SG_ 2565538046 BATT_dmSeqNum_8 "DM1 Tx Sequence number
";
CM_ BO_ 2565538047 "Transport protocol message";
CM_ SG_ 2565538047 BATT_dmPayLoad_9 "DM1 Tx protocol Pay Load";
CM_ SG_ 2565538047 BATT_dmSeqNum_9 "DM1 Tx Sequence number
";
CM_ BO_ 2565603574 "DM1- BAM (Broadcast Announcement Message)";
CM_ SG_ 2565603574 BATT_bamResv_0 "Reserved Byte- 0xFF";
CM_ SG_ 2565603574 BATT_bamPgn_0 "PGN - Message Identifier";
CM_ SG_ 2565603574 BATT_bamNumOfPackets_0 "Number of packets";
CM_ SG_ 2565603574 BATT_bamDataLength_0 "Total Data Length sent on transmit protocol - Message size in bytes
";
CM_ SG_ 2565603574 BATT_bamCtrlByte_0 "DM1 Tx Sequence number
";
CM_ BO_ 2565603575 "DM1- BAM (Broadcast Announcement Message)";
CM_ SG_ 2565603575 BATT_bamResv_1 "Reserved Byte- 0xFF";
CM_ SG_ 2565603575 BATT_bamPgn_1 "PGN - Message Identifier";
CM_ SG_ 2565603575 BATT_bamNumOfPackets_1 "Number of packets";
CM_ SG_ 2565603575 BATT_bamDataLength_1 "Total Data Length sent on transmit protocol - Message size in bytes
";
CM_ SG_ 2565603575 BATT_bamCtrlByte_1 "DM1 Tx Sequence number
";
CM_ BO_ 2565603576 "DM1- BAM (Broadcast Announcement Message)";
CM_ SG_ 2565603576 BATT_bamResv_2 "Reserved Byte- 0xFF";
CM_ SG_ 2565603576 BATT_bamPgn_2 "PGN - Message Identifier";
CM_ SG_ 2565603576 BATT_bamNumOfPackets_2 "Number of packets";
CM_ SG_ 2565603576 BATT_bamDataLength_2 "Total Data Length sent on transmit protocol - Message size in bytes
";
CM_ SG_ 2565603576 BATT_bamCtrlByte_2 "DM1 Tx Sequence number
";
CM_ BO_ 2565603577 "DM1- BAM (Broadcast Announcement Message)";
CM_ SG_ 2565603577 BATT_bamResv_3 "Reserved Byte- 0xFF";
CM_ SG_ 2565603577 BATT_bamPgn_3 "PGN - Message Identifier";
CM_ SG_ 2565603577 BATT_bamNumOfPackets_3 "Number of packets";
CM_ SG_ 2565603577 BATT_bamDataLength_3 "Total Data Length sent on transmit protocol - Message size in bytes
";
CM_ SG_ 2565603577 BATT_bamCtrlByte_3 "DM1 Tx Sequence number
";
CM_ BO_ 2565603578 "DM1- BAM (Broadcast Announcement Message)";
CM_ SG_ 2565603578 BATT_bamResv_4 "Reserved Byte- 0xFF";
CM_ SG_ 2565603578 BATT_bamPgn_4 "PGN - Message Identifier";
CM_ SG_ 2565603578 BATT_bamNumOfPackets_4 "Number of packets";
CM_ SG_ 2565603578 BATT_bamDataLength_4 "Total Data Length sent on transmit protocol - Message size in bytes
";
CM_ SG_ 2565603578 BATT_bamCtrlByte_4 "DM1 Tx Sequence number
";
CM_ BO_ 2565603579 "DM1- BAM (Broadcast Announcement Message)";
CM_ SG_ 2565603579 BATT_bamResv_5 "Reserved Byte- 0xFF";
CM_ SG_ 2565603579 BATT_bamPgn_5 "PGN - Message Identifier";
CM_ SG_ 2565603579 BATT_bamNumOfPackets_5 "Number of packets";
CM_ SG_ 2565603579 BATT_bamDataLength_5 "Total Data Length sent on transmit protocol - Message size in bytes
";
CM_ SG_ 2565603579 BATT_bamCtrlByte_5 "DM1 Tx Sequence number
";
CM_ BO_ 2565603580 "DM1- BAM (Broadcast Announcement Message)";
CM_ SG_ 2565603580 BATT_bamResv_6 "Reserved Byte- 0xFF";
CM_ SG_ 2565603580 BATT_bamPgn_6 "PGN - Message Identifier";
CM_ SG_ 2565603580 BATT_bamNumOfPackets_6 "Number of packets";
CM_ SG_ 2565603580 BATT_bamDataLength_6 "Total Data Length sent on transmit protocol - Message size in bytes
";
CM_ SG_ 2565603580 BATT_bamCtrlByte_6 "DM1 Tx Sequence number
";
CM_ BO_ 2565603581 "DM1- BAM (Broadcast Announcement Message)";
CM_ SG_ 2565603581 BATT_bamResv_7 "Reserved Byte- 0xFF";
CM_ SG_ 2565603581 BATT_bamPgn_7 "PGN - Message Identifier";
CM_ SG_ 2565603581 BATT_bamNumOfPackets_7 "Number of packets";
CM_ SG_ 2565603581 BATT_bamDataLength_7 "Total Data Length sent on transmit protocol - Message size in bytes
";
CM_ SG_ 2565603581 BATT_bamCtrlByte_7 "DM1 Tx Sequence number
";
CM_ BO_ 2565603582 "DM1- BAM (Broadcast Announcement Message)";
CM_ SG_ 2565603582 BATT_bamResv_8 "Reserved Byte- 0xFF";
CM_ SG_ 2565603582 BATT_bamPgn_8 "PGN - Message Identifier";
CM_ SG_ 2565603582 BATT_bamNumOfPackets_8 "Number of packets";
CM_ SG_ 2565603582 BATT_bamDataLength_8 "Total Data Length sent on transmit protocol - Message size in bytes
";
CM_ SG_ 2565603582 BATT_bamCtrlByte_8 "DM1 Tx Sequence number
";
CM_ BO_ 2565603583 "DM1- BAM (Broadcast Announcement Message)";
CM_ SG_ 2565603583 BATT_bamResv_9 "Reserved Byte- 0xFF";
CM_ SG_ 2565603583 BATT_bamPgn_9 "PGN - Message Identifier";
CM_ SG_ 2565603583 BATT_bamNumOfPackets_9 "Number of packets";
CM_ SG_ 2565603583 BATT_bamDataLength_9 "Total Data Length sent on transmit protocol - Message size in bytes
";
CM_ SG_ 2565603583 BATT_bamCtrlByte_9 "DM1 Tx Sequence number
";
CM_ BO_ 2566834934 "DM1- Non Transport Protocol
";
CM_ SG_ 2566834934 BATT_dm1SpnMsb_0 "SPN-MSB
";
CM_ SG_ 2566834934 BATT_dm1SpnLsb_0 "SPN-LSB";
CM_ SG_ 2566834934 BATT_dm1SpnIsb_0 "SPN-ISB";
CM_ SG_ 2566834934 BATT_dm1SpnFmi_0 "FMI";
CM_ SG_ 2566834934 BATT_dm1LampStatus_0 "Lamp Status";
CM_ SG_ 2566834934 BATT_dm1FlashLampStatus_0 "Flash Lamp Status";
CM_ SG_ 2566834934 BATT_dm1ConvMethod_0 "Conversion Method
";
CM_ BO_ 2566834935 "DM1- Non Transport Protocol
";
CM_ SG_ 2566834935 BATT_dm1SpnMsb_1 "SPN-MSB
";
CM_ SG_ 2566834935 BATT_dm1SpnLsb_1 "SPN-LSB";
CM_ SG_ 2566834935 BATT_dm1SpnIsb_1 "SPN-ISB";
CM_ SG_ 2566834935 BATT_dm1SpnFmi_1 "FMI";
CM_ SG_ 2566834935 BATT_dm1LampStatus_1 "Lamp Status";
CM_ SG_ 2566834935 BATT_dm1FlashLampStatus_1 "Flash Lamp Status";
CM_ SG_ 2566834935 BATT_dm1ConvMethod_1 "Conversion Method
";
CM_ BO_ 2566834936 "DM1- Non Transport Protocol
";
CM_ SG_ 2566834936 BATT_dm1SpnMsb_2 "SPN-MSB
";
CM_ SG_ 2566834936 BATT_dm1SpnLsb_2 "SPN-LSB";
CM_ SG_ 2566834936 BATT_dm1SpnIsb_2 "SPN-ISB";
CM_ SG_ 2566834936 BATT_dm1SpnFmi_2 "FMI";
CM_ SG_ 2566834936 BATT_dm1LampStatus_2 "Lamp Status";
CM_ SG_ 2566834936 BATT_dm1FlashLampStatus_2 "Flash Lamp Status";
CM_ SG_ 2566834936 BATT_dm1ConvMethod_2 "Conversion Method
";
CM_ BO_ 2566834937 "DM1- Non Transport Protocol
";
CM_ SG_ 2566834937 BATT_dm1SpnMsb_3 "SPN-MSB
";
CM_ SG_ 2566834937 BATT_dm1SpnLsb_3 "SPN-LSB";
CM_ SG_ 2566834937 BATT_dm1SpnIsb_3 "SPN-ISB";
CM_ SG_ 2566834937 BATT_dm1SpnFmi_3 "FMI";
CM_ SG_ 2566834937 BATT_dm1LampStatus_3 "Lamp Status";
CM_ SG_ 2566834937 BATT_dm1FlashLampStatus_3 "Flash Lamp Status";
CM_ SG_ 2566834937 BATT_dm1ConvMethod_3 "Conversion Method
";
CM_ BO_ 2566834938 "DM1- Non Transport Protocol
";
CM_ SG_ 2566834938 BATT_dm1SpnMsb_4 "SPN-MSB
";
CM_ SG_ 2566834938 BATT_dm1SpnLsb_4 "SPN-LSB";
CM_ SG_ 2566834938 BATT_dm1SpnIsb_4 "SPN-ISB";
CM_ SG_ 2566834938 BATT_dm1SpnFmi_4 "FMI";
CM_ SG_ 2566834938 BATT_dm1LampStatus_4 "Lamp Status";
CM_ SG_ 2566834938 BATT_dm1FlashLampStatus_4 "Flash Lamp Status";
CM_ SG_ 2566834938 BATT_dm1ConvMethod_4 "Conversion Method
";
CM_ BO_ 2566834939 "DM1- Non Transport Protocol
";
CM_ SG_ 2566834939 BATT_dm1SpnMsb_5 "SPN-MSB
";
CM_ SG_ 2566834939 BATT_dm1SpnLsb_5 "SPN-LSB";
CM_ SG_ 2566834939 BATT_dm1SpnIsb_5 "SPN-ISB";
CM_ SG_ 2566834939 BATT_dm1SpnFmi_5 "FMI";
CM_ SG_ 2566834939 BATT_dm1LampStatus_5 "Lamp Status";
CM_ SG_ 2566834939 BATT_dm1FlashLampStatus_5 "Flash Lamp Status";
CM_ SG_ 2566834939 BATT_dm1ConvMethod_5 "Conversion Method
";
CM_ BO_ 2566834940 "DM1- Non Transport Protocol
";
CM_ SG_ 2566834940 BATT_dm1SpnMsb_6 "SPN-MSB
";
CM_ SG_ 2566834940 BATT_dm1SpnLsb_6 "SPN-LSB";
CM_ SG_ 2566834940 BATT_dm1SpnIsb_6 "SPN-ISB";
CM_ SG_ 2566834940 BATT_dm1SpnFmi_6 "FMI";
CM_ SG_ 2566834940 BATT_dm1LampStatus_6 "Lamp Status";
CM_ SG_ 2566834940 BATT_dm1FlashLampStatus_6 "Flash Lamp Status";
CM_ SG_ 2566834940 BATT_dm1ConvMethod_6 "Conversion Method
";
CM_ BO_ 2566834941 "DM1- Non Transport Protocol
";
CM_ SG_ 2566834941 BATT_dm1SpnMsb_7 "SPN-MSB
";
CM_ SG_ 2566834941 BATT_dm1SpnLsb_7 "SPN-LSB";
CM_ SG_ 2566834941 BATT_dm1SpnIsb_7 "SPN-ISB";
CM_ SG_ 2566834941 BATT_dm1SpnFmi_7 "FMI";
CM_ SG_ 2566834941 BATT_dm1LampStatus_7 "Lamp Status";
CM_ SG_ 2566834941 BATT_dm1FlashLampStatus_7 "Flash Lamp Status";
CM_ SG_ 2566834941 BATT_dm1ConvMethod_7 "Conversion Method
";
CM_ BO_ 2566834942 "DM1- Non Transport Protocol
";
CM_ SG_ 2566834942 BATT_dm1SpnMsb_8 "SPN-MSB
";
CM_ SG_ 2566834942 BATT_dm1SpnLsb_8 "SPN-LSB";
CM_ SG_ 2566834942 BATT_dm1SpnIsb_8 "SPN-ISB";
CM_ SG_ 2566834942 BATT_dm1SpnFmi_8 "FMI";
CM_ SG_ 2566834942 BATT_dm1LampStatus_8 "Lamp Status";
CM_ SG_ 2566834942 BATT_dm1FlashLampStatus_8 "Flash Lamp Status";
CM_ SG_ 2566834942 BATT_dm1ConvMethod_8 "Conversion Method
";
CM_ BO_ 2566834943 "DM1- Non Transport Protocol
";
CM_ SG_ 2566834943 BATT_dm1SpnMsb_9 "SPN-MSB
";
CM_ SG_ 2566834943 BATT_dm1SpnLsb_9 "SPN-LSB";
CM_ SG_ 2566834943 BATT_dm1SpnIsb_9 "SPN-ISB";
CM_ SG_ 2566834943 BATT_dm1SpnFmi_9 "FMI";
CM_ SG_ 2566834943 BATT_dm1LampStatus_9 "Lamp Status";
CM_ SG_ 2566834943 BATT_dm1FlashLampStatus_9 "Flash Lamp Status";
CM_ SG_ 2566834943 BATT_dm1ConvMethod_9 "Conversion Method
";
CM_ BO_ 2566835190 "DM1- Non Transport Protocol
";
CM_ SG_ 2566835190 BATT_dm2ConvMethod_0 "Conversion Method
";
CM_ SG_ 2566835190 BATT_dm2SpnFmi_0 "FMI";
CM_ SG_ 2566835190 BATT_dm2SpnLsb_0 "SPN-LSB";
CM_ SG_ 2566835190 BATT_dm2SpnIsb_0 "SPN-ISB";
CM_ SG_ 2566835190 BATT_dm2SpnMsb_0 "SPN-MSB
";
CM_ SG_ 2566835190 BATT_dm2FlashLampStatus_0 "Flash Lamp Status";
CM_ SG_ 2566835190 BATT_dm2LampStatus_0 "Lamp Status";
CM_ BO_ 2566835191 "DM1- Non Transport Protocol
";
CM_ SG_ 2566835191 BATT_dm2ConvMethod_1 "Conversion Method
";
CM_ SG_ 2566835191 BATT_dm2SpnFmi_1 "FMI";
CM_ SG_ 2566835191 BATT_dm2SpnLsb_1 "SPN-LSB";
CM_ SG_ 2566835191 BATT_dm2SpnIsb_1 "SPN-ISB";
CM_ SG_ 2566835191 BATT_dm2SpnMsb_1 "SPN-MSB
";
CM_ SG_ 2566835191 BATT_dm2FlashLampStatus_1 "Flash Lamp Status";
CM_ SG_ 2566835191 BATT_dm2LampStatus_1 "Lamp Status";
CM_ BO_ 2566835192 "DM1- Non Transport Protocol
";
CM_ SG_ 2566835192 BATT_dm2ConvMethod_2 "Conversion Method
";
CM_ SG_ 2566835192 BATT_dm2SpnFmi_2 "FMI";
CM_ SG_ 2566835192 BATT_dm2SpnLsb_2 "SPN-LSB";
CM_ SG_ 2566835192 BATT_dm2SpnIsb_2 "SPN-ISB";
CM_ SG_ 2566835192 BATT_dm2SpnMsb_2 "SPN-MSB
";
CM_ SG_ 2566835192 BATT_dm2FlashLampStatus_2 "Flash Lamp Status";
CM_ SG_ 2566835192 BATT_dm2LampStatus_2 "Lamp Status";
CM_ BO_ 2566835193 "DM1- Non Transport Protocol
";
CM_ SG_ 2566835193 BATT_dm2ConvMethod_3 "Conversion Method
";
CM_ SG_ 2566835193 BATT_dm2SpnFmi_3 "FMI";
CM_ SG_ 2566835193 BATT_dm2SpnLsb_3 "SPN-LSB";
CM_ SG_ 2566835193 BATT_dm2SpnIsb_3 "SPN-ISB";
CM_ SG_ 2566835193 BATT_dm2SpnMsb_3 "SPN-MSB
";
CM_ SG_ 2566835193 BATT_dm2FlashLampStatus_3 "Flash Lamp Status";
CM_ SG_ 2566835193 BATT_dm2LampStatus_3 "Lamp Status";
CM_ BO_ 2566835194 "DM1- Non Transport Protocol
";
CM_ SG_ 2566835194 BATT_dm2ConvMethod_4 "Conversion Method
";
CM_ SG_ 2566835194 BATT_dm2SpnFmi_4 "FMI";
CM_ SG_ 2566835194 BATT_dm2SpnLsb_4 "SPN-LSB";
CM_ SG_ 2566835194 BATT_dm2SpnIsb_4 "SPN-ISB";
CM_ SG_ 2566835194 BATT_dm2SpnMsb_4 "SPN-MSB
";
CM_ SG_ 2566835194 BATT_dm2FlashLampStatus_4 "Flash Lamp Status";
CM_ SG_ 2566835194 BATT_dm2LampStatus_4 "Lamp Status";
CM_ BO_ 2566835195 "DM1- Non Transport Protocol
";
CM_ SG_ 2566835195 BATT_dm2ConvMethod_5 "Conversion Method
";
CM_ SG_ 2566835195 BATT_dm2SpnFmi_5 "FMI";
CM_ SG_ 2566835195 BATT_dm2SpnLsb_5 "SPN-LSB";
CM_ SG_ 2566835195 BATT_dm2SpnIsb_5 "SPN-ISB";
CM_ SG_ 2566835195 BATT_dm2SpnMsb_5 "SPN-MSB
";
CM_ SG_ 2566835195 BATT_dm2FlashLampStatus_5 "Flash Lamp Status";
CM_ SG_ 2566835195 BATT_dm2LampStatus_5 "Lamp Status";
CM_ BO_ 2566835196 "DM1- Non Transport Protocol
";
CM_ SG_ 2566835196 BATT_dm2ConvMethod_6 "Conversion Method
";
CM_ SG_ 2566835196 BATT_dm2SpnFmi_6 "FMI";
CM_ SG_ 2566835196 BATT_dm2SpnLsb_6 "SPN-LSB";
CM_ SG_ 2566835196 BATT_dm2SpnIsb_6 "SPN-ISB";
CM_ SG_ 2566835196 BATT_dm2SpnMsb_6 "SPN-MSB
";
CM_ SG_ 2566835196 BATT_dm2FlashLampStatus_6 "Flash Lamp Status";
CM_ SG_ 2566835196 BATT_dm2LampStatus_6 "Lamp Status";
CM_ BO_ 2566835197 "DM1- Non Transport Protocol
";
CM_ SG_ 2566835197 BATT_dm2ConvMethod_7 "Conversion Method
";
CM_ SG_ 2566835197 BATT_dm2SpnFmi_7 "FMI";
CM_ SG_ 2566835197 BATT_dm2SpnLsb_7 "SPN-LSB";
CM_ SG_ 2566835197 BATT_dm2SpnIsb_7 "SPN-ISB";
CM_ SG_ 2566835197 BATT_dm2SpnMsb_7 "SPN-MSB
";
CM_ SG_ 2566835197 BATT_dm2FlashLampStatus_7 "Flash Lamp Status";
CM_ SG_ 2566835197 BATT_dm2LampStatus_7 "Lamp Status";
CM_ BO_ 2566835198 "DM1- Non Transport Protocol
";
CM_ SG_ 2566835198 BATT_dm2ConvMethod_8 "Conversion Method
";
CM_ SG_ 2566835198 BATT_dm2SpnFmi_8 "FMI";
CM_ SG_ 2566835198 BATT_dm2SpnLsb_8 "SPN-LSB";
CM_ SG_ 2566835198 BATT_dm2SpnIsb_8 "SPN-ISB";
CM_ SG_ 2566835198 BATT_dm2SpnMsb_8 "SPN-MSB
";
CM_ SG_ 2566835198 BATT_dm2FlashLampStatus_8 "Flash Lamp Status";
CM_ SG_ 2566835198 BATT_dm2LampStatus_8 "Lamp Status";
CM_ BO_ 2566835199 "DM1- Non Transport Protocol
";
CM_ SG_ 2566835199 BATT_dm2ConvMethod_9 "Conversion Method
";
CM_ SG_ 2566835199 BATT_dm2SpnFmi_9 "FMI";
CM_ SG_ 2566835199 BATT_dm2SpnLsb_9 "SPN-LSB";
CM_ SG_ 2566835199 BATT_dm2SpnIsb_9 "SPN-ISB";
CM_ SG_ 2566835199 BATT_dm2SpnMsb_9 "SPN-MSB
";
CM_ SG_ 2566835199 BATT_dm2FlashLampStatus_9 "Flash Lamp Status";
CM_ SG_ 2566835199 BATT_dm2LampStatus_9 "Lamp Status";
CM_ BO_ 2566849014 "Battery limits";
CM_ SG_ 2566849014 BATT_vModDchLimit_0 "Voltage discharge limit sent to inverter";
CM_ SG_ 2566849014 BATT_iModDchLimit30s_0 "Current discharge limit in A";
CM_ SG_ 2566849014 BATT_iModDchLimit10s_0 "Current discharge limit in A";
CM_ SG_ 2566849014 BATT_iModDchLimitCont_0 "Current discharge limit in A";
CM_ BO_ 2566849015 "Battery limits";
CM_ SG_ 2566849015 BATT_vModDchLimit_1 "Voltage discharge limit sent to inverter";
CM_ SG_ 2566849015 BATT_iModDchLimit30s_1 "Current discharge limit in A";
CM_ SG_ 2566849015 BATT_iModDchLimit10s_1 "Current discharge limit in A";
CM_ SG_ 2566849015 BATT_iModDchLimitCont_1 "Current discharge limit in A";
CM_ BO_ 2566849016 "Battery limits";
CM_ SG_ 2566849016 BATT_vModDchLimit_2 "Voltage discharge limit sent to inverter";
CM_ SG_ 2566849016 BATT_iModDchLimit30s_2 "Current discharge limit in A";
CM_ SG_ 2566849016 BATT_iModDchLimit10s_2 "Current discharge limit in A";
CM_ SG_ 2566849016 BATT_iModDchLimitCont_2 "Current discharge limit in A";
CM_ BO_ 2566849017 "Battery limits";
CM_ SG_ 2566849017 BATT_vModDchLimit_3 "Voltage discharge limit sent to inverter";
CM_ SG_ 2566849017 BATT_iModDchLimit30s_3 "Current discharge limit in A";
CM_ SG_ 2566849017 BATT_iModDchLimit10s_3 "Current discharge limit in A";
CM_ SG_ 2566849017 BATT_iModDchLimitCont_3 "Current discharge limit in A";
CM_ BO_ 2566849018 "Battery limits";
CM_ SG_ 2566849018 BATT_vModDchLimit_4 "Voltage discharge limit sent to inverter";
CM_ SG_ 2566849018 BATT_iModDchLimit30s_4 "Current discharge limit in A";
CM_ SG_ 2566849018 BATT_iModDchLimit10s_4 "Current discharge limit in A";
CM_ SG_ 2566849018 BATT_iModDchLimitCont_4 "Current discharge limit in A";
CM_ BO_ 2566849019 "Battery limits";
CM_ SG_ 2566849019 BATT_vModDchLimit_5 "Voltage discharge limit sent to inverter";
CM_ SG_ 2566849019 BATT_iModDchLimit30s_5 "Current discharge limit in A";
CM_ SG_ 2566849019 BATT_iModDchLimit10s_5 "Current discharge limit in A";
CM_ SG_ 2566849019 BATT_iModDchLimitCont_5 "Current discharge limit in A";
CM_ BO_ 2566849020 "Battery limits";
CM_ SG_ 2566849020 BATT_vModDchLimit_6 "Voltage discharge limit sent to inverter";
CM_ SG_ 2566849020 BATT_iModDchLimit30s_6 "Current discharge limit in A";
CM_ SG_ 2566849020 BATT_iModDchLimit10s_6 "Current discharge limit in A";
CM_ SG_ 2566849020 BATT_iModDchLimitCont_6 "Current discharge limit in A";
CM_ BO_ 2566849021 "Battery limits";
CM_ SG_ 2566849021 BATT_vModDchLimit_7 "Voltage discharge limit sent to inverter";
CM_ SG_ 2566849021 BATT_iModDchLimit30s_7 "Current discharge limit in A";
CM_ SG_ 2566849021 BATT_iModDchLimit10s_7 "Current discharge limit in A";
CM_ SG_ 2566849021 BATT_iModDchLimitCont_7 "Current discharge limit in A";
CM_ BO_ 2566849022 "Battery limits";
CM_ SG_ 2566849022 BATT_vModDchLimit_8 "Voltage discharge limit sent to inverter";
CM_ SG_ 2566849022 BATT_iModDchLimit30s_8 "Current discharge limit in A";
CM_ SG_ 2566849022 BATT_iModDchLimit10s_8 "Current discharge limit in A";
CM_ SG_ 2566849022 BATT_iModDchLimitCont_8 "Current discharge limit in A";
CM_ BO_ 2566849023 "Battery limits";
CM_ SG_ 2566849023 BATT_vModDchLimit_9 "Voltage discharge limit sent to inverter";
CM_ SG_ 2566849023 BATT_iModDchLimit30s_9 "Current discharge limit in A";
CM_ SG_ 2566849023 BATT_iModDchLimit10s_9 "Current discharge limit in A";
CM_ SG_ 2566849023 BATT_iModDchLimitCont_9 "Current discharge limit in A";
CM_ SG_ 2566851062 BATT_tModule2 "Battery temperature as measured by thermistor two";
CM_ SG_ 2566851062 BATT_tModule1 "Battery temperature as measured by thermistor one";
CM_ SG_ 2566851062 BATT_tBoard "Ambient/Board temperature measured";
CM_ BO_ 2566851318 "Battery status";
CM_ SG_ 2566851318 BATT_modUVP_0 "Inhibit Full Power";
CM_ SG_ 2566851318 BATT_modWeldStat_0 "Inhibit Full Power";
CM_ SG_ 2566851318 BATT_modNumModsDataValid_0 "Number of parallel modules with valid data";
CM_ SG_ 2566851318 BATT_modNumModsOnNetwork_0 "Number of modules on the network";
CM_ SG_ 2566851318 BATT_modNumModsOnHvBus_0 "Number of modules on the HV bus";
CM_ SG_ 2566851318 BATT_modNumModsConfigured_0 "Number of parallel modules configured for the Module";
CM_ SG_ 2566851318 BATT_ArbitrationComplete_0 "1 - Node ID Arbitration Completed (default)
0 - Node ID Arbitration Active";
CM_ SG_ 2566851318 BATT_modStateRequested_0 "Reports the requested battery state ";
CM_ SG_ 2566851318 BATT_modDataValid_0 "Module data valid";
CM_ SG_ 2566851318 BATT_prechargeState_0 "Precharge state";
CM_ SG_ 2566851318 BATT_fetPchgCommand_0 "PCHG FET commanded state";
CM_ SG_ 2566851318 BATT_fetDsgCommand_0 "DSG FETs commanded state";
CM_ SG_ 2566851318 BATT_fetChgCommand_0 "CHG FETs commanded state";
CM_ SG_ 2566851318 BATT_fetDsgStatus_0 "DSG FETs status";
CM_ SG_ 2566851318 BATT_fetChgStatus_0 "CHG FETs status";
CM_ SG_ 2566851318 BATT_timeRampdown_0 "Ramp down time";
CM_ SG_ 2566851318 BATT_inhRegen_0 "Inhibit Regen";
CM_ SG_ 2566851318 BATT_inhFullPower_0 "Inhibit Full Power";
CM_ SG_ 2566851318 BATT_inhDriveEntry_0 "Inhibit Drive Entry";
CM_ SG_ 2566851318 BATT_inhDrive_0 "Inhibit Drive";
CM_ SG_ 2566851318 BATT_inhContPower_0 "Inhibit Continuous Power";
CM_ SG_ 2566851318 BATT_inhChargeEntry_0 "Inhibit Charge Entry";
CM_ SG_ 2566851318 BATT_inhCharge_0 "Inhibit Charge";
CM_ SG_ 2566851318 BATT_modPackState_0 "Module reported pack state";
CM_ SG_ 2566851318 BATT_modChildState_0 "Reports the current state of the battery";
CM_ SG_ 2566851318 BATT_modParentState_0 "Reports the current state of the battery";
CM_ BO_ 2566851319 "Battery status";
CM_ SG_ 2566851319 BATT_modUVP_1 "Inhibit Full Power";
CM_ SG_ 2566851319 BATT_modWeldStat_1 "Inhibit Full Power";
CM_ SG_ 2566851319 BATT_modNumModsDataValid_1 "Number of parallel modules with valid data";
CM_ SG_ 2566851319 BATT_modNumModsOnNetwork_1 "Number of modules on the network";
CM_ SG_ 2566851319 BATT_modNumModsOnHvBus_1 "Number of modules on the HV bus";
CM_ SG_ 2566851319 BATT_modNumModsConfigured_1 "Number of parallel modules configured for the Module";
CM_ SG_ 2566851319 BATT_ArbitrationComplete_1 "1 - Node ID Arbitration Completed (default)
0 - Node ID Arbitration Active";
CM_ SG_ 2566851319 BATT_modStateRequested_1 "Reports the requested battery state ";
CM_ SG_ 2566851319 BATT_modDataValid_1 "Module data valid";
CM_ SG_ 2566851319 BATT_prechargeState_1 "Precharge state";
CM_ SG_ 2566851319 BATT_fetPchgCommand_1 "PCHG FET commanded state";
CM_ SG_ 2566851319 BATT_fetDsgCommand_1 "DSG FETs commanded state";
CM_ SG_ 2566851319 BATT_fetChgCommand_1 "CHG FETs commanded state";
CM_ SG_ 2566851319 BATT_fetDsgStatus_1 "DSG FETs status";
CM_ SG_ 2566851319 BATT_fetChgStatus_1 "CHG FETs status";
CM_ SG_ 2566851319 BATT_timeRampdown_1 "Ramp down time";
CM_ SG_ 2566851319 BATT_inhRegen_1 "Inhibit Regen";
CM_ SG_ 2566851319 BATT_inhFullPower_1 "Inhibit Full Power";
CM_ SG_ 2566851319 BATT_inhDriveEntry_1 "Inhibit Drive Entry";
CM_ SG_ 2566851319 BATT_inhDrive_1 "Inhibit Drive";
CM_ SG_ 2566851319 BATT_inhContPower_1 "Inhibit Continuous Power";
CM_ SG_ 2566851319 BATT_inhChargeEntry_1 "Inhibit Charge Entry";
CM_ SG_ 2566851319 BATT_inhCharge_1 "Inhibit Charge";
CM_ SG_ 2566851319 BATT_modPackState_1 "Module reported pack state";
CM_ SG_ 2566851319 BATT_modChildState_1 "Reports the current state of the battery";
CM_ SG_ 2566851319 BATT_modParentState_1 "Reports the current state of the battery";
CM_ BO_ 2566851320 "Battery status";
CM_ SG_ 2566851320 BATT_modUVP_2 "Inhibit Full Power";
CM_ SG_ 2566851320 BATT_modWeldStat_2 "Inhibit Full Power";
CM_ SG_ 2566851320 BATT_modNumModsDataValid_2 "Number of parallel modules with valid data";
CM_ SG_ 2566851320 BATT_modNumModsOnNetwork_2 "Number of modules on the network";
CM_ SG_ 2566851320 BATT_modNumModsOnHvBus_2 "Number of modules on the HV bus";
CM_ SG_ 2566851320 BATT_modNumModsConfigured_2 "Number of parallel modules configured for the Module";
CM_ SG_ 2566851320 BATT_ArbitrationComplete_2 "1 - Node ID Arbitration Completed (default)
0 - Node ID Arbitration Active";
CM_ SG_ 2566851320 BATT_modStateRequested_2 "Reports the requested battery state ";
CM_ SG_ 2566851320 BATT_modDataValid_2 "Module data valid";
CM_ SG_ 2566851320 BATT_prechargeState_2 "Precharge state";
CM_ SG_ 2566851320 BATT_fetPchgCommand_2 "PCHG FET commanded state";
CM_ SG_ 2566851320 BATT_fetDsgCommand_2 "DSG FETs commanded state";
CM_ SG_ 2566851320 BATT_fetChgCommand_2 "CHG FETs commanded state";
CM_ SG_ 2566851320 BATT_fetDsgStatus_2 "DSG FETs status";
CM_ SG_ 2566851320 BATT_fetChgStatus_2 "CHG FETs status";
CM_ SG_ 2566851320 BATT_timeRampdown_2 "Ramp down time";
CM_ SG_ 2566851320 BATT_inhRegen_2 "Inhibit Regen";
CM_ SG_ 2566851320 BATT_inhFullPower_2 "Inhibit Full Power";
CM_ SG_ 2566851320 BATT_inhDriveEntry_2 "Inhibit Drive Entry";
CM_ SG_ 2566851320 BATT_inhDrive_2 "Inhibit Drive";
CM_ SG_ 2566851320 BATT_inhContPower_2 "Inhibit Continuous Power";
CM_ SG_ 2566851320 BATT_inhChargeEntry_2 "Inhibit Charge Entry";
CM_ SG_ 2566851320 BATT_inhCharge_2 "Inhibit Charge";
CM_ SG_ 2566851320 BATT_modPackState_2 "Module reported pack state";
CM_ SG_ 2566851320 BATT_modChildState_2 "Reports the current state of the battery";
CM_ SG_ 2566851320 BATT_modParentState_2 "Reports the current state of the battery";
CM_ BO_ 2566851321 "Battery status";
CM_ SG_ 2566851321 BATT_modUVP_3 "Inhibit Full Power";
CM_ SG_ 2566851321 BATT_modWeldStat_3 "Inhibit Full Power";
CM_ SG_ 2566851321 BATT_modNumModsDataValid_3 "Number of parallel modules with valid data";
CM_ SG_ 2566851321 BATT_modNumModsOnNetwork_3 "Number of modules on the network";
CM_ SG_ 2566851321 BATT_modNumModsOnHvBus_3 "Number of modules on the HV bus";
CM_ SG_ 2566851321 BATT_modNumModsConfigured_3 "Number of parallel modules configured for the Module";
CM_ SG_ 2566851321 BATT_ArbitrationComplete_3 "1 - Node ID Arbitration Completed (default)
0 - Node ID Arbitration Active";
CM_ SG_ 2566851321 BATT_modStateRequested_3 "Reports the requested battery state ";
CM_ SG_ 2566851321 BATT_modDataValid_3 "Module data valid";
CM_ SG_ 2566851321 BATT_prechargeState_3 "Precharge state";
CM_ SG_ 2566851321 BATT_fetPchgCommand_3 "PCHG FET commanded state";
CM_ SG_ 2566851321 BATT_fetDsgCommand_3 "DSG FETs commanded state";
CM_ SG_ 2566851321 BATT_fetChgCommand_3 "CHG FETs commanded state";
CM_ SG_ 2566851321 BATT_fetDsgStatus_3 "DSG FETs status";
CM_ SG_ 2566851321 BATT_fetChgStatus_3 "CHG FETs status";
CM_ SG_ 2566851321 BATT_timeRampdown_3 "Ramp down time";
CM_ SG_ 2566851321 BATT_inhRegen_3 "Inhibit Regen";
CM_ SG_ 2566851321 BATT_inhFullPower_3 "Inhibit Full Power";
CM_ SG_ 2566851321 BATT_inhDriveEntry_3 "Inhibit Drive Entry";
CM_ SG_ 2566851321 BATT_inhDrive_3 "Inhibit Drive";
CM_ SG_ 2566851321 BATT_inhContPower_3 "Inhibit Continuous Power";
CM_ SG_ 2566851321 BATT_inhChargeEntry_3 "Inhibit Charge Entry";
CM_ SG_ 2566851321 BATT_inhCharge_3 "Inhibit Charge";
CM_ SG_ 2566851321 BATT_modPackState_3 "Module reported pack state";
CM_ SG_ 2566851321 BATT_modChildState_3 "Reports the current state of the battery";
CM_ SG_ 2566851321 BATT_modParentState_3 "Reports the current state of the battery";
CM_ BO_ 2566851322 "Battery status";
CM_ SG_ 2566851322 BATT_modUVP_4 "Inhibit Full Power";
CM_ SG_ 2566851322 BATT_modWeldStat_4 "Inhibit Full Power";
CM_ SG_ 2566851322 BATT_modNumModsDataValid_4 "Number of parallel modules with valid data";
CM_ SG_ 2566851322 BATT_modNumModsOnNetwork_4 "Number of modules on the network";
CM_ SG_ 2566851322 BATT_modNumModsOnHvBus_4 "Number of modules on the HV bus";
CM_ SG_ 2566851322 BATT_modNumModsConfigured_4 "Number of parallel modules configured for the Module";
CM_ SG_ 2566851322 BATT_ArbitrationComplete_4 "1 - Node ID Arbitration Completed (default)
0 - Node ID Arbitration Active";
CM_ SG_ 2566851322 BATT_modStateRequested_4 "Reports the requested battery state ";
CM_ SG_ 2566851322 BATT_modDataValid_4 "Module data valid";
CM_ SG_ 2566851322 BATT_prechargeState_4 "Precharge state";
CM_ SG_ 2566851322 BATT_fetPchgCommand_4 "PCHG FET commanded state";
CM_ SG_ 2566851322 BATT_fetDsgCommand_4 "DSG FETs commanded state";
CM_ SG_ 2566851322 BATT_fetChgCommand_4 "CHG FETs commanded state";
CM_ SG_ 2566851322 BATT_fetDsgStatus_4 "DSG FETs status";
CM_ SG_ 2566851322 BATT_fetChgStatus_4 "CHG FETs status";
CM_ SG_ 2566851322 BATT_timeRampdown_4 "Ramp down time";
CM_ SG_ 2566851322 BATT_inhRegen_4 "Inhibit Regen";
CM_ SG_ 2566851322 BATT_inhFullPower_4 "Inhibit Full Power";
CM_ SG_ 2566851322 BATT_inhDriveEntry_4 "Inhibit Drive Entry";
CM_ SG_ 2566851322 BATT_inhDrive_4 "Inhibit Drive";
CM_ SG_ 2566851322 BATT_inhContPower_4 "Inhibit Continuous Power";
CM_ SG_ 2566851322 BATT_inhChargeEntry_4 "Inhibit Charge Entry";
CM_ SG_ 2566851322 BATT_inhCharge_4 "Inhibit Charge";
CM_ SG_ 2566851322 BATT_modPackState_4 "Module reported pack state";
CM_ SG_ 2566851322 BATT_modChildState_4 "Reports the current state of the battery";
CM_ SG_ 2566851322 BATT_modParentState_4 "Reports the current state of the battery";
CM_ BO_ 2566851323 "Battery status";
CM_ SG_ 2566851323 BATT_modUVP_5 "Inhibit Full Power";
CM_ SG_ 2566851323 BATT_modWeldStat_5 "Inhibit Full Power";
CM_ SG_ 2566851323 BATT_modNumModsDataValid_5 "Number of parallel modules with valid data";
CM_ SG_ 2566851323 BATT_modNumModsOnNetwork_5 "Number of modules on the network";
CM_ SG_ 2566851323 BATT_modNumModsOnHvBus_5 "Number of modules on the HV bus";
CM_ SG_ 2566851323 BATT_modNumModsConfigured_5 "Number of parallel modules configured for the Module";
CM_ SG_ 2566851323 BATT_ArbitrationComplete_5 "1 - Node ID Arbitration Completed (default)
0 - Node ID Arbitration Active";
CM_ SG_ 2566851323 BATT_modStateRequested_5 "Reports the requested battery state ";
CM_ SG_ 2566851323 BATT_modDataValid_5 "Module data valid";
CM_ SG_ 2566851323 BATT_prechargeState_5 "Precharge state";
CM_ SG_ 2566851323 BATT_fetPchgCommand_5 "PCHG FET commanded state";
CM_ SG_ 2566851323 BATT_fetDsgCommand_5 "DSG FETs commanded state";
CM_ SG_ 2566851323 BATT_fetChgCommand_5 "CHG FETs commanded state";
CM_ SG_ 2566851323 BATT_fetDsgStatus_5 "DSG FETs status";
CM_ SG_ 2566851323 BATT_fetChgStatus_5 "CHG FETs status";
CM_ SG_ 2566851323 BATT_timeRampdown_5 "Ramp down time";
CM_ SG_ 2566851323 BATT_inhRegen_5 "Inhibit Regen";
CM_ SG_ 2566851323 BATT_inhFullPower_5 "Inhibit Full Power";
CM_ SG_ 2566851323 BATT_inhDriveEntry_5 "Inhibit Drive Entry";
CM_ SG_ 2566851323 BATT_inhDrive_5 "Inhibit Drive";
CM_ SG_ 2566851323 BATT_inhContPower_5 "Inhibit Continuous Power";
CM_ SG_ 2566851323 BATT_inhChargeEntry_5 "Inhibit Charge Entry";
CM_ SG_ 2566851323 BATT_inhCharge_5 "Inhibit Charge";
CM_ SG_ 2566851323 BATT_modPackState_5 "Module reported pack state";
CM_ SG_ 2566851323 BATT_modChildState_5 "Reports the current state of the battery";
CM_ SG_ 2566851323 BATT_modParentState_5 "Reports the current state of the battery";
CM_ BO_ 2566851324 "Battery status";
CM_ SG_ 2566851324 BATT_modUVP_6 "Inhibit Full Power";
CM_ SG_ 2566851324 BATT_modWeldStat_6 "Inhibit Full Power";
CM_ SG_ 2566851324 BATT_modNumModsDataValid_6 "Number of parallel modules with valid data";
CM_ SG_ 2566851324 BATT_modNumModsOnNetwork_6 "Number of modules on the network";
CM_ SG_ 2566851324 BATT_modNumModsOnHvBus_6 "Number of modules on the HV bus";
CM_ SG_ 2566851324 BATT_modNumModsConfigured_6 "Number of parallel modules configured for the Module";
CM_ SG_ 2566851324 BATT_ArbitrationComplete_6 "1 - Node ID Arbitration Completed (default)
0 - Node ID Arbitration Active";
CM_ SG_ 2566851324 BATT_modStateRequested_6 "Reports the requested battery state ";
CM_ SG_ 2566851324 BATT_modDataValid_6 "Module data valid";
CM_ SG_ 2566851324 BATT_prechargeState_6 "Precharge state";
CM_ SG_ 2566851324 BATT_fetPchgCommand_6 "PCHG FET commanded state";
CM_ SG_ 2566851324 BATT_fetDsgCommand_6 "DSG FETs commanded state";
CM_ SG_ 2566851324 BATT_fetChgCommand_6 "CHG FETs commanded state";
CM_ SG_ 2566851324 BATT_fetDsgStatus_6 "DSG FETs status";
CM_ SG_ 2566851324 BATT_fetChgStatus_6 "CHG FETs status";
CM_ SG_ 2566851324 BATT_timeRampdown_6 "Ramp down time";
CM_ SG_ 2566851324 BATT_inhRegen_6 "Inhibit Regen";
CM_ SG_ 2566851324 BATT_inhFullPower_6 "Inhibit Full Power";
CM_ SG_ 2566851324 BATT_inhDriveEntry_6 "Inhibit Drive Entry";
CM_ SG_ 2566851324 BATT_inhDrive_6 "Inhibit Drive";
CM_ SG_ 2566851324 BATT_inhContPower_6 "Inhibit Continuous Power";
CM_ SG_ 2566851324 BATT_inhChargeEntry_6 "Inhibit Charge Entry";
CM_ SG_ 2566851324 BATT_inhCharge_6 "Inhibit Charge";
CM_ SG_ 2566851324 BATT_modPackState_6 "Module reported pack state";
CM_ SG_ 2566851324 BATT_modChildState_6 "Reports the current state of the battery";
CM_ SG_ 2566851324 BATT_modParentState_6 "Reports the current state of the battery";
CM_ BO_ 2566851325 "Battery status";
CM_ SG_ 2566851325 BATT_modUVP_7 "Inhibit Full Power";
CM_ SG_ 2566851325 BATT_modWeldStat_7 "Inhibit Full Power";
CM_ SG_ 2566851325 BATT_modNumModsDataValid_7 "Number of parallel modules with valid data";
CM_ SG_ 2566851325 BATT_modNumModsOnNetwork_7 "Number of modules on the network";
CM_ SG_ 2566851325 BATT_modNumModsOnHvBus_7 "Number of modules on the HV bus";
CM_ SG_ 2566851325 BATT_modNumModsConfigured_7 "Number of parallel modules configured for the Module";
CM_ SG_ 2566851325 BATT_ArbitrationComplete_7 "1 - Node ID Arbitration Completed (default)
0 - Node ID Arbitration Active";
CM_ SG_ 2566851325 BATT_modStateRequested_7 "Reports the requested battery state ";
CM_ SG_ 2566851325 BATT_modDataValid_7 "Module data valid";
CM_ SG_ 2566851325 BATT_prechargeState_7 "Precharge state";
CM_ SG_ 2566851325 BATT_fetPchgCommand_7 "PCHG FET commanded state";
CM_ SG_ 2566851325 BATT_fetDsgCommand_7 "DSG FETs commanded state";
CM_ SG_ 2566851325 BATT_fetChgCommand_7 "CHG FETs commanded state";
CM_ SG_ 2566851325 BATT_fetDsgStatus_7 "DSG FETs status";
CM_ SG_ 2566851325 BATT_fetChgStatus_7 "CHG FETs status";
CM_ SG_ 2566851325 BATT_timeRampdown_7 "Ramp down time";
CM_ SG_ 2566851325 BATT_inhRegen_7 "Inhibit Regen";
CM_ SG_ 2566851325 BATT_inhFullPower_7 "Inhibit Full Power";
CM_ SG_ 2566851325 BATT_inhDriveEntry_7 "Inhibit Drive Entry";
CM_ SG_ 2566851325 BATT_inhDrive_7 "Inhibit Drive";
CM_ SG_ 2566851325 BATT_inhContPower_7 "Inhibit Continuous Power";
CM_ SG_ 2566851325 BATT_inhChargeEntry_7 "Inhibit Charge Entry";
CM_ SG_ 2566851325 BATT_inhCharge_7 "Inhibit Charge";
CM_ SG_ 2566851325 BATT_modPackState_7 "Module reported pack state";
CM_ SG_ 2566851325 BATT_modChildState_7 "Reports the current state of the battery";
CM_ SG_ 2566851325 BATT_modParentState_7 "Reports the current state of the battery";
CM_ BO_ 2566851326 "Battery status";
CM_ SG_ 2566851326 BATT_modUVP_8 "Inhibit Full Power";
CM_ SG_ 2566851326 BATT_modWeldStat_8 "Inhibit Full Power";
CM_ SG_ 2566851326 BATT_modNumModsDataValid_8 "Number of parallel modules with valid data";
CM_ SG_ 2566851326 BATT_modNumModsOnNetwork_8 "Number of modules on the network";
CM_ SG_ 2566851326 BATT_modNumModsOnHvBus_8 "Number of modules on the HV bus";
CM_ SG_ 2566851326 BATT_modNumModsConfigured_8 "Number of parallel modules configured for the Module";
CM_ SG_ 2566851326 BATT_ArbitrationComplete_8 "1 - Node ID Arbitration Completed (default)
0 - Node ID Arbitration Active";
CM_ SG_ 2566851326 BATT_modStateRequested_8 "Reports the requested battery state ";
CM_ SG_ 2566851326 BATT_modDataValid_8 "Module data valid";
CM_ SG_ 2566851326 BATT_prechargeState_8 "Precharge state";
CM_ SG_ 2566851326 BATT_fetPchgCommand_8 "PCHG FET commanded state";
CM_ SG_ 2566851326 BATT_fetDsgCommand_8 "DSG FETs commanded state";
CM_ SG_ 2566851326 BATT_fetChgCommand_8 "CHG FETs commanded state";
CM_ SG_ 2566851326 BATT_fetDsgStatus_8 "DSG FETs status";
CM_ SG_ 2566851326 BATT_fetChgStatus_8 "CHG FETs status";
CM_ SG_ 2566851326 BATT_timeRampdown_8 "Ramp down time";
CM_ SG_ 2566851326 BATT_inhRegen_8 "Inhibit Regen";
CM_ SG_ 2566851326 BATT_inhFullPower_8 "Inhibit Full Power";
CM_ SG_ 2566851326 BATT_inhDriveEntry_8 "Inhibit Drive Entry";
CM_ SG_ 2566851326 BATT_inhDrive_8 "Inhibit Drive";
CM_ SG_ 2566851326 BATT_inhContPower_8 "Inhibit Continuous Power";
CM_ SG_ 2566851326 BATT_inhChargeEntry_8 "Inhibit Charge Entry";
CM_ SG_ 2566851326 BATT_inhCharge_8 "Inhibit Charge";
CM_ SG_ 2566851326 BATT_modPackState_8 "Module reported pack state";
CM_ SG_ 2566851326 BATT_modChildState_8 "Reports the current state of the battery";
CM_ SG_ 2566851326 BATT_modParentState_8 "Reports the current state of the battery";
CM_ BO_ 2566851327 "Battery status";
CM_ SG_ 2566851327 BATT_modUVP_9 "Inhibit Full Power";
CM_ SG_ 2566851327 BATT_modWeldStat_9 "Inhibit Full Power";
CM_ SG_ 2566851327 BATT_modNumModsDataValid_9 "Number of parallel modules with valid data";
CM_ SG_ 2566851327 BATT_modNumModsOnNetwork_9 "Number of modules on the network";
CM_ SG_ 2566851327 BATT_modNumModsOnHvBus_9 "Number of modules on the HV bus";
CM_ SG_ 2566851327 BATT_modNumModsConfigured_9 "Number of parallel modules configured for the Module";
CM_ SG_ 2566851327 BATT_ArbitrationComplete_9 "1 - Node ID Arbitration Completed (default)
0 - Node ID Arbitration Active";
CM_ SG_ 2566851327 BATT_modStateRequested_9 "Reports the requested battery state ";
CM_ SG_ 2566851327 BATT_modDataValid_9 "Module data valid";
CM_ SG_ 2566851327 BATT_prechargeState_9 "Precharge state";
CM_ SG_ 2566851327 BATT_fetPchgCommand_9 "PCHG FET commanded state";
CM_ SG_ 2566851327 BATT_fetDsgCommand_9 "DSG FETs commanded state";
CM_ SG_ 2566851327 BATT_fetChgCommand_9 "CHG FETs commanded state";
CM_ SG_ 2566851327 BATT_fetDsgStatus_9 "DSG FETs status";
CM_ SG_ 2566851327 BATT_fetChgStatus_9 "CHG FETs status";
CM_ SG_ 2566851327 BATT_timeRampdown_9 "Ramp down time";
CM_ SG_ 2566851327 BATT_inhRegen_9 "Inhibit Regen";
CM_ SG_ 2566851327 BATT_inhFullPower_9 "Inhibit Full Power";
CM_ SG_ 2566851327 BATT_inhDriveEntry_9 "Inhibit Drive Entry";
CM_ SG_ 2566851327 BATT_inhDrive_9 "Inhibit Drive";
CM_ SG_ 2566851327 BATT_inhContPower_9 "Inhibit Continuous Power";
CM_ SG_ 2566851327 BATT_inhChargeEntry_9 "Inhibit Charge Entry";
CM_ SG_ 2566851327 BATT_inhCharge_9 "Inhibit Charge";
CM_ SG_ 2566851327 BATT_modPackState_9 "Module reported pack state";
CM_ SG_ 2566851327 BATT_modChildState_9 "Reports the current state of the battery";
CM_ SG_ 2566851327 BATT_modParentState_9 "Reports the current state of the battery";
CM_ SG_ 2566851830 BATT_vMod_0 "Battery terminal voltage";
CM_ SG_ 2566851830 BATT_vModSumOfCells_0 "Battery pack voltage in volts, sum of brick voltages";
CM_ SG_ 2566851830 BATT_iMod_0 "Charge/discharge rate in ampere - positive for charge, negative for discharge.";
CM_ SG_ 2566851830 BATT_iModFiltered_0 "Filtered charge/discharge rate in ampere - positive for charge, negative for discharge.";
CM_ SG_ 2566851831 BATT_vMod_1 "Battery terminal voltage";
CM_ SG_ 2566851831 BATT_vModSumOfCells_1 "Battery pack voltage in volts, sum of brick voltages";
CM_ SG_ 2566851831 BATT_iMod_1 "Charge/discharge rate in ampere - positive for charge, negative for discharge.";
CM_ SG_ 2566851831 BATT_iModFiltered_1 "Filtered charge/discharge rate in ampere - positive for charge, negative for discharge.";
CM_ SG_ 2566851832 BATT_vMod_2 "Battery terminal voltage";
CM_ SG_ 2566851832 BATT_vModSumOfCells_2 "Battery pack voltage in volts, sum of brick voltages";
CM_ SG_ 2566851832 BATT_iMod_2 "Charge/discharge rate in ampere - positive for charge, negative for discharge.";
CM_ SG_ 2566851832 BATT_iModFiltered_2 "Filtered charge/discharge rate in ampere - positive for charge, negative for discharge.";
CM_ SG_ 2566851833 BATT_vMod_3 "Battery terminal voltage";
CM_ SG_ 2566851833 BATT_vModSumOfCells_3 "Battery pack voltage in volts, sum of brick voltages";
CM_ SG_ 2566851833 BATT_iMod_3 "Charge/discharge rate in ampere - positive for charge, negative for discharge.";
CM_ SG_ 2566851833 BATT_iModFiltered_3 "Filtered charge/discharge rate in ampere - positive for charge, negative for discharge.";
CM_ SG_ 2566851834 BATT_vMod_4 "Battery terminal voltage";
CM_ SG_ 2566851834 BATT_vModSumOfCells_4 "Battery pack voltage in volts, sum of brick voltages";
CM_ SG_ 2566851834 BATT_iMod_4 "Charge/discharge rate in ampere - positive for charge, negative for discharge.";
CM_ SG_ 2566851834 BATT_iModFiltered_4 "Filtered charge/discharge rate in ampere - positive for charge, negative for discharge.";
CM_ SG_ 2566851835 BATT_vMod_5 "Battery terminal voltage";
CM_ SG_ 2566851835 BATT_vModSumOfCells_5 "Battery pack voltage in volts, sum of brick voltages";
CM_ SG_ 2566851835 BATT_iMod_5 "Charge/discharge rate in ampere - positive for charge, negative for discharge.";
CM_ SG_ 2566851835 BATT_iModFiltered_5 "Filtered charge/discharge rate in ampere - positive for charge, negative for discharge.";
CM_ SG_ 2566851836 BATT_vMod_6 "Battery terminal voltage";
CM_ SG_ 2566851836 BATT_vModSumOfCells_6 "Battery pack voltage in volts, sum of brick voltages";
CM_ SG_ 2566851836 BATT_iMod_6 "Charge/discharge rate in ampere - positive for charge, negative for discharge.";
CM_ SG_ 2566851836 BATT_iModFiltered_6 "Filtered charge/discharge rate in ampere - positive for charge, negative for discharge.";
CM_ SG_ 2566851837 BATT_vMod_7 "Battery terminal voltage";
CM_ SG_ 2566851837 BATT_vModSumOfCells_7 "Battery pack voltage in volts, sum of brick voltages";
CM_ SG_ 2566851837 BATT_iMod_7 "Charge/discharge rate in ampere - positive for charge, negative for discharge.";
CM_ SG_ 2566851837 BATT_iModFiltered_7 "Filtered charge/discharge rate in ampere - positive for charge, negative for discharge.";
CM_ SG_ 2566851838 BATT_vMod_8 "Battery terminal voltage";
CM_ SG_ 2566851838 BATT_vModSumOfCells_8 "Battery pack voltage in volts, sum of brick voltages";
CM_ SG_ 2566851838 BATT_iMod_8 "Charge/discharge rate in ampere - positive for charge, negative for discharge.";
CM_ SG_ 2566851838 BATT_iModFiltered_8 "Filtered charge/discharge rate in ampere - positive for charge, negative for discharge.";

BA_DEF_  "NetworkSpeed" ENUM "250kBit/s","500kBit/s","1000kBit/s";
BA_DEF_ SG_  "SigType" ENUM "Default","Range","RangeSigned","ASCII","Discrete","Control","ReferencePGN","DTC","StringDelimiter","StringLength","StringLengthControl","MessageCounter","MessageChecksum";
BA_DEF_ SG_  "GenSigSendType" ENUM "Cyclic","OnWrite","OnWriteWithRepetition","OnChange","OnChangeWithRepetition","IfActive","IfActiveWithRepetition","NoSigSendType";
BA_DEF_ BO_  "GenMsgDiag" ENUM "No","Yes";
BA_DEF_ BU_  "GenNodeInstanceBitWidth" INT 0 0;
BA_DEF_ BO_  "GenMsgInstanced" STRING ;
BA_DEF_ SG_  "GenSigType" ENUM "Extended","Diagnostic","Standard","Modified";
BA_DEF_ BO_  "GenMsgCycleTime" INT 0 0;
BA_DEF_ SG_  "GenSigSNA" INT 0 65535;
BA_DEF_ SG_  "Access" ENUM "r","rw";
BA_DEF_  "BusType" STRING ;
BA_DEF_ BO_  "VFrameFormat" ENUM "StandardCAN","ExtendedCAN","reserved","J1939PG";
BA_DEF_DEF_  "NetworkSpeed" "500kBit/s";
BA_DEF_DEF_  "SigType" "Default";
BA_DEF_DEF_  "GenSigSendType" "Cyclic";
BA_DEF_DEF_  "GenMsgDiag" "No";
BA_DEF_DEF_  "GenNodeInstanceBitWidth" 0;
BA_DEF_DEF_  "GenMsgInstanced" "No";
BA_DEF_DEF_  "GenSigType" "Standard";
BA_DEF_DEF_  "GenMsgCycleTime" 0;
BA_DEF_DEF_  "GenSigSNA" 0;
BA_DEF_DEF_  "Access" "r";
BA_DEF_DEF_  "BusType" "CAN";
BA_DEF_DEF_  "VFrameFormat" "J1939PG";
BA_ "GenNodeInstanceBitWidth" BU_ Battery 8;
BA_ "GenMsgDiag" BO_ 2566851062 1;
BA_ "GenMsgInstanced" BO_ 2552103157 "False";
BA_ "GenMsgInstanced" BO_ 2565341429 "False";
BA_ "GenMsgInstanced" BO_ 2565472256 "False";
BA_ "GenMsgInstanced" BO_ 2565472502 "False";
BA_ "GenMsgInstanced" BO_ 2565472503 "False";
BA_ "GenMsgInstanced" BO_ 2565472504 "False";
BA_ "GenMsgInstanced" BO_ 2565472505 "False";
BA_ "GenMsgInstanced" BO_ 2565472506 "False";
BA_ "GenMsgInstanced" BO_ 2565472507 "False";
BA_ "GenMsgInstanced" BO_ 2565472508 "False";
BA_ "GenMsgInstanced" BO_ 2565472509 "False";
BA_ "GenMsgInstanced" BO_ 2565472510 "False";
BA_ "GenMsgInstanced" BO_ 2565472511 "False";
BA_ "GenMsgInstanced" BO_ 2565538038 "False";
BA_ "GenMsgInstanced" BO_ 2565538039 "False";
BA_ "GenMsgInstanced" BO_ 2565538040 "False";
BA_ "GenMsgInstanced" BO_ 2565538041 "False";
BA_ "GenMsgInstanced" BO_ 2565538042 "False";
BA_ "GenMsgInstanced" BO_ 2565538043 "False";
BA_ "GenMsgInstanced" BO_ 2565538044 "False";
BA_ "GenMsgInstanced" BO_ 2565538045 "False";
BA_ "GenMsgInstanced" BO_ 2565538046 "False";
BA_ "GenMsgInstanced" BO_ 2565538047 "False";
BA_ "GenMsgInstanced" BO_ 2565603574 "False";
BA_ "GenMsgInstanced" BO_ 2565603575 "False";
BA_ "GenMsgInstanced" BO_ 2565603576 "False";
BA_ "GenMsgInstanced" BO_ 2565603577 "False";
BA_ "GenMsgInstanced" BO_ 2565603578 "False";
BA_ "GenMsgInstanced" BO_ 2565603579 "False";
BA_ "GenMsgInstanced" BO_ 2565603580 "False";
BA_ "GenMsgInstanced" BO_ 2565603581 "False";
BA_ "GenMsgInstanced" BO_ 2565603582 "False";
BA_ "GenMsgInstanced" BO_ 2565603583 "False";
BA_ "GenMsgInstanced" BO_ 2566654453 "False";
BA_ "GenMsgInstanced" BO_ 2566654709 "False";
BA_ "GenMsgInstanced" BO_ 2566834934 "False";
BA_ "GenMsgInstanced" BO_ 2566834935 "False";
BA_ "GenMsgInstanced" BO_ 2566834936 "False";
BA_ "GenMsgInstanced" BO_ 2566834937 "False";
BA_ "GenMsgInstanced" BO_ 2566834938 "False";
BA_ "GenMsgInstanced" BO_ 2566834939 "False";
BA_ "GenMsgInstanced" BO_ 2566834940 "False";
BA_ "GenMsgInstanced" BO_ 2566834941 "False";
BA_ "GenMsgInstanced" BO_ 2566834942 "False";
BA_ "GenMsgInstanced" BO_ 2566834943 "False";
BA_ "GenMsgInstanced" BO_ 2566835190 "False";
BA_ "GenMsgInstanced" BO_ 2566835191 "False";
BA_ "GenMsgInstanced" BO_ 2566835192 "False";
BA_ "GenMsgInstanced" BO_ 2566835193 "False";
BA_ "GenMsgInstanced" BO_ 2566835194 "False";
BA_ "GenMsgInstanced" BO_ 2566835195 "False";
BA_ "GenMsgInstanced" BO_ 2566835196 "False";
BA_ "GenMsgInstanced" BO_ 2566835197 "False";
BA_ "GenMsgInstanced" BO_ 2566835198 "False";
BA_ "GenMsgInstanced" BO_ 2566835199 "False";
BA_ "GenMsgInstanced" BO_ 2566849014 "False";
BA_ "GenMsgInstanced" BO_ 2566849015 "False";
BA_ "GenMsgInstanced" BO_ 2566849016 "False";
BA_ "GenMsgInstanced" BO_ 2566849017 "False";
BA_ "GenMsgInstanced" BO_ 2566849018 "False";
BA_ "GenMsgInstanced" BO_ 2566849019 "False";
BA_ "GenMsgInstanced" BO_ 2566849020 "False";
BA_ "GenMsgInstanced" BO_ 2566849021 "False";
BA_ "GenMsgInstanced" BO_ 2566849022 "False";
BA_ "GenMsgInstanced" BO_ 2566849023 "False";
BA_ "GenMsgInstanced" BO_ 2566849526 "False";
BA_ "GenMsgInstanced" BO_ 2566849527 "False";
BA_ "GenMsgInstanced" BO_ 2566849528 "False";
BA_ "GenMsgInstanced" BO_ 2566849529 "False";
BA_ "GenMsgInstanced" BO_ 2566849530 "False";
BA_ "GenMsgInstanced" BO_ 2566849531 "False";
BA_ "GenMsgInstanced" BO_ 2566849532 "False";
BA_ "GenMsgInstanced" BO_ 2566849533 "False";
BA_ "GenMsgInstanced" BO_ 2566849534 "False";
BA_ "GenMsgInstanced" BO_ 2566849535 "False";
BA_ "GenMsgInstanced" BO_ 2566850038 "False";
BA_ "GenMsgInstanced" BO_ 2566850039 "False";
BA_ "GenMsgInstanced" BO_ 2566850040 "False";
BA_ "GenMsgInstanced" BO_ 2566850041 "False";
BA_ "GenMsgInstanced" BO_ 2566850042 "False";
BA_ "GenMsgInstanced" BO_ 2566850043 "False";
BA_ "GenMsgInstanced" BO_ 2566850044 "False";
BA_ "GenMsgInstanced" BO_ 2566850045 "False";
BA_ "GenMsgInstanced" BO_ 2566850046 "False";
BA_ "GenMsgInstanced" BO_ 2566850047 "False";
BA_ "GenMsgInstanced" BO_ 2566850806 "False";
BA_ "GenMsgInstanced" BO_ 2566850807 "False";
BA_ "GenMsgInstanced" BO_ 2566850808 "False";
BA_ "GenMsgInstanced" BO_ 2566850809 "False";
BA_ "GenMsgInstanced" BO_ 2566850810 "False";
BA_ "GenMsgInstanced" BO_ 2566850811 "False";
BA_ "GenMsgInstanced" BO_ 2566850812 "False";
BA_ "GenMsgInstanced" BO_ 2566850813 "False";
BA_ "GenMsgInstanced" BO_ 2566850814 "False";
BA_ "GenMsgInstanced" BO_ 2566850815 "False";
BA_ "GenMsgInstanced" BO_ 2566851062 "False";
BA_ "GenMsgInstanced" BO_ 2566851318 "False";
BA_ "GenMsgInstanced" BO_ 2566851319 "False";
BA_ "GenMsgInstanced" BO_ 2566851320 "False";
BA_ "GenMsgInstanced" BO_ 2566851321 "False";
BA_ "GenMsgInstanced" BO_ 2566851322 "False";
BA_ "GenMsgInstanced" BO_ 2566851323 "False";
BA_ "GenMsgInstanced" BO_ 2566851324 "False";
BA_ "GenMsgInstanced" BO_ 2566851325 "False";
BA_ "GenMsgInstanced" BO_ 2566851326 "False";
BA_ "GenMsgInstanced" BO_ 2566851327 "False";
BA_ "GenMsgInstanced" BO_ 2566851830 "False";
BA_ "GenMsgInstanced" BO_ 2566851831 "False";
BA_ "GenMsgInstanced" BO_ 2566851832 "False";
BA_ "GenMsgInstanced" BO_ 2566851833 "False";
BA_ "GenMsgInstanced" BO_ 2566851834 "False";
BA_ "GenMsgInstanced" BO_ 2566851835 "False";
BA_ "GenMsgInstanced" BO_ 2566851836 "False";
BA_ "GenMsgInstanced" BO_ 2566851837 "False";
BA_ "GenMsgInstanced" BO_ 2566851838 "False";
BA_ "GenMsgCycleTime" BO_ 2566849014 100;
BA_ "GenMsgCycleTime" BO_ 2566849015 100;
BA_ "GenMsgCycleTime" BO_ 2566849016 100;
BA_ "GenMsgCycleTime" BO_ 2566849017 100;
BA_ "GenMsgCycleTime" BO_ 2566849018 100;
BA_ "GenMsgCycleTime" BO_ 2566849019 100;
BA_ "GenMsgCycleTime" BO_ 2566849020 100;
BA_ "GenMsgCycleTime" BO_ 2566849021 100;
BA_ "GenMsgCycleTime" BO_ 2566849022 100;
BA_ "GenMsgCycleTime" BO_ 2566849023 100;
BA_ "GenMsgCycleTime" BO_ 2566851062 1000;
BA_ "GenMsgCycleTime" BO_ 2566851318 100;
BA_ "GenMsgCycleTime" BO_ 2566851319 100;
BA_ "GenMsgCycleTime" BO_ 2566851320 100;
BA_ "GenMsgCycleTime" BO_ 2566851321 100;
BA_ "GenMsgCycleTime" BO_ 2566851322 100;
BA_ "GenMsgCycleTime" BO_ 2566851323 100;
BA_ "GenMsgCycleTime" BO_ 2566851324 100;
BA_ "GenMsgCycleTime" BO_ 2566851325 100;
BA_ "GenMsgCycleTime" BO_ 2566851326 100;
BA_ "GenMsgCycleTime" BO_ 2566851327 100;
BA_ "GenMsgCycleTime" BO_ 2566851830 100;
BA_ "GenMsgCycleTime" BO_ 2566851831 100;
BA_ "GenMsgCycleTime" BO_ 2566851832 100;
BA_ "GenMsgCycleTime" BO_ 2566851833 100;
BA_ "GenMsgCycleTime" BO_ 2566851834 100;
BA_ "GenMsgCycleTime" BO_ 2566851835 100;
BA_ "GenMsgCycleTime" BO_ 2566851836 100;
BA_ "GenMsgCycleTime" BO_ 2566851837 100;
BA_ "GenMsgCycleTime" BO_ 2566851838 100;
BA_ "GenSigType" SG_ 2565341429 BATT_dm11Resv 1;
BA_ "GenSigType" SG_ 2565472256 HOST_requested_pgn 0;
BA_ "GenSigType" SG_ 2565472502 BATT_dm1ReqPgn_0 1;
BA_ "GenSigType" SG_ 2565472503 BATT_dm1ReqPgn_1 1;
BA_ "GenSigType" SG_ 2565472504 BATT_dm1ReqPgn_2 1;
BA_ "GenSigType" SG_ 2565472505 BATT_dm1ReqPgn_3 1;
BA_ "GenSigType" SG_ 2565472506 BATT_dm1ReqPgn_4 1;
BA_ "GenSigType" SG_ 2565472507 BATT_dm1ReqPgn_5 1;
BA_ "GenSigType" SG_ 2565472508 BATT_dm1ReqPgn_6 1;
BA_ "GenSigType" SG_ 2565472509 BATT_dm1ReqPgn_7 1;
BA_ "GenSigType" SG_ 2565472510 BATT_dm1ReqPgn_8 1;
BA_ "GenSigType" SG_ 2565472511 BATT_dm1ReqPgn_9 1;
BA_ "GenSigType" SG_ 2565538038 BATT_dmSeqNum_0 1;
BA_ "GenSigType" SG_ 2565538038 BATT_dmPayLoad_0 1;
BA_ "GenSigType" SG_ 2565538039 BATT_dmPayLoad_1 1;
BA_ "GenSigType" SG_ 2565538039 BATT_dmSeqNum_1 1;
BA_ "GenSigType" SG_ 2565538040 BATT_dmPayLoad_2 1;
BA_ "GenSigType" SG_ 2565538040 BATT_dmSeqNum_2 1;
BA_ "GenSigType" SG_ 2565538041 BATT_dmSeqNum_3 1;
BA_ "GenSigType" SG_ 2565538041 BATT_dmPayLoad_3 1;
BA_ "GenSigType" SG_ 2565538042 BATT_dmPayLoad_4 1;
BA_ "GenSigType" SG_ 2565538042 BATT_dmSeqNum_4 1;
BA_ "GenSigType" SG_ 2565538043 BATT_dmPayLoad_5 1;
BA_ "GenSigType" SG_ 2565538043 BATT_dmSeqNum_5 1;
BA_ "GenSigType" SG_ 2565538044 BATT_dmSeqNum_6 1;
BA_ "GenSigType" SG_ 2565538044 BATT_dmPayLoad_6 1;
BA_ "GenSigType" SG_ 2565538045 BATT_dmSeqNum_7 1;
BA_ "GenSigType" SG_ 2565538045 BATT_dmPayLoad_7 1;
BA_ "GenSigType" SG_ 2565538046 BATT_dmSeqNum_8 1;
BA_ "GenSigType" SG_ 2565538046 BATT_dmPayLoad_8 1;
BA_ "GenSigType" SG_ 2565538047 BATT_dmSeqNum_9 1;
BA_ "GenSigType" SG_ 2565538047 BATT_dmPayLoad_9 1;
BA_ "GenSigType" SG_ 2565603574 BATT_bamResv_0 1;
BA_ "GenSigType" SG_ 2565603574 BATT_bamPgn_0 1;
BA_ "GenSigType" SG_ 2565603574 BATT_bamNumOfPackets_0 1;
BA_ "GenSigType" SG_ 2565603574 BATT_bamDataLength_0 1;
BA_ "GenSigType" SG_ 2565603574 BATT_bamCtrlByte_0 1;
BA_ "GenSigType" SG_ 2565603575 BATT_bamResv_1 1;
BA_ "GenSigType" SG_ 2565603575 BATT_bamPgn_1 1;
BA_ "GenSigType" SG_ 2565603575 BATT_bamNumOfPackets_1 1;
BA_ "GenSigType" SG_ 2565603575 BATT_bamDataLength_1 1;
BA_ "GenSigType" SG_ 2565603575 BATT_bamCtrlByte_1 1;
BA_ "GenSigType" SG_ 2565603576 BATT_bamResv_2 1;
BA_ "GenSigType" SG_ 2565603576 BATT_bamPgn_2 1;
BA_ "GenSigType" SG_ 2565603576 BATT_bamNumOfPackets_2 1;
BA_ "GenSigType" SG_ 2565603576 BATT_bamDataLength_2 1;
BA_ "GenSigType" SG_ 2565603576 BATT_bamCtrlByte_2 1;
BA_ "GenSigType" SG_ 2565603577 BATT_bamResv_3 1;
BA_ "GenSigType" SG_ 2565603577 BATT_bamPgn_3 1;
BA_ "GenSigType" SG_ 2565603577 BATT_bamNumOfPackets_3 1;
BA_ "GenSigType" SG_ 2565603577 BATT_bamDataLength_3 1;
BA_ "GenSigType" SG_ 2565603577 BATT_bamCtrlByte_3 1;
BA_ "GenSigType" SG_ 2565603578 BATT_bamPgn_4 1;
BA_ "GenSigType" SG_ 2565603578 BATT_bamResv_4 1;
BA_ "GenSigType" SG_ 2565603578 BATT_bamNumOfPackets_4 1;
BA_ "GenSigType" SG_ 2565603578 BATT_bamDataLength_4 1;
BA_ "GenSigType" SG_ 2565603578 BATT_bamCtrlByte_4 1;
BA_ "GenSigType" SG_ 2565603579 BATT_bamDataLength_5 1;
BA_ "GenSigType" SG_ 2565603579 BATT_bamCtrlByte_5 1;
BA_ "GenSigType" SG_ 2565603579 BATT_bamPgn_5 1;
BA_ "GenSigType" SG_ 2565603579 BATT_bamNumOfPackets_5 1;
BA_ "GenSigType" SG_ 2565603579 BATT_bamResv_5 1;
BA_ "GenSigType" SG_ 2565603580 BATT_bamDataLength_6 1;
BA_ "GenSigType" SG_ 2565603580 BATT_bamCtrlByte_6 1;
BA_ "GenSigType" SG_ 2565603580 BATT_bamResv_6 1;
BA_ "GenSigType" SG_ 2565603580 BATT_bamPgn_6 1;
BA_ "GenSigType" SG_ 2565603580 BATT_bamNumOfPackets_6 1;
BA_ "GenSigType" SG_ 2565603581 BATT_bamResv_7 1;
BA_ "GenSigType" SG_ 2565603581 BATT_bamPgn_7 1;
BA_ "GenSigType" SG_ 2565603581 BATT_bamCtrlByte_7 1;
BA_ "GenSigType" SG_ 2565603581 BATT_bamNumOfPackets_7 1;
BA_ "GenSigType" SG_ 2565603581 BATT_bamDataLength_7 1;
BA_ "GenSigType" SG_ 2565603582 BATT_bamResv_8 1;
BA_ "GenSigType" SG_ 2565603582 BATT_bamDataLength_8 1;
BA_ "GenSigType" SG_ 2565603582 BATT_bamCtrlByte_8 1;
BA_ "GenSigType" SG_ 2565603582 BATT_bamPgn_8 1;
BA_ "GenSigType" SG_ 2565603582 BATT_bamNumOfPackets_8 1;
BA_ "GenSigType" SG_ 2565603583 BATT_bamCtrlByte_9 1;
BA_ "GenSigType" SG_ 2565603583 BATT_bamNumOfPackets_9 1;
BA_ "GenSigType" SG_ 2565603583 BATT_bamDataLength_9 1;
BA_ "GenSigType" SG_ 2565603583 BATT_bamResv_9 1;
BA_ "GenSigType" SG_ 2565603583 BATT_bamPgn_9 1;
BA_ "GenSigType" SG_ 2566834934 BATT_dm1SpnLsb_0 1;
BA_ "GenSigType" SG_ 2566834934 BATT_dm1SpnFmi_0 1;
BA_ "GenSigType" SG_ 2566834934 BATT_dm1ConvMethod_0 1;
BA_ "GenSigType" SG_ 2566834934 BATT_dm1FlashLampStatus_0 1;
BA_ "GenSigType" SG_ 2566834934 BATT_dm1LampStatus_0 1;
BA_ "GenSigType" SG_ 2566834934 BATT_dm1SpnMsb_0 1;
BA_ "GenSigType" SG_ 2566834934 BATT_dm1SpnIsb_0 1;
BA_ "GenSigType" SG_ 2566834935 BATT_dm1FlashLampStatus_1 1;
BA_ "GenSigType" SG_ 2566834935 BATT_dm1LampStatus_1 1;
BA_ "GenSigType" SG_ 2566834935 BATT_dm1SpnMsb_1 1;
BA_ "GenSigType" SG_ 2566834935 BATT_dm1SpnLsb_1 1;
BA_ "GenSigType" SG_ 2566834935 BATT_dm1SpnIsb_1 1;
BA_ "GenSigType" SG_ 2566834935 BATT_dm1SpnFmi_1 1;
BA_ "GenSigType" SG_ 2566834935 BATT_dm1ConvMethod_1 1;
BA_ "GenSigType" SG_ 2566834936 BATT_dm1SpnMsb_2 1;
BA_ "GenSigType" SG_ 2566834936 BATT_dm1SpnLsb_2 1;
BA_ "GenSigType" SG_ 2566834936 BATT_dm1LampStatus_2 1;
BA_ "GenSigType" SG_ 2566834936 BATT_dm1ConvMethod_2 1;
BA_ "GenSigType" SG_ 2566834936 BATT_dm1FlashLampStatus_2 1;
BA_ "GenSigType" SG_ 2566834936 BATT_dm1SpnIsb_2 1;
BA_ "GenSigType" SG_ 2566834936 BATT_dm1SpnFmi_2 1;
BA_ "GenSigType" SG_ 2566834937 BATT_dm1ConvMethod_3 1;
BA_ "GenSigType" SG_ 2566834937 BATT_dm1FlashLampStatus_3 1;
BA_ "GenSigType" SG_ 2566834937 BATT_dm1SpnLsb_3 1;
BA_ "GenSigType" SG_ 2566834937 BATT_dm1SpnIsb_3 1;
BA_ "GenSigType" SG_ 2566834937 BATT_dm1LampStatus_3 1;
BA_ "GenSigType" SG_ 2566834937 BATT_dm1SpnMsb_3 1;
BA_ "GenSigType" SG_ 2566834937 BATT_dm1SpnFmi_3 1;
BA_ "GenSigType" SG_ 2566834938 BATT_dm1SpnIsb_4 1;
BA_ "GenSigType" SG_ 2566834938 BATT_dm1LampStatus_4 1;
BA_ "GenSigType" SG_ 2566834938 BATT_dm1SpnMsb_4 1;
BA_ "GenSigType" SG_ 2566834938 BATT_dm1SpnLsb_4 1;
BA_ "GenSigType" SG_ 2566834938 BATT_dm1FlashLampStatus_4 1;
BA_ "GenSigType" SG_ 2566834938 BATT_dm1SpnFmi_4 1;
BA_ "GenSigType" SG_ 2566834938 BATT_dm1ConvMethod_4 1;
BA_ "GenSigType" SG_ 2566834939 BATT_dm1SpnFmi_5 1;
BA_ "GenSigType" SG_ 2566834939 BATT_dm1LampStatus_5 1;
BA_ "GenSigType" SG_ 2566834939 BATT_dm1FlashLampStatus_5 1;
BA_ "GenSigType" SG_ 2566834939 BATT_dm1ConvMethod_5 1;
BA_ "GenSigType" SG_ 2566834939 BATT_dm1SpnMsb_5 1;
BA_ "GenSigType" SG_ 2566834939 BATT_dm1SpnIsb_5 1;
BA_ "GenSigType" SG_ 2566834939 BATT_dm1SpnLsb_5 1;
BA_ "GenSigType" SG_ 2566834940 BATT_dm1ConvMethod_6 1;
BA_ "GenSigType" SG_ 2566834940 BATT_dm1SpnIsb_6 1;
BA_ "GenSigType" SG_ 2566834940 BATT_dm1SpnFmi_6 1;
BA_ "GenSigType" SG_ 2566834940 BATT_dm1LampStatus_6 1;
BA_ "GenSigType" SG_ 2566834940 BATT_dm1FlashLampStatus_6 1;
BA_ "GenSigType" SG_ 2566834940 BATT_dm1SpnMsb_6 1;
BA_ "GenSigType" SG_ 2566834940 BATT_dm1SpnLsb_6 1;
BA_ "GenSigType" SG_ 2566834941 BATT_dm1ConvMethod_7 1;
BA_ "GenSigType" SG_ 2566834941 BATT_dm1LampStatus_7 1;
BA_ "GenSigType" SG_ 2566834941 BATT_dm1FlashLampStatus_7 1;
BA_ "GenSigType" SG_ 2566834941 BATT_dm1SpnLsb_7 1;
BA_ "GenSigType" SG_ 2566834941 BATT_dm1SpnIsb_7 1;
BA_ "GenSigType" SG_ 2566834941 BATT_dm1SpnFmi_7 1;
BA_ "GenSigType" SG_ 2566834941 BATT_dm1SpnMsb_7 1;
BA_ "GenSigType" SG_ 2566834942 BATT_dm1SpnMsb_8 1;
BA_ "GenSigType" SG_ 2566834942 BATT_dm1ConvMethod_8 1;
BA_ "GenSigType" SG_ 2566834942 BATT_dm1SpnFmi_8 1;
BA_ "GenSigType" SG_ 2566834942 BATT_dm1LampStatus_8 1;
BA_ "GenSigType" SG_ 2566834942 BATT_dm1FlashLampStatus_8 1;
BA_ "GenSigType" SG_ 2566834942 BATT_dm1SpnLsb_8 1;
BA_ "GenSigType" SG_ 2566834942 BATT_dm1SpnIsb_8 1;
BA_ "GenSigType" SG_ 2566834943 BATT_dm1FlashLampStatus_9 1;
BA_ "GenSigType" SG_ 2566834943 BATT_dm1ConvMethod_9 1;
BA_ "GenSigType" SG_ 2566834943 BATT_dm1SpnFmi_9 1;
BA_ "GenSigType" SG_ 2566834943 BATT_dm1LampStatus_9 1;
BA_ "GenSigType" SG_ 2566834943 BATT_dm1SpnLsb_9 1;
BA_ "GenSigType" SG_ 2566834943 BATT_dm1SpnIsb_9 1;
BA_ "GenSigType" SG_ 2566834943 BATT_dm1SpnMsb_9 1;
BA_ "GenSigType" SG_ 2566835190 BATT_dm2SpnIsb_0 1;
BA_ "GenSigType" SG_ 2566835190 BATT_dm2SpnMsb_0 1;
BA_ "GenSigType" SG_ 2566835190 BATT_dm2SpnLsb_0 1;
BA_ "GenSigType" SG_ 2566835190 BATT_dm2FlashLampStatus_0 1;
BA_ "GenSigType" SG_ 2566835190 BATT_dm2LampStatus_0 1;
BA_ "GenSigType" SG_ 2566835190 BATT_dm2ConvMethod_0 1;
BA_ "GenSigType" SG_ 2566835190 BATT_dm2SpnFmi_0 1;
BA_ "GenSigType" SG_ 2566835191 BATT_dm2SpnMsb_1 1;
BA_ "GenSigType" SG_ 2566835191 BATT_dm2SpnLsb_1 1;
BA_ "GenSigType" SG_ 2566835191 BATT_dm2FlashLampStatus_1 1;
BA_ "GenSigType" SG_ 2566835191 BATT_dm2LampStatus_1 1;
BA_ "GenSigType" SG_ 2566835191 BATT_dm2ConvMethod_1 1;
BA_ "GenSigType" SG_ 2566835191 BATT_dm2SpnFmi_1 1;
BA_ "GenSigType" SG_ 2566835191 BATT_dm2SpnIsb_1 1;
BA_ "GenSigType" SG_ 2566835192 BATT_dm2SpnLsb_2 1;
BA_ "GenSigType" SG_ 2566835192 BATT_dm2SpnFmi_2 1;
BA_ "GenSigType" SG_ 2566835192 BATT_dm2SpnIsb_2 1;
BA_ "GenSigType" SG_ 2566835192 BATT_dm2ConvMethod_2 1;
BA_ "GenSigType" SG_ 2566835192 BATT_dm2FlashLampStatus_2 1;
BA_ "GenSigType" SG_ 2566835192 BATT_dm2SpnMsb_2 1;
BA_ "GenSigType" SG_ 2566835192 BATT_dm2LampStatus_2 1;
BA_ "GenSigType" SG_ 2566835193 BATT_dm2SpnIsb_3 1;
BA_ "GenSigType" SG_ 2566835193 BATT_dm2SpnLsb_3 1;
BA_ "GenSigType" SG_ 2566835193 BATT_dm2FlashLampStatus_3 1;
BA_ "GenSigType" SG_ 2566835193 BATT_dm2ConvMethod_3 1;
BA_ "GenSigType" SG_ 2566835193 BATT_dm2SpnMsb_3 1;
BA_ "GenSigType" SG_ 2566835193 BATT_dm2LampStatus_3 1;
BA_ "GenSigType" SG_ 2566835193 BATT_dm2SpnFmi_3 1;
BA_ "GenSigType" SG_ 2566835194 BATT_dm2SpnLsb_4 1;
BA_ "GenSigType" SG_ 2566835194 BATT_dm2LampStatus_4 1;
BA_ "GenSigType" SG_ 2566835194 BATT_dm2SpnFmi_4 1;
BA_ "GenSigType" SG_ 2566835194 BATT_dm2FlashLampStatus_4 1;
BA_ "GenSigType" SG_ 2566835194 BATT_dm2SpnMsb_4 1;
BA_ "GenSigType" SG_ 2566835194 BATT_dm2SpnIsb_4 1;
BA_ "GenSigType" SG_ 2566835194 BATT_dm2ConvMethod_4 1;
BA_ "GenSigType" SG_ 2566835195 BATT_dm2SpnIsb_5 1;
BA_ "GenSigType" SG_ 2566835195 BATT_dm2SpnFmi_5 1;
BA_ "GenSigType" SG_ 2566835195 BATT_dm2ConvMethod_5 1;
BA_ "GenSigType" SG_ 2566835195 BATT_dm2SpnLsb_5 1;
BA_ "GenSigType" SG_ 2566835195 BATT_dm2LampStatus_5 1;
BA_ "GenSigType" SG_ 2566835195 BATT_dm2SpnMsb_5 1;
BA_ "GenSigType" SG_ 2566835195 BATT_dm2FlashLampStatus_5 1;
BA_ "GenSigType" SG_ 2566835196 BATT_dm2SpnMsb_6 1;
BA_ "GenSigType" SG_ 2566835196 BATT_dm2LampStatus_6 1;
BA_ "GenSigType" SG_ 2566835196 BATT_dm2SpnFmi_6 1;
BA_ "GenSigType" SG_ 2566835196 BATT_dm2SpnLsb_6 1;
BA_ "GenSigType" SG_ 2566835196 BATT_dm2SpnIsb_6 1;
BA_ "GenSigType" SG_ 2566835196 BATT_dm2ConvMethod_6 1;
BA_ "GenSigType" SG_ 2566835196 BATT_dm2FlashLampStatus_6 1;
BA_ "GenSigType" SG_ 2566835197 BATT_dm2SpnIsb_7 1;
BA_ "GenSigType" SG_ 2566835197 BATT_dm2SpnLsb_7 1;
BA_ "GenSigType" SG_ 2566835197 BATT_dm2SpnFmi_7 1;
BA_ "GenSigType" SG_ 2566835197 BATT_dm2ConvMethod_7 1;
BA_ "GenSigType" SG_ 2566835197 BATT_dm2FlashLampStatus_7 1;
BA_ "GenSigType" SG_ 2566835197 BATT_dm2SpnMsb_7 1;
BA_ "GenSigType" SG_ 2566835197 BATT_dm2LampStatus_7 1;
BA_ "GenSigType" SG_ 2566835198 BATT_dm2SpnLsb_8 1;
BA_ "GenSigType" SG_ 2566835198 BATT_dm2ConvMethod_8 1;
BA_ "GenSigType" SG_ 2566835198 BATT_dm2SpnFmi_8 1;
BA_ "GenSigType" SG_ 2566835198 BATT_dm2SpnIsb_8 1;
BA_ "GenSigType" SG_ 2566835198 BATT_dm2SpnMsb_8 1;
BA_ "GenSigType" SG_ 2566835198 BATT_dm2FlashLampStatus_8 1;
BA_ "GenSigType" SG_ 2566835198 BATT_dm2LampStatus_8 1;
BA_ "GenSigType" SG_ 2566835199 BATT_dm2SpnIsb_9 1;
BA_ "GenSigType" SG_ 2566835199 BATT_dm2FlashLampStatus_9 1;
BA_ "GenSigType" SG_ 2566835199 BATT_dm2SpnMsb_9 1;
BA_ "GenSigType" SG_ 2566835199 BATT_dm2ConvMethod_9 1;
BA_ "GenSigType" SG_ 2566835199 BATT_dm2LampStatus_9 1;
BA_ "GenSigType" SG_ 2566835199 BATT_dm2SpnLsb_9 1;
BA_ "GenSigType" SG_ 2566835199 BATT_dm2SpnFmi_9 1;
BA_ "GenSigType" SG_ 2566849014 BATT_iModDchLimitCont_0 0;
BA_ "GenSigType" SG_ 2566849014 BATT_vModDchLimit_0 0;
BA_ "GenSigType" SG_ 2566849014 BATT_iModDchLimit30s_0 0;
BA_ "GenSigType" SG_ 2566849015 BATT_vModDchLimit_1 0;
BA_ "GenSigType" SG_ 2566849015 BATT_iModDchLimitCont_1 0;
BA_ "GenSigType" SG_ 2566849015 BATT_iModDchLimit30s_1 0;
BA_ "GenSigType" SG_ 2566849016 BATT_iModDchLimitCont_2 0;
BA_ "GenSigType" SG_ 2566849016 BATT_iModDchLimit30s_2 0;
BA_ "GenSigType" SG_ 2566849016 BATT_vModDchLimit_2 0;
BA_ "GenSigType" SG_ 2566849017 BATT_iModDchLimitCont_3 0;
BA_ "GenSigType" SG_ 2566849017 BATT_vModDchLimit_3 0;
BA_ "GenSigType" SG_ 2566849017 BATT_iModDchLimit30s_3 0;
BA_ "GenSigType" SG_ 2566849018 BATT_iModDchLimitCont_4 0;
BA_ "GenSigType" SG_ 2566849018 BATT_iModDchLimit30s_4 0;
BA_ "GenSigType" SG_ 2566849018 BATT_vModDchLimit_4 0;
BA_ "GenSigType" SG_ 2566849019 BATT_vModDchLimit_5 0;
BA_ "GenSigType" SG_ 2566849019 BATT_iModDchLimit30s_5 0;
BA_ "GenSigType" SG_ 2566849019 BATT_iModDchLimitCont_5 0;
BA_ "GenSigType" SG_ 2566849020 BATT_iModDchLimit30s_6 0;
BA_ "GenSigType" SG_ 2566849020 BATT_vModDchLimit_6 0;
BA_ "GenSigType" SG_ 2566849020 BATT_iModDchLimitCont_6 0;
BA_ "GenSigType" SG_ 2566849021 BATT_iModDchLimit30s_7 0;
BA_ "GenSigType" SG_ 2566849021 BATT_vModDchLimit_7 0;
BA_ "GenSigType" SG_ 2566849021 BATT_iModDchLimitCont_7 0;
BA_ "GenSigType" SG_ 2566849022 BATT_iModDchLimit30s_8 0;
BA_ "GenSigType" SG_ 2566849022 BATT_vModDchLimit_8 0;
BA_ "GenSigType" SG_ 2566849022 BATT_iModDchLimitCont_8 0;
BA_ "GenSigType" SG_ 2566849023 BATT_vModDchLimit_9 0;
BA_ "GenSigType" SG_ 2566849023 BATT_iModDchLimit30s_9 0;
BA_ "GenSigType" SG_ 2566849023 BATT_iModDchLimitCont_9 0;
BA_ "GenSigType" SG_ 2566851062 BATT_tModule2 0;
BA_ "GenSigType" SG_ 2566851062 BATT_tModule1 0;
BA_ "GenSigType" SG_ 2566851062 BATT_tBoard 0;
BA_ "GenSigType" SG_ 2566851318 BATT_modUVP_0 1;
BA_ "GenSigType" SG_ 2566851318 BATT_modWeldStat_0 1;
BA_ "GenSigType" SG_ 2566851318 BATT_ArbitrationComplete_0 1;
BA_ "GenSigType" SG_ 2566851318 BATT_modStateRequested_0 0;
BA_ "GenSigType" SG_ 2566851318 BATT_prechargeState_0 0;
BA_ "GenSigType" SG_ 2566851318 BATT_fetPchgCommand_0 0;
BA_ "GenSigType" SG_ 2566851318 BATT_fetDsgCommand_0 0;
BA_ "GenSigType" SG_ 2566851318 BATT_fetChgCommand_0 0;
BA_ "GenSigType" SG_ 2566851318 BATT_fetDsgStatus_0 0;
BA_ "GenSigType" SG_ 2566851318 BATT_fetChgStatus_0 0;
BA_ "GenSigType" SG_ 2566851318 BATT_inhRegen_0 1;
BA_ "GenSigType" SG_ 2566851318 BATT_inhFullPower_0 1;
BA_ "GenSigType" SG_ 2566851318 BATT_inhDriveEntry_0 1;
BA_ "GenSigType" SG_ 2566851318 BATT_inhDrive_0 1;
BA_ "GenSigType" SG_ 2566851318 BATT_inhContPower_0 1;
BA_ "GenSigType" SG_ 2566851318 BATT_inhChargeEntry_0 1;
BA_ "GenSigType" SG_ 2566851318 BATT_inhCharge_0 1;
BA_ "GenSigType" SG_ 2566851318 BATT_modPackState_0 0;
BA_ "GenSigType" SG_ 2566851318 BATT_modChildState_0 0;
BA_ "GenSigType" SG_ 2566851318 BATT_modParentState_0 0;
BA_ "GenSigType" SG_ 2566851319 BATT_modUVP_1 1;
BA_ "GenSigType" SG_ 2566851319 BATT_modWeldStat_1 1;
BA_ "GenSigType" SG_ 2566851319 BATT_ArbitrationComplete_1 1;
BA_ "GenSigType" SG_ 2566851319 BATT_modStateRequested_1 0;
BA_ "GenSigType" SG_ 2566851319 BATT_prechargeState_1 0;
BA_ "GenSigType" SG_ 2566851319 BATT_fetPchgCommand_1 0;
BA_ "GenSigType" SG_ 2566851319 BATT_fetDsgCommand_1 0;
BA_ "GenSigType" SG_ 2566851319 BATT_fetChgCommand_1 0;
BA_ "GenSigType" SG_ 2566851319 BATT_fetDsgStatus_1 0;
BA_ "GenSigType" SG_ 2566851319 BATT_fetChgStatus_1 0;
BA_ "GenSigType" SG_ 2566851319 BATT_inhRegen_1 1;
BA_ "GenSigType" SG_ 2566851319 BATT_inhFullPower_1 1;
BA_ "GenSigType" SG_ 2566851319 BATT_inhDriveEntry_1 1;
BA_ "GenSigType" SG_ 2566851319 BATT_inhDrive_1 1;
BA_ "GenSigType" SG_ 2566851319 BATT_inhContPower_1 1;
BA_ "GenSigType" SG_ 2566851319 BATT_inhChargeEntry_1 1;
BA_ "GenSigType" SG_ 2566851319 BATT_inhCharge_1 1;
BA_ "GenSigType" SG_ 2566851319 BATT_modPackState_1 0;
BA_ "GenSigType" SG_ 2566851319 BATT_modChildState_1 0;
BA_ "GenSigType" SG_ 2566851319 BATT_modParentState_1 0;
BA_ "GenSigType" SG_ 2566851320 BATT_modUVP_2 1;
BA_ "GenSigType" SG_ 2566851320 BATT_modWeldStat_2 1;
BA_ "GenSigType" SG_ 2566851320 BATT_ArbitrationComplete_2 1;
BA_ "GenSigType" SG_ 2566851320 BATT_modStateRequested_2 0;
BA_ "GenSigType" SG_ 2566851320 BATT_prechargeState_2 0;
BA_ "GenSigType" SG_ 2566851320 BATT_fetPchgCommand_2 0;
BA_ "GenSigType" SG_ 2566851320 BATT_fetDsgCommand_2 0;
BA_ "GenSigType" SG_ 2566851320 BATT_fetChgCommand_2 0;
BA_ "GenSigType" SG_ 2566851320 BATT_fetDsgStatus_2 0;
BA_ "GenSigType" SG_ 2566851320 BATT_fetChgStatus_2 0;
BA_ "GenSigType" SG_ 2566851320 BATT_inhRegen_2 1;
BA_ "GenSigType" SG_ 2566851320 BATT_inhFullPower_2 1;
BA_ "GenSigType" SG_ 2566851320 BATT_inhDriveEntry_2 1;
BA_ "GenSigType" SG_ 2566851320 BATT_inhDrive_2 1;
BA_ "GenSigType" SG_ 2566851320 BATT_inhContPower_2 1;
BA_ "GenSigType" SG_ 2566851320 BATT_inhChargeEntry_2 1;
BA_ "GenSigType" SG_ 2566851320 BATT_inhCharge_2 1;
BA_ "GenSigType" SG_ 2566851320 BATT_modPackState_2 0;
BA_ "GenSigType" SG_ 2566851320 BATT_modChildState_2 0;
BA_ "GenSigType" SG_ 2566851320 BATT_modParentState_2 0;
BA_ "GenSigType" SG_ 2566851321 BATT_modUVP_3 1;
BA_ "GenSigType" SG_ 2566851321 BATT_modWeldStat_3 1;
BA_ "GenSigType" SG_ 2566851321 BATT_ArbitrationComplete_3 1;
BA_ "GenSigType" SG_ 2566851321 BATT_modStateRequested_3 0;
BA_ "GenSigType" SG_ 2566851321 BATT_prechargeState_3 0;
BA_ "GenSigType" SG_ 2566851321 BATT_fetPchgCommand_3 0;
BA_ "GenSigType" SG_ 2566851321 BATT_fetDsgCommand_3 0;
BA_ "GenSigType" SG_ 2566851321 BATT_fetChgCommand_3 0;
BA_ "GenSigType" SG_ 2566851321 BATT_fetDsgStatus_3 0;
BA_ "GenSigType" SG_ 2566851321 BATT_fetChgStatus_3 0;
BA_ "GenSigType" SG_ 2566851321 BATT_inhRegen_3 1;
BA_ "GenSigType" SG_ 2566851321 BATT_inhFullPower_3 1;
BA_ "GenSigType" SG_ 2566851321 BATT_inhDriveEntry_3 1;
BA_ "GenSigType" SG_ 2566851321 BATT_inhDrive_3 1;
BA_ "GenSigType" SG_ 2566851321 BATT_inhContPower_3 1;
BA_ "GenSigType" SG_ 2566851321 BATT_inhChargeEntry_3 1;
BA_ "GenSigType" SG_ 2566851321 BATT_inhCharge_3 1;
BA_ "GenSigType" SG_ 2566851321 BATT_modPackState_3 0;
BA_ "GenSigType" SG_ 2566851321 BATT_modChildState_3 0;
BA_ "GenSigType" SG_ 2566851321 BATT_modParentState_3 0;
BA_ "GenSigType" SG_ 2566851322 BATT_modUVP_4 1;
BA_ "GenSigType" SG_ 2566851322 BATT_modWeldStat_4 1;
BA_ "GenSigType" SG_ 2566851322 BATT_ArbitrationComplete_4 1;
BA_ "GenSigType" SG_ 2566851322 BATT_modStateRequested_4 0;
BA_ "GenSigType" SG_ 2566851322 BATT_prechargeState_4 0;
BA_ "GenSigType" SG_ 2566851322 BATT_fetPchgCommand_4 0;
BA_ "GenSigType" SG_ 2566851322 BATT_fetDsgCommand_4 0;
BA_ "GenSigType" SG_ 2566851322 BATT_fetChgCommand_4 0;
BA_ "GenSigType" SG_ 2566851322 BATT_fetDsgStatus_4 0;
BA_ "GenSigType" SG_ 2566851322 BATT_fetChgStatus_4 0;
BA_ "GenSigType" SG_ 2566851322 BATT_inhRegen_4 1;
BA_ "GenSigType" SG_ 2566851322 BATT_inhFullPower_4 1;
BA_ "GenSigType" SG_ 2566851322 BATT_inhDriveEntry_4 1;
BA_ "GenSigType" SG_ 2566851322 BATT_inhDrive_4 1;
BA_ "GenSigType" SG_ 2566851322 BATT_inhContPower_4 1;
BA_ "GenSigType" SG_ 2566851322 BATT_inhChargeEntry_4 1;
BA_ "GenSigType" SG_ 2566851322 BATT_inhCharge_4 1;
BA_ "GenSigType" SG_ 2566851322 BATT_modPackState_4 0;
BA_ "GenSigType" SG_ 2566851322 BATT_modChildState_4 0;
BA_ "GenSigType" SG_ 2566851322 BATT_modParentState_4 0;
BA_ "GenSigType" SG_ 2566851323 BATT_modUVP_5 1;
BA_ "GenSigType" SG_ 2566851323 BATT_modWeldStat_5 1;
BA_ "GenSigType" SG_ 2566851323 BATT_ArbitrationComplete_5 1;
BA_ "GenSigType" SG_ 2566851323 BATT_modStateRequested_5 0;
BA_ "GenSigType" SG_ 2566851323 BATT_prechargeState_5 0;
BA_ "GenSigType" SG_ 2566851323 BATT_fetPchgCommand_5 0;
BA_ "GenSigType" SG_ 2566851323 BATT_fetDsgCommand_5 0;
BA_ "GenSigType" SG_ 2566851323 BATT_fetChgCommand_5 0;
BA_ "GenSigType" SG_ 2566851323 BATT_fetDsgStatus_5 0;
BA_ "GenSigType" SG_ 2566851323 BATT_fetChgStatus_5 0;
BA_ "GenSigType" SG_ 2566851323 BATT_inhRegen_5 1;
BA_ "GenSigType" SG_ 2566851323 BATT_inhFullPower_5 1;
BA_ "GenSigType" SG_ 2566851323 BATT_inhDriveEntry_5 1;
BA_ "GenSigType" SG_ 2566851323 BATT_inhDrive_5 1;
BA_ "GenSigType" SG_ 2566851323 BATT_inhContPower_5 1;
BA_ "GenSigType" SG_ 2566851323 BATT_inhChargeEntry_5 1;
BA_ "GenSigType" SG_ 2566851323 BATT_inhCharge_5 1;
BA_ "GenSigType" SG_ 2566851323 BATT_modPackState_5 0;
BA_ "GenSigType" SG_ 2566851323 BATT_modChildState_5 0;
BA_ "GenSigType" SG_ 2566851323 BATT_modParentState_5 0;
BA_ "GenSigType" SG_ 2566851324 BATT_modPackState_6 0;
BA_ "GenSigType" SG_ 2566851324 BATT_modChildState_6 0;
BA_ "GenSigType" SG_ 2566851324 BATT_modParentState_6 0;
BA_ "GenSigType" SG_ 2566851324 BATT_modUVP_6 1;
BA_ "GenSigType" SG_ 2566851324 BATT_modWeldStat_6 1;
BA_ "GenSigType" SG_ 2566851324 BATT_ArbitrationComplete_6 1;
BA_ "GenSigType" SG_ 2566851324 BATT_modStateRequested_6 0;
BA_ "GenSigType" SG_ 2566851324 BATT_prechargeState_6 0;
BA_ "GenSigType" SG_ 2566851324 BATT_fetPchgCommand_6 0;
BA_ "GenSigType" SG_ 2566851324 BATT_fetDsgCommand_6 0;
BA_ "GenSigType" SG_ 2566851324 BATT_fetChgCommand_6 0;
BA_ "GenSigType" SG_ 2566851324 BATT_fetDsgStatus_6 0;
BA_ "GenSigType" SG_ 2566851324 BATT_fetChgStatus_6 0;
BA_ "GenSigType" SG_ 2566851324 BATT_inhRegen_6 1;
BA_ "GenSigType" SG_ 2566851324 BATT_inhFullPower_6 1;
BA_ "GenSigType" SG_ 2566851324 BATT_inhDriveEntry_6 1;
BA_ "GenSigType" SG_ 2566851324 BATT_inhDrive_6 1;
BA_ "GenSigType" SG_ 2566851324 BATT_inhContPower_6 1;
BA_ "GenSigType" SG_ 2566851324 BATT_inhChargeEntry_6 1;
BA_ "GenSigType" SG_ 2566851324 BATT_inhCharge_6 1;
BA_ "GenSigType" SG_ 2566851325 BATT_modUVP_7 1;
BA_ "GenSigType" SG_ 2566851325 BATT_modWeldStat_7 1;
BA_ "GenSigType" SG_ 2566851325 BATT_ArbitrationComplete_7 1;
BA_ "GenSigType" SG_ 2566851325 BATT_modStateRequested_7 0;
BA_ "GenSigType" SG_ 2566851325 BATT_prechargeState_7 0;
BA_ "GenSigType" SG_ 2566851325 BATT_fetPchgCommand_7 0;
BA_ "GenSigType" SG_ 2566851325 BATT_fetDsgCommand_7 0;
BA_ "GenSigType" SG_ 2566851325 BATT_fetChgCommand_7 0;
BA_ "GenSigType" SG_ 2566851325 BATT_fetDsgStatus_7 0;
BA_ "GenSigType" SG_ 2566851325 BATT_fetChgStatus_7 0;
BA_ "GenSigType" SG_ 2566851325 BATT_inhRegen_7 1;
BA_ "GenSigType" SG_ 2566851325 BATT_inhFullPower_7 1;
BA_ "GenSigType" SG_ 2566851325 BATT_inhDriveEntry_7 1;
BA_ "GenSigType" SG_ 2566851325 BATT_inhDrive_7 1;
BA_ "GenSigType" SG_ 2566851325 BATT_inhContPower_7 1;
BA_ "GenSigType" SG_ 2566851325 BATT_inhChargeEntry_7 1;
BA_ "GenSigType" SG_ 2566851325 BATT_inhCharge_7 1;
BA_ "GenSigType" SG_ 2566851325 BATT_modPackState_7 0;
BA_ "GenSigType" SG_ 2566851325 BATT_modChildState_7 0;
BA_ "GenSigType" SG_ 2566851325 BATT_modParentState_7 0;
BA_ "GenSigType" SG_ 2566851326 BATT_modUVP_8 1;
BA_ "GenSigType" SG_ 2566851326 BATT_modWeldStat_8 1;
BA_ "GenSigType" SG_ 2566851326 BATT_ArbitrationComplete_8 1;
BA_ "GenSigType" SG_ 2566851326 BATT_modStateRequested_8 0;
BA_ "GenSigType" SG_ 2566851326 BATT_prechargeState_8 0;
BA_ "GenSigType" SG_ 2566851326 BATT_fetPchgCommand_8 0;
BA_ "GenSigType" SG_ 2566851326 BATT_fetDsgCommand_8 0;
BA_ "GenSigType" SG_ 2566851326 BATT_fetChgCommand_8 0;
BA_ "GenSigType" SG_ 2566851326 BATT_fetDsgStatus_8 0;
BA_ "GenSigType" SG_ 2566851326 BATT_fetChgStatus_8 0;
BA_ "GenSigType" SG_ 2566851326 BATT_inhRegen_8 1;
BA_ "GenSigType" SG_ 2566851326 BATT_inhFullPower_8 1;
BA_ "GenSigType" SG_ 2566851326 BATT_inhDriveEntry_8 1;
BA_ "GenSigType" SG_ 2566851326 BATT_inhDrive_8 1;
BA_ "GenSigType" SG_ 2566851326 BATT_inhContPower_8 1;
BA_ "GenSigType" SG_ 2566851326 BATT_inhChargeEntry_8 1;
BA_ "GenSigType" SG_ 2566851326 BATT_inhCharge_8 1;
BA_ "GenSigType" SG_ 2566851326 BATT_modPackState_8 0;
BA_ "GenSigType" SG_ 2566851326 BATT_modChildState_8 0;
BA_ "GenSigType" SG_ 2566851326 BATT_modParentState_8 0;
BA_ "GenSigType" SG_ 2566851327 BATT_modUVP_9 1;
BA_ "GenSigType" SG_ 2566851327 BATT_modWeldStat_9 1;
BA_ "GenSigType" SG_ 2566851327 BATT_ArbitrationComplete_9 1;
BA_ "GenSigType" SG_ 2566851327 BATT_modStateRequested_9 0;
BA_ "GenSigType" SG_ 2566851327 BATT_prechargeState_9 0;
BA_ "GenSigType" SG_ 2566851327 BATT_fetPchgCommand_9 0;
BA_ "GenSigType" SG_ 2566851327 BATT_fetDsgCommand_9 0;
BA_ "GenSigType" SG_ 2566851327 BATT_fetChgCommand_9 0;
BA_ "GenSigType" SG_ 2566851327 BATT_fetDsgStatus_9 0;
BA_ "GenSigType" SG_ 2566851327 BATT_fetChgStatus_9 0;
BA_ "GenSigType" SG_ 2566851327 BATT_inhRegen_9 1;
BA_ "GenSigType" SG_ 2566851327 BATT_inhFullPower_9 1;
BA_ "GenSigType" SG_ 2566851327 BATT_inhDriveEntry_9 1;
BA_ "GenSigType" SG_ 2566851327 BATT_inhDrive_9 1;
BA_ "GenSigType" SG_ 2566851327 BATT_inhContPower_9 1;
BA_ "GenSigType" SG_ 2566851327 BATT_inhChargeEntry_9 1;
BA_ "GenSigType" SG_ 2566851327 BATT_inhCharge_9 1;
BA_ "GenSigType" SG_ 2566851327 BATT_modPackState_9 0;
BA_ "GenSigType" SG_ 2566851327 BATT_modChildState_9 0;
BA_ "GenSigType" SG_ 2566851327 BATT_modParentState_9 0;
BA_ "GenSigType" SG_ 2566851830 BATT_vMod_0 0;
BA_ "GenSigType" SG_ 2566851830 BATT_vModSumOfCells_0 0;
BA_ "GenSigType" SG_ 2566851830 BATT_iMod_0 0;
BA_ "GenSigType" SG_ 2566851830 BATT_iModFiltered_0 0;
BA_ "GenSigType" SG_ 2566851831 BATT_vMod_1 0;
BA_ "GenSigType" SG_ 2566851831 BATT_vModSumOfCells_1 0;
BA_ "GenSigType" SG_ 2566851831 BATT_iMod_1 0;
BA_ "GenSigType" SG_ 2566851831 BATT_iModFiltered_1 0;
BA_ "GenSigType" SG_ 2566851832 BATT_vMod_2 0;
BA_ "GenSigType" SG_ 2566851832 BATT_vModSumOfCells_2 0;
BA_ "GenSigType" SG_ 2566851832 BATT_iMod_2 0;
BA_ "GenSigType" SG_ 2566851832 BATT_iModFiltered_2 0;
BA_ "GenSigType" SG_ 2566851833 BATT_vMod_3 0;
BA_ "GenSigType" SG_ 2566851833 BATT_vModSumOfCells_3 0;
BA_ "GenSigType" SG_ 2566851833 BATT_iMod_3 0;
BA_ "GenSigType" SG_ 2566851833 BATT_iModFiltered_3 0;
BA_ "GenSigType" SG_ 2566851834 BATT_vMod_4 0;
BA_ "GenSigType" SG_ 2566851834 BATT_vModSumOfCells_4 0;
BA_ "GenSigType" SG_ 2566851834 BATT_iMod_4 0;
BA_ "GenSigType" SG_ 2566851834 BATT_iModFiltered_4 0;
BA_ "GenSigType" SG_ 2566851835 BATT_vMod_5 0;
BA_ "GenSigType" SG_ 2566851835 BATT_vModSumOfCells_5 0;
BA_ "GenSigType" SG_ 2566851835 BATT_iMod_5 0;
BA_ "GenSigType" SG_ 2566851835 BATT_iModFiltered_5 0;
BA_ "GenSigType" SG_ 2566851836 BATT_vMod_6 0;
BA_ "GenSigType" SG_ 2566851836 BATT_vModSumOfCells_6 0;
BA_ "GenSigType" SG_ 2566851836 BATT_iMod_6 0;
BA_ "GenSigType" SG_ 2566851836 BATT_iModFiltered_6 0;
BA_ "GenSigType" SG_ 2566851837 BATT_vMod_7 0;
BA_ "GenSigType" SG_ 2566851837 BATT_vModSumOfCells_7 0;
BA_ "GenSigType" SG_ 2566851837 BATT_iMod_7 0;
BA_ "GenSigType" SG_ 2566851837 BATT_iModFiltered_7 0;
BA_ "GenSigType" SG_ 2566851838 BATT_vMod_8 0;
BA_ "GenSigType" SG_ 2566851838 BATT_vModSumOfCells_8 0;
BA_ "GenSigType" SG_ 2566851838 BATT_iMod_8 0;
BA_ "GenSigType" SG_ 2566851838 BATT_iModFiltered_8 0;
BA_ "GenSigSNA" SG_ 2565341429 BATT_dm11Resv 65535;
BA_ "GenSigSNA" SG_ 2565472502 BATT_dm1ReqPgn_0 65535;
BA_ "GenSigSNA" SG_ 2565472503 BATT_dm1ReqPgn_1 65535;
BA_ "GenSigSNA" SG_ 2565472504 BATT_dm1ReqPgn_2 65535;
BA_ "GenSigSNA" SG_ 2565472505 BATT_dm1ReqPgn_3 65535;
BA_ "GenSigSNA" SG_ 2565472506 BATT_dm1ReqPgn_4 65535;
BA_ "GenSigSNA" SG_ 2565472507 BATT_dm1ReqPgn_5 65535;
BA_ "GenSigSNA" SG_ 2565472508 BATT_dm1ReqPgn_6 65535;
BA_ "GenSigSNA" SG_ 2565472509 BATT_dm1ReqPgn_7 65535;
BA_ "GenSigSNA" SG_ 2565472510 BATT_dm1ReqPgn_8 65535;
BA_ "GenSigSNA" SG_ 2565472511 BATT_dm1ReqPgn_9 65535;
BA_ "GenSigSNA" SG_ 2565538038 BATT_dmSeqNum_0 65535;
BA_ "GenSigSNA" SG_ 2565538038 BATT_dmPayLoad_0 65535;
BA_ "GenSigSNA" SG_ 2565538039 BATT_dmPayLoad_1 65535;
BA_ "GenSigSNA" SG_ 2565538039 BATT_dmSeqNum_1 65535;
BA_ "GenSigSNA" SG_ 2565538040 BATT_dmPayLoad_2 65535;
BA_ "GenSigSNA" SG_ 2565538040 BATT_dmSeqNum_2 65535;
BA_ "GenSigSNA" SG_ 2565538041 BATT_dmSeqNum_3 65535;
BA_ "GenSigSNA" SG_ 2565538041 BATT_dmPayLoad_3 65535;
BA_ "GenSigSNA" SG_ 2565538042 BATT_dmPayLoad_4 65535;
BA_ "GenSigSNA" SG_ 2565538042 BATT_dmSeqNum_4 65535;
BA_ "GenSigSNA" SG_ 2565538043 BATT_dmPayLoad_5 65535;
BA_ "GenSigSNA" SG_ 2565538043 BATT_dmSeqNum_5 65535;
BA_ "GenSigSNA" SG_ 2565538044 BATT_dmSeqNum_6 65535;
BA_ "GenSigSNA" SG_ 2565538044 BATT_dmPayLoad_6 65535;
BA_ "GenSigSNA" SG_ 2565538045 BATT_dmSeqNum_7 65535;
BA_ "GenSigSNA" SG_ 2565538045 BATT_dmPayLoad_7 65535;
BA_ "GenSigSNA" SG_ 2565538046 BATT_dmSeqNum_8 65535;
BA_ "GenSigSNA" SG_ 2565538046 BATT_dmPayLoad_8 65535;
BA_ "GenSigSNA" SG_ 2565538047 BATT_dmSeqNum_9 65535;
BA_ "GenSigSNA" SG_ 2565538047 BATT_dmPayLoad_9 65535;
BA_ "GenSigSNA" SG_ 2565603574 BATT_bamResv_0 65535;
BA_ "GenSigSNA" SG_ 2565603574 BATT_bamPgn_0 65535;
BA_ "GenSigSNA" SG_ 2565603574 BATT_bamNumOfPackets_0 65535;
BA_ "GenSigSNA" SG_ 2565603574 BATT_bamDataLength_0 65535;
BA_ "GenSigSNA" SG_ 2565603574 BATT_bamCtrlByte_0 65535;
BA_ "GenSigSNA" SG_ 2565603575 BATT_bamResv_1 65535;
BA_ "GenSigSNA" SG_ 2565603575 BATT_bamPgn_1 65535;
BA_ "GenSigSNA" SG_ 2565603575 BATT_bamNumOfPackets_1 65535;
BA_ "GenSigSNA" SG_ 2565603575 BATT_bamDataLength_1 65535;
BA_ "GenSigSNA" SG_ 2565603575 BATT_bamCtrlByte_1 65535;
BA_ "GenSigSNA" SG_ 2565603576 BATT_bamResv_2 65535;
BA_ "GenSigSNA" SG_ 2565603576 BATT_bamPgn_2 65535;
BA_ "GenSigSNA" SG_ 2565603576 BATT_bamNumOfPackets_2 65535;
BA_ "GenSigSNA" SG_ 2565603576 BATT_bamDataLength_2 65535;
BA_ "GenSigSNA" SG_ 2565603576 BATT_bamCtrlByte_2 65535;
BA_ "GenSigSNA" SG_ 2565603577 BATT_bamResv_3 65535;
BA_ "GenSigSNA" SG_ 2565603577 BATT_bamPgn_3 65535;
BA_ "GenSigSNA" SG_ 2565603577 BATT_bamNumOfPackets_3 65535;
BA_ "GenSigSNA" SG_ 2565603577 BATT_bamDataLength_3 65535;
BA_ "GenSigSNA" SG_ 2565603577 BATT_bamCtrlByte_3 65535;
BA_ "GenSigSNA" SG_ 2565603578 BATT_bamPgn_4 65535;
BA_ "GenSigSNA" SG_ 2565603578 BATT_bamResv_4 65535;
BA_ "GenSigSNA" SG_ 2565603578 BATT_bamNumOfPackets_4 65535;
BA_ "GenSigSNA" SG_ 2565603578 BATT_bamDataLength_4 65535;
BA_ "GenSigSNA" SG_ 2565603578 BATT_bamCtrlByte_4 65535;
BA_ "GenSigSNA" SG_ 2565603579 BATT_bamDataLength_5 65535;
BA_ "GenSigSNA" SG_ 2565603579 BATT_bamCtrlByte_5 65535;
BA_ "GenSigSNA" SG_ 2565603579 BATT_bamPgn_5 65535;
BA_ "GenSigSNA" SG_ 2565603579 BATT_bamNumOfPackets_5 65535;
BA_ "GenSigSNA" SG_ 2565603579 BATT_bamResv_5 65535;
BA_ "GenSigSNA" SG_ 2565603580 BATT_bamDataLength_6 65535;
BA_ "GenSigSNA" SG_ 2565603580 BATT_bamCtrlByte_6 65535;
BA_ "GenSigSNA" SG_ 2565603580 BATT_bamResv_6 65535;
BA_ "GenSigSNA" SG_ 2565603580 BATT_bamPgn_6 65535;
BA_ "GenSigSNA" SG_ 2565603580 BATT_bamNumOfPackets_6 65535;
BA_ "GenSigSNA" SG_ 2565603581 BATT_bamResv_7 65535;
BA_ "GenSigSNA" SG_ 2565603581 BATT_bamPgn_7 65535;
BA_ "GenSigSNA" SG_ 2565603581 BATT_bamCtrlByte_7 65535;
BA_ "GenSigSNA" SG_ 2565603581 BATT_bamNumOfPackets_7 65535;
BA_ "GenSigSNA" SG_ 2565603581 BATT_bamDataLength_7 65535;
BA_ "GenSigSNA" SG_ 2565603582 BATT_bamResv_8 65535;
BA_ "GenSigSNA" SG_ 2565603582 BATT_bamDataLength_8 65535;
BA_ "GenSigSNA" SG_ 2565603582 BATT_bamCtrlByte_8 65535;
BA_ "GenSigSNA" SG_ 2565603582 BATT_bamPgn_8 65535;
BA_ "GenSigSNA" SG_ 2565603582 BATT_bamNumOfPackets_8 65535;
BA_ "GenSigSNA" SG_ 2565603583 BATT_bamCtrlByte_9 65535;
BA_ "GenSigSNA" SG_ 2565603583 BATT_bamNumOfPackets_9 65535;
BA_ "GenSigSNA" SG_ 2565603583 BATT_bamDataLength_9 65535;
BA_ "GenSigSNA" SG_ 2565603583 BATT_bamResv_9 65535;
BA_ "GenSigSNA" SG_ 2565603583 BATT_bamPgn_9 65535;
BA_ "GenSigSNA" SG_ 2566834934 BATT_dm1SpnLsb_0 65535;
BA_ "GenSigSNA" SG_ 2566834934 BATT_dm1SpnFmi_0 65535;
BA_ "GenSigSNA" SG_ 2566834934 BATT_dm1ConvMethod_0 65535;
BA_ "GenSigSNA" SG_ 2566834934 BATT_dm1FlashLampStatus_0 65535;
BA_ "GenSigSNA" SG_ 2566834934 BATT_dm1LampStatus_0 65535;
BA_ "GenSigSNA" SG_ 2566834934 BATT_dm1SpnMsb_0 65535;
BA_ "GenSigSNA" SG_ 2566834934 BATT_dm1SpnIsb_0 65535;
BA_ "GenSigSNA" SG_ 2566834935 BATT_dm1FlashLampStatus_1 65535;
BA_ "GenSigSNA" SG_ 2566834935 BATT_dm1LampStatus_1 65535;
BA_ "GenSigSNA" SG_ 2566834935 BATT_dm1SpnMsb_1 65535;
BA_ "GenSigSNA" SG_ 2566834935 BATT_dm1SpnLsb_1 65535;
BA_ "GenSigSNA" SG_ 2566834935 BATT_dm1SpnIsb_1 65535;
BA_ "GenSigSNA" SG_ 2566834935 BATT_dm1SpnFmi_1 65535;
BA_ "GenSigSNA" SG_ 2566834935 BATT_dm1ConvMethod_1 65535;
BA_ "GenSigSNA" SG_ 2566834936 BATT_dm1SpnMsb_2 65535;
BA_ "GenSigSNA" SG_ 2566834936 BATT_dm1SpnLsb_2 65535;
BA_ "GenSigSNA" SG_ 2566834936 BATT_dm1LampStatus_2 65535;
BA_ "GenSigSNA" SG_ 2566834936 BATT_dm1ConvMethod_2 65535;
BA_ "GenSigSNA" SG_ 2566834936 BATT_dm1FlashLampStatus_2 65535;
BA_ "GenSigSNA" SG_ 2566834936 BATT_dm1SpnIsb_2 65535;
BA_ "GenSigSNA" SG_ 2566834936 BATT_dm1SpnFmi_2 65535;
BA_ "GenSigSNA" SG_ 2566834937 BATT_dm1ConvMethod_3 65535;
BA_ "GenSigSNA" SG_ 2566834937 BATT_dm1FlashLampStatus_3 65535;
BA_ "GenSigSNA" SG_ 2566834937 BATT_dm1SpnLsb_3 65535;
BA_ "GenSigSNA" SG_ 2566834937 BATT_dm1SpnIsb_3 65535;
BA_ "GenSigSNA" SG_ 2566834937 BATT_dm1LampStatus_3 65535;
BA_ "GenSigSNA" SG_ 2566834937 BATT_dm1SpnMsb_3 65535;
BA_ "GenSigSNA" SG_ 2566834937 BATT_dm1SpnFmi_3 65535;
BA_ "GenSigSNA" SG_ 2566834938 BATT_dm1SpnIsb_4 65535;
BA_ "GenSigSNA" SG_ 2566834938 BATT_dm1LampStatus_4 65535;
BA_ "GenSigSNA" SG_ 2566834938 BATT_dm1SpnMsb_4 65535;
BA_ "GenSigSNA" SG_ 2566834938 BATT_dm1SpnLsb_4 65535;
BA_ "GenSigSNA" SG_ 2566834938 BATT_dm1FlashLampStatus_4 65535;
BA_ "GenSigSNA" SG_ 2566834938 BATT_dm1SpnFmi_4 65535;
BA_ "GenSigSNA" SG_ 2566834938 BATT_dm1ConvMethod_4 65535;
BA_ "GenSigSNA" SG_ 2566834939 BATT_dm1SpnFmi_5 65535;
BA_ "GenSigSNA" SG_ 2566834939 BATT_dm1LampStatus_5 65535;
BA_ "GenSigSNA" SG_ 2566834939 BATT_dm1FlashLampStatus_5 65535;
BA_ "GenSigSNA" SG_ 2566834939 BATT_dm1ConvMethod_5 65535;
BA_ "GenSigSNA" SG_ 2566834939 BATT_dm1SpnMsb_5 65535;
BA_ "GenSigSNA" SG_ 2566834939 BATT_dm1SpnIsb_5 65535;
BA_ "GenSigSNA" SG_ 2566834939 BATT_dm1SpnLsb_5 65535;
BA_ "GenSigSNA" SG_ 2566834940 BATT_dm1ConvMethod_6 65535;
BA_ "GenSigSNA" SG_ 2566834940 BATT_dm1SpnIsb_6 65535;
BA_ "GenSigSNA" SG_ 2566834940 BATT_dm1SpnFmi_6 65535;
BA_ "GenSigSNA" SG_ 2566834940 BATT_dm1LampStatus_6 65535;
BA_ "GenSigSNA" SG_ 2566834940 BATT_dm1FlashLampStatus_6 65535;
BA_ "GenSigSNA" SG_ 2566834940 BATT_dm1SpnMsb_6 65535;
BA_ "GenSigSNA" SG_ 2566834940 BATT_dm1SpnLsb_6 65535;
BA_ "GenSigSNA" SG_ 2566834941 BATT_dm1ConvMethod_7 65535;
BA_ "GenSigSNA" SG_ 2566834941 BATT_dm1LampStatus_7 65535;
BA_ "GenSigSNA" SG_ 2566834941 BATT_dm1FlashLampStatus_7 65535;
BA_ "GenSigSNA" SG_ 2566834941 BATT_dm1SpnLsb_7 65535;
BA_ "GenSigSNA" SG_ 2566834941 BATT_dm1SpnIsb_7 65535;
BA_ "GenSigSNA" SG_ 2566834941 BATT_dm1SpnFmi_7 65535;
BA_ "GenSigSNA" SG_ 2566834941 BATT_dm1SpnMsb_7 65535;
BA_ "GenSigSNA" SG_ 2566834942 BATT_dm1SpnMsb_8 65535;
BA_ "GenSigSNA" SG_ 2566834942 BATT_dm1ConvMethod_8 65535;
BA_ "GenSigSNA" SG_ 2566834942 BATT_dm1SpnFmi_8 65535;
BA_ "GenSigSNA" SG_ 2566834942 BATT_dm1LampStatus_8 65535;
BA_ "GenSigSNA" SG_ 2566834942 BATT_dm1FlashLampStatus_8 65535;
BA_ "GenSigSNA" SG_ 2566834942 BATT_dm1SpnLsb_8 65535;
BA_ "GenSigSNA" SG_ 2566834942 BATT_dm1SpnIsb_8 65535;
BA_ "GenSigSNA" SG_ 2566834943 BATT_dm1FlashLampStatus_9 65535;
BA_ "GenSigSNA" SG_ 2566834943 BATT_dm1ConvMethod_9 65535;
BA_ "GenSigSNA" SG_ 2566834943 BATT_dm1SpnFmi_9 65535;
BA_ "GenSigSNA" SG_ 2566834943 BATT_dm1LampStatus_9 65535;
BA_ "GenSigSNA" SG_ 2566834943 BATT_dm1SpnLsb_9 65535;
BA_ "GenSigSNA" SG_ 2566834943 BATT_dm1SpnIsb_9 65535;
BA_ "GenSigSNA" SG_ 2566834943 BATT_dm1SpnMsb_9 65535;
BA_ "GenSigSNA" SG_ 2566835190 BATT_dm2SpnIsb_0 65535;
BA_ "GenSigSNA" SG_ 2566835190 BATT_dm2SpnMsb_0 65535;
BA_ "GenSigSNA" SG_ 2566835190 BATT_dm2SpnLsb_0 65535;
BA_ "GenSigSNA" SG_ 2566835190 BATT_dm2FlashLampStatus_0 65535;
BA_ "GenSigSNA" SG_ 2566835190 BATT_dm2LampStatus_0 65535;
BA_ "GenSigSNA" SG_ 2566835190 BATT_dm2ConvMethod_0 65535;
BA_ "GenSigSNA" SG_ 2566835190 BATT_dm2SpnFmi_0 65535;
BA_ "GenSigSNA" SG_ 2566835191 BATT_dm2SpnMsb_1 65535;
BA_ "GenSigSNA" SG_ 2566835191 BATT_dm2SpnLsb_1 65535;
BA_ "GenSigSNA" SG_ 2566835191 BATT_dm2FlashLampStatus_1 65535;
BA_ "GenSigSNA" SG_ 2566835191 BATT_dm2LampStatus_1 65535;
BA_ "GenSigSNA" SG_ 2566835191 BATT_dm2ConvMethod_1 65535;
BA_ "GenSigSNA" SG_ 2566835191 BATT_dm2SpnFmi_1 65535;
BA_ "GenSigSNA" SG_ 2566835191 BATT_dm2SpnIsb_1 65535;
BA_ "GenSigSNA" SG_ 2566835192 BATT_dm2SpnLsb_2 65535;
BA_ "GenSigSNA" SG_ 2566835192 BATT_dm2SpnFmi_2 65535;
BA_ "GenSigSNA" SG_ 2566835192 BATT_dm2SpnIsb_2 65535;
BA_ "GenSigSNA" SG_ 2566835192 BATT_dm2ConvMethod_2 65535;
BA_ "GenSigSNA" SG_ 2566835192 BATT_dm2FlashLampStatus_2 65535;
BA_ "GenSigSNA" SG_ 2566835192 BATT_dm2SpnMsb_2 65535;
BA_ "GenSigSNA" SG_ 2566835192 BATT_dm2LampStatus_2 65535;
BA_ "GenSigSNA" SG_ 2566835193 BATT_dm2SpnIsb_3 65535;
BA_ "GenSigSNA" SG_ 2566835193 BATT_dm2SpnLsb_3 65535;
BA_ "GenSigSNA" SG_ 2566835193 BATT_dm2FlashLampStatus_3 65535;
BA_ "GenSigSNA" SG_ 2566835193 BATT_dm2ConvMethod_3 65535;
BA_ "GenSigSNA" SG_ 2566835193 BATT_dm2SpnMsb_3 65535;
BA_ "GenSigSNA" SG_ 2566835193 BATT_dm2LampStatus_3 65535;
BA_ "GenSigSNA" SG_ 2566835193 BATT_dm2SpnFmi_3 65535;
BA_ "GenSigSNA" SG_ 2566835194 BATT_dm2SpnLsb_4 65535;
BA_ "GenSigSNA" SG_ 2566835194 BATT_dm2LampStatus_4 65535;
BA_ "GenSigSNA" SG_ 2566835194 BATT_dm2SpnFmi_4 65535;
BA_ "GenSigSNA" SG_ 2566835194 BATT_dm2FlashLampStatus_4 65535;
BA_ "GenSigSNA" SG_ 2566835194 BATT_dm2SpnMsb_4 65535;
BA_ "GenSigSNA" SG_ 2566835194 BATT_dm2SpnIsb_4 65535;
BA_ "GenSigSNA" SG_ 2566835194 BATT_dm2ConvMethod_4 65535;
BA_ "GenSigSNA" SG_ 2566835195 BATT_dm2SpnIsb_5 65535;
BA_ "GenSigSNA" SG_ 2566835195 BATT_dm2SpnFmi_5 65535;
BA_ "GenSigSNA" SG_ 2566835195 BATT_dm2ConvMethod_5 65535;
BA_ "GenSigSNA" SG_ 2566835195 BATT_dm2SpnLsb_5 65535;
BA_ "GenSigSNA" SG_ 2566835195 BATT_dm2LampStatus_5 65535;
BA_ "GenSigSNA" SG_ 2566835195 BATT_dm2SpnMsb_5 65535;
BA_ "GenSigSNA" SG_ 2566835195 BATT_dm2FlashLampStatus_5 65535;
BA_ "GenSigSNA" SG_ 2566835196 BATT_dm2SpnMsb_6 65535;
BA_ "GenSigSNA" SG_ 2566835196 BATT_dm2LampStatus_6 65535;
BA_ "GenSigSNA" SG_ 2566835196 BATT_dm2SpnFmi_6 65535;
BA_ "GenSigSNA" SG_ 2566835196 BATT_dm2SpnLsb_6 65535;
BA_ "GenSigSNA" SG_ 2566835196 BATT_dm2SpnIsb_6 65535;
BA_ "GenSigSNA" SG_ 2566835196 BATT_dm2ConvMethod_6 65535;
BA_ "GenSigSNA" SG_ 2566835196 BATT_dm2FlashLampStatus_6 65535;
BA_ "GenSigSNA" SG_ 2566835197 BATT_dm2SpnIsb_7 65535;
BA_ "GenSigSNA" SG_ 2566835197 BATT_dm2SpnLsb_7 65535;
BA_ "GenSigSNA" SG_ 2566835197 BATT_dm2SpnFmi_7 65535;
BA_ "GenSigSNA" SG_ 2566835197 BATT_dm2ConvMethod_7 65535;
BA_ "GenSigSNA" SG_ 2566835197 BATT_dm2FlashLampStatus_7 65535;
BA_ "GenSigSNA" SG_ 2566835197 BATT_dm2SpnMsb_7 65535;
BA_ "GenSigSNA" SG_ 2566835197 BATT_dm2LampStatus_7 65535;
BA_ "GenSigSNA" SG_ 2566835198 BATT_dm2SpnLsb_8 65535;
BA_ "GenSigSNA" SG_ 2566835198 BATT_dm2ConvMethod_8 65535;
BA_ "GenSigSNA" SG_ 2566835198 BATT_dm2SpnFmi_8 65535;
BA_ "GenSigSNA" SG_ 2566835198 BATT_dm2SpnIsb_8 65535;
BA_ "GenSigSNA" SG_ 2566835198 BATT_dm2SpnMsb_8 65535;
BA_ "GenSigSNA" SG_ 2566835198 BATT_dm2FlashLampStatus_8 65535;
BA_ "GenSigSNA" SG_ 2566835198 BATT_dm2LampStatus_8 65535;
BA_ "GenSigSNA" SG_ 2566835199 BATT_dm2SpnIsb_9 65535;
BA_ "GenSigSNA" SG_ 2566835199 BATT_dm2FlashLampStatus_9 65535;
BA_ "GenSigSNA" SG_ 2566835199 BATT_dm2SpnMsb_9 65535;
BA_ "GenSigSNA" SG_ 2566835199 BATT_dm2ConvMethod_9 65535;
BA_ "GenSigSNA" SG_ 2566835199 BATT_dm2LampStatus_9 65535;
BA_ "GenSigSNA" SG_ 2566835199 BATT_dm2SpnLsb_9 65535;
BA_ "GenSigSNA" SG_ 2566835199 BATT_dm2SpnFmi_9 65535;
BA_ "GenSigSNA" SG_ 2566849014 BATT_vModDchLimit_0 65535;
BA_ "GenSigSNA" SG_ 2566849014 BATT_iModDchLimit10s_0 32767;
BA_ "GenSigSNA" SG_ 2566849014 BATT_iModDchLimit30s_0 32767;
BA_ "GenSigSNA" SG_ 2566849015 BATT_vModDchLimit_1 65535;
BA_ "GenSigSNA" SG_ 2566849015 BATT_iModDchLimit30s_1 32767;
BA_ "GenSigSNA" SG_ 2566849015 BATT_iModDchLimit10s_1 32767;
BA_ "GenSigSNA" SG_ 2566849016 BATT_iModDchLimit10s_2 32767;
BA_ "GenSigSNA" SG_ 2566849016 BATT_iModDchLimit30s_2 32767;
BA_ "GenSigSNA" SG_ 2566849016 BATT_vModDchLimit_2 65535;
BA_ "GenSigSNA" SG_ 2566849017 BATT_iModDchLimit10s_3 32767;
BA_ "GenSigSNA" SG_ 2566849017 BATT_vModDchLimit_3 65535;
BA_ "GenSigSNA" SG_ 2566849017 BATT_iModDchLimit30s_3 32767;
BA_ "GenSigSNA" SG_ 2566849018 BATT_iModDchLimit10s_4 32767;
BA_ "GenSigSNA" SG_ 2566849018 BATT_iModDchLimit30s_4 32767;
BA_ "GenSigSNA" SG_ 2566849018 BATT_vModDchLimit_4 65535;
BA_ "GenSigSNA" SG_ 2566849019 BATT_vModDchLimit_5 65535;
BA_ "GenSigSNA" SG_ 2566849019 BATT_iModDchLimit10s_5 32767;
BA_ "GenSigSNA" SG_ 2566849019 BATT_iModDchLimit30s_5 32767;
BA_ "GenSigSNA" SG_ 2566849020 BATT_iModDchLimit30s_6 32767;
BA_ "GenSigSNA" SG_ 2566849020 BATT_iModDchLimit10s_6 32767;
BA_ "GenSigSNA" SG_ 2566849020 BATT_vModDchLimit_6 65535;
BA_ "GenSigSNA" SG_ 2566849021 BATT_iModDchLimit30s_7 32767;
BA_ "GenSigSNA" SG_ 2566849021 BATT_vModDchLimit_7 65535;
BA_ "GenSigSNA" SG_ 2566849021 BATT_iModDchLimit10s_7 32767;
BA_ "GenSigSNA" SG_ 2566849022 BATT_iModDchLimit30s_8 32767;
BA_ "GenSigSNA" SG_ 2566849022 BATT_vModDchLimit_8 65535;
BA_ "GenSigSNA" SG_ 2566849022 BATT_iModDchLimit10s_8 32767;
BA_ "GenSigSNA" SG_ 2566849023 BATT_vModDchLimit_9 65535;
BA_ "GenSigSNA" SG_ 2566849023 BATT_iModDchLimit30s_9 32767;
BA_ "GenSigSNA" SG_ 2566849023 BATT_iModDchLimit10s_9 32767;
BA_ "GenSigSNA" SG_ 2566851062 BATT_tModule2 32767;
BA_ "GenSigSNA" SG_ 2566851062 BATT_tModule1 32767;
BA_ "GenSigSNA" SG_ 2566851062 BATT_tBoard 65535;
BA_ "GenSigSNA" SG_ 2566851830 BATT_vMod_0 65535;
BA_ "GenSigSNA" SG_ 2566851830 BATT_vModSumOfCells_0 65535;
BA_ "GenSigSNA" SG_ 2566851830 BATT_iMod_0 32767;
BA_ "GenSigSNA" SG_ 2566851830 BATT_iModFiltered_0 32767;
BA_ "GenSigSNA" SG_ 2566851831 BATT_vMod_1 65535;
BA_ "GenSigSNA" SG_ 2566851831 BATT_vModSumOfCells_1 65535;
BA_ "GenSigSNA" SG_ 2566851831 BATT_iMod_1 32767;
BA_ "GenSigSNA" SG_ 2566851831 BATT_iModFiltered_1 32767;
BA_ "GenSigSNA" SG_ 2566851832 BATT_vMod_2 65535;
BA_ "GenSigSNA" SG_ 2566851832 BATT_vModSumOfCells_2 65535;
BA_ "GenSigSNA" SG_ 2566851832 BATT_iMod_2 32767;
BA_ "GenSigSNA" SG_ 2566851832 BATT_iModFiltered_2 32767;
BA_ "GenSigSNA" SG_ 2566851833 BATT_vMod_3 65535;
BA_ "GenSigSNA" SG_ 2566851833 BATT_vModSumOfCells_3 65535;
BA_ "GenSigSNA" SG_ 2566851833 BATT_iMod_3 32767;
BA_ "GenSigSNA" SG_ 2566851833 BATT_iModFiltered_3 32767;
BA_ "GenSigSNA" SG_ 2566851834 BATT_vMod_4 65535;
BA_ "GenSigSNA" SG_ 2566851834 BATT_vModSumOfCells_4 65535;
BA_ "GenSigSNA" SG_ 2566851834 BATT_iMod_4 32767;
BA_ "GenSigSNA" SG_ 2566851834 BATT_iModFiltered_4 32767;
BA_ "GenSigSNA" SG_ 2566851835 BATT_vMod_5 65535;
BA_ "GenSigSNA" SG_ 2566851835 BATT_vModSumOfCells_5 65535;
BA_ "GenSigSNA" SG_ 2566851835 BATT_iMod_5 32767;
BA_ "GenSigSNA" SG_ 2566851835 BATT_iModFiltered_5 32767;
BA_ "GenSigSNA" SG_ 2566851836 BATT_vMod_6 65535;
BA_ "GenSigSNA" SG_ 2566851836 BATT_vModSumOfCells_6 65535;
BA_ "GenSigSNA" SG_ 2566851836 BATT_iMod_6 32767;
BA_ "GenSigSNA" SG_ 2566851836 BATT_iModFiltered_6 32767;
BA_ "GenSigSNA" SG_ 2566851837 BATT_vMod_7 65535;
BA_ "GenSigSNA" SG_ 2566851837 BATT_vModSumOfCells_7 65535;
BA_ "GenSigSNA" SG_ 2566851837 BATT_iMod_7 32767;
BA_ "GenSigSNA" SG_ 2566851837 BATT_iModFiltered_7 32767;
BA_ "GenSigSNA" SG_ 2566851838 BATT_vMod_8 65535;
BA_ "GenSigSNA" SG_ 2566851838 BATT_vModSumOfCells_8 65535;
BA_ "GenSigSNA" SG_ 2566851838 BATT_iMod_8 32767;
BA_ "GenSigSNA" SG_ 2566851838 BATT_iModFiltered_8 32767;

VAL_ 2566849014 BATT_iModDchLimitCont_0  32767 "SNA"  ;
VAL_ 2566849014 BATT_vModDchLimit_0  65535 "SNA"  ;
VAL_ 2566849014 BATT_iModDchLimit10s_0  32767 "SNA"  ;
VAL_ 2566849014 BATT_iModDchLimit30s_0  32767 "SNA"  ;
VAL_ 2566849015 BATT_vModDchLimit_1  65535 "SNA"  ;
VAL_ 2566849015 BATT_iModDchLimitCont_1  32767 "SNA"  ;
VAL_ 2566849015 BATT_iModDchLimit30s_1  32767 "SNA"  ;
VAL_ 2566849015 BATT_iModDchLimit10s_1  32767 "SNA"  ;
VAL_ 2566849016 BATT_iModDchLimit10s_2  32767 "SNA"  ;
VAL_ 2566849016 BATT_iModDchLimitCont_2  32767 "SNA"  ;
VAL_ 2566849016 BATT_iModDchLimit30s_2  32767 "SNA"  ;
VAL_ 2566849016 BATT_vModDchLimit_2  65535 "SNA"  ;
VAL_ 2566849017 BATT_iModDchLimitCont_3  32767 "SNA"  ;
VAL_ 2566849017 BATT_iModDchLimit10s_3  32767 "SNA"  ;
VAL_ 2566849017 BATT_vModDchLimit_3  65535 "SNA"  ;
VAL_ 2566849017 BATT_iModDchLimit30s_3  32767 "SNA"  ;
VAL_ 2566849018 BATT_iModDchLimitCont_4  32767 "SNA"  ;
VAL_ 2566849018 BATT_iModDchLimit10s_4  32767 "SNA"  ;
VAL_ 2566849018 BATT_iModDchLimit30s_4  32767 "SNA"  ;
VAL_ 2566849018 BATT_vModDchLimit_4  65535 "SNA"  ;
VAL_ 2566849019 BATT_vModDchLimit_5  65535 "SNA"  ;
VAL_ 2566849019 BATT_iModDchLimit10s_5  32767 "SNA"  ;
VAL_ 2566849019 BATT_iModDchLimit30s_5  32767 "SNA"  ;
VAL_ 2566849019 BATT_iModDchLimitCont_5  32767 "SNA"  ;
VAL_ 2566849020 BATT_iModDchLimit30s_6  32767 "SNA"  ;
VAL_ 2566849020 BATT_iModDchLimit10s_6  32767 "SNA"  ;
VAL_ 2566849020 BATT_vModDchLimit_6  65535 "SNA"  ;
VAL_ 2566849020 BATT_iModDchLimitCont_6  32767 "SNA"  ;
VAL_ 2566849021 BATT_iModDchLimit30s_7  32767 "SNA"  ;
VAL_ 2566849021 BATT_vModDchLimit_7  65535 "SNA"  ;
VAL_ 2566849021 BATT_iModDchLimitCont_7  32767 "SNA"  ;
VAL_ 2566849021 BATT_iModDchLimit10s_7  32767 "SNA"  ;
VAL_ 2566849022 BATT_iModDchLimit30s_8  32767 "SNA"  ;
VAL_ 2566849022 BATT_vModDchLimit_8  65535 "SNA"  ;
VAL_ 2566849022 BATT_iModDchLimitCont_8  32767 "SNA"  ;
VAL_ 2566849022 BATT_iModDchLimit10s_8  32767 "SNA"  ;
VAL_ 2566849023 BATT_vModDchLimit_9  65535 "SNA"  ;
VAL_ 2566849023 BATT_iModDchLimit30s_9  32767 "SNA"  ;
VAL_ 2566849023 BATT_iModDchLimitCont_9  32767 "SNA"  ;
VAL_ 2566849023 BATT_iModDchLimit10s_9  32767 "SNA"  ;
VAL_ 2566851062 BATT_tModule2  32767 "SNA"  ;
VAL_ 2566851062 BATT_tModule1  32767 "SNA"  ;
VAL_ 2566851062 BATT_tBoard  65535 "SNA"  ;
VAL_ 2566851318 BATT_modStateRequested_0  4 "Connect"  3 "Disconnect"  2 "Charge"  1 "Drive"  0 "Standby"  ;
VAL_ 2566851318 BATT_modDataValid_0  1 "Valid"  0 "Not Valid"  ;
VAL_ 2566851318 BATT_prechargeState_0  6 "Fault"  5 "Complete"  4 "Idle"  3 "P0F1"  2 "P1F1"  1 "P1F0"  0 "P0F0"  ;
VAL_ 2566851318 BATT_fetPchgCommand_0  1 "Close"  0 "Open"  ;
VAL_ 2566851318 BATT_fetDsgCommand_0  1 "Close"  0 "Open"  ;
VAL_ 2566851318 BATT_fetChgCommand_0  1 "Close"  0 "Open"  ;
VAL_ 2566851318 BATT_fetDsgStatus_0  8 "Welded"  7 "OpenPending"  6 "FailToClose"  5 "FailToOpen"  4 "Closing"  3 "Opening"  2 "Closed"  1 "Open"  0 "Unknown"  ;
VAL_ 2566851318 BATT_fetChgStatus_0  8 "Welded"  7 "OpenPending"  6 "FailToClose"  5 "FailToOpen"  4 "Closing"  3 "Opening"  2 "Closed"  1 "Open"  0 "Unknown"  ;
VAL_ 2566851318 BATT_modPackState_0  10 "Disconnect"  9 "ConnectCharge"  8 "ConnectDrive"  7 "SelectCharge"  6 "SelectDrive"  5 "ChargeStandbyConnect"  4 "Reserved"  3 "Charge"  2 "Drive"  1 "StandbyReady"  0 "StandbyNotReady"  ;
VAL_ 2566851318 BATT_modChildState_0  12 "connectbusjoin"  11 "connectbusprecharge"  10 "softdisconnectbus"  9 "disconnectbus"  8 "chargenormal"  7 "drivenormal"  6 "driverampdown"  5 "drivelimp"  4 "standbyready"  3 "standbyfault"  2 "standbynotready"  1 "standbysleeping"  0 "standbysleep"  ;
VAL_ 2566851318 BATT_modParentState_0  4 "Connect"  3 "Disconnect"  2 "Charge"  1 "Drive"  0 "Standby"  ;
VAL_ 2566851319 BATT_modStateRequested_1  4 "Connect"  3 "Disconnect"  2 "Charge"  1 "Drive"  0 "Standby"  ;
VAL_ 2566851319 BATT_modDataValid_1  1 "Valid"  0 "Not Valid"  ;
VAL_ 2566851319 BATT_prechargeState_1  6 "Fault"  5 "Complete"  4 "Idle"  3 "P0F1"  2 "P1F1"  1 "P1F0"  0 "P0F0"  ;
VAL_ 2566851319 BATT_fetPchgCommand_1  1 "Close"  0 "Open"  ;
VAL_ 2566851319 BATT_fetDsgCommand_1  1 "Close"  0 "Open"  ;
VAL_ 2566851319 BATT_fetChgCommand_1  1 "Close"  0 "Open"  ;
VAL_ 2566851319 BATT_fetDsgStatus_1  8 "Welded"  7 "OpenPending"  6 "FailToClose"  5 "FailToOpen"  4 "Closing"  3 "Opening"  2 "Closed"  1 "Open"  0 "Unknown"  ;
VAL_ 2566851319 BATT_fetChgStatus_1  8 "Welded"  7 "OpenPending"  6 "FailToClose"  5 "FailToOpen"  4 "Closing"  3 "Opening"  2 "Closed"  1 "Open"  0 "Unknown"  ;
VAL_ 2566851319 BATT_modPackState_1  10 "Disconnect"  9 "ConnectCharge"  8 "ConnectDrive"  7 "SelectCharge"  6 "SelectDrive"  5 "ChargeStandbyConnect"  4 "Reserved"  3 "Charge"  2 "Drive"  1 "StandbyReady"  0 "StandbyNotReady"  ;
VAL_ 2566851319 BATT_modChildState_1  12 "connectbusjoin"  11 "connectbusprecharge"  10 "softdisconnectbus"  9 "disconnectbus"  8 "chargenormal"  7 "drivenormal"  6 "driverampdown"  5 "drivelimp"  4 "standbyready"  3 "standbyfault"  2 "standbynotready"  1 "standbysleeping"  0 "standbysleep"  ;
VAL_ 2566851319 BATT_modParentState_1  4 "Connect"  3 "Disconnect"  2 "Charge"  1 "Drive"  0 "Standby"  ;
VAL_ 2566851320 BATT_modStateRequested_2  4 "Connect"  3 "Disconnect"  2 "Charge"  1 "Drive"  0 "Standby"  ;
VAL_ 2566851320 BATT_modDataValid_2  1 "Valid"  0 "Not Valid"  ;
VAL_ 2566851320 BATT_prechargeState_2  6 "Fault"  5 "Complete"  4 "Idle"  3 "P0F1"  2 "P1F1"  1 "P1F0"  0 "P0F0"  ;
VAL_ 2566851320 BATT_fetPchgCommand_2  1 "Close"  0 "Open"  ;
VAL_ 2566851320 BATT_fetDsgCommand_2  1 "Close"  0 "Open"  ;
VAL_ 2566851320 BATT_fetChgCommand_2  1 "Close"  0 "Open"  ;
VAL_ 2566851320 BATT_fetDsgStatus_2  8 "Welded"  7 "OpenPending"  6 "FailToClose"  5 "FailToOpen"  4 "Closing"  3 "Opening"  2 "Closed"  1 "Open"  0 "Unknown"  ;
VAL_ 2566851320 BATT_fetChgStatus_2  8 "Welded"  7 "OpenPending"  6 "FailToClose"  5 "FailToOpen"  4 "Closing"  3 "Opening"  2 "Closed"  1 "Open"  0 "Unknown"  ;
VAL_ 2566851320 BATT_modPackState_2  10 "Disconnect"  9 "ConnectCharge"  8 "ConnectDrive"  7 "SelectCharge"  6 "SelectDrive"  5 "ChargeStandbyConnect"  4 "Reserved"  3 "Charge"  2 "Drive"  1 "StandbyReady"  0 "StandbyNotReady"  ;
VAL_ 2566851320 BATT_modChildState_2  12 "connectbusjoin"  11 "connectbusprecharge"  10 "softdisconnectbus"  9 "disconnectbus"  8 "chargenormal"  7 "drivenormal"  6 "driverampdown"  5 "drivelimp"  4 "standbyready"  3 "standbyfault"  2 "standbynotready"  1 "standbysleeping"  0 "standbysleep"  ;
VAL_ 2566851320 BATT_modParentState_2  4 "Connect"  3 "Disconnect"  2 "Charge"  1 "Drive"  0 "Standby"  ;
VAL_ 2566851321 BATT_modStateRequested_3  4 "Connect"  3 "Disconnect"  2 "Charge"  1 "Drive"  0 "Standby"  ;
VAL_ 2566851321 BATT_modDataValid_3  1 "Valid"  0 "Not Valid"  ;
VAL_ 2566851321 BATT_prechargeState_3  6 "Fault"  5 "Complete"  4 "Idle"  3 "P0F1"  2 "P1F1"  1 "P1F0"  0 "P0F0"  ;
VAL_ 2566851321 BATT_fetPchgCommand_3  1 "Close"  0 "Open"  ;
VAL_ 2566851321 BATT_fetDsgCommand_3  1 "Close"  0 "Open"  ;
VAL_ 2566851321 BATT_fetChgCommand_3  1 "Close"  0 "Open"  ;
VAL_ 2566851321 BATT_fetDsgStatus_3  8 "Welded"  7 "OpenPending"  6 "FailToClose"  5 "FailToOpen"  4 "Closing"  3 "Opening"  2 "Closed"  1 "Open"  0 "Unknown"  ;
VAL_ 2566851321 BATT_fetChgStatus_3  8 "Welded"  7 "OpenPending"  6 "FailToClose"  5 "FailToOpen"  4 "Closing"  3 "Opening"  2 "Closed"  1 "Open"  0 "Unknown"  ;
VAL_ 2566851321 BATT_modPackState_3  10 "Disconnect"  9 "ConnectCharge"  8 "ConnectDrive"  7 "SelectCharge"  6 "SelectDrive"  5 "ChargeStandbyConnect"  4 "Reserved"  3 "Charge"  2 "Drive"  1 "StandbyReady"  0 "StandbyNotReady"  ;
VAL_ 2566851321 BATT_modChildState_3  12 "connectbusjoin"  11 "connectbusprecharge"  10 "softdisconnectbus"  9 "disconnectbus"  8 "chargenormal"  7 "drivenormal"  6 "driverampdown"  5 "drivelimp"  4 "standbyready"  3 "standbyfault"  2 "standbynotready"  1 "standbysleeping"  0 "standbysleep"  ;
VAL_ 2566851321 BATT_modParentState_3  4 "Connect"  3 "Disconnect"  2 "Charge"  1 "Drive"  0 "Standby"  ;
VAL_ 2566851322 BATT_modStateRequested_4  4 "Connect"  3 "Disconnect"  2 "Charge"  1 "Drive"  0 "Standby"  ;
VAL_ 2566851322 BATT_modDataValid_4  1 "Valid"  0 "Not Valid"  ;
VAL_ 2566851322 BATT_prechargeState_4  6 "Fault"  5 "Complete"  4 "Idle"  3 "P0F1"  2 "P1F1"  1 "P1F0"  0 "P0F0"  ;
VAL_ 2566851322 BATT_fetPchgCommand_4  1 "Close"  0 "Open"  ;
VAL_ 2566851322 BATT_fetDsgCommand_4  1 "Close"  0 "Open"  ;
VAL_ 2566851322 BATT_fetChgCommand_4  1 "Close"  0 "Open"  ;
VAL_ 2566851322 BATT_fetDsgStatus_4  8 "Welded"  7 "OpenPending"  6 "FailToClose"  5 "FailToOpen"  4 "Closing"  3 "Opening"  2 "Closed"  1 "Open"  0 "Unknown"  ;
VAL_ 2566851322 BATT_fetChgStatus_4  8 "Welded"  7 "OpenPending"  6 "FailToClose"  5 "FailToOpen"  4 "Closing"  3 "Opening"  2 "Closed"  1 "Open"  0 "Unknown"  ;
VAL_ 2566851322 BATT_modPackState_4  10 "Disconnect"  9 "ConnectCharge"  8 "ConnectDrive"  7 "SelectCharge"  6 "SelectDrive"  5 "ChargeStandbyConnect"  4 "Reserved"  3 "Charge"  2 "Drive"  1 "StandbyReady"  0 "StandbyNotReady"  ;
VAL_ 2566851322 BATT_modChildState_4  12 "connectbusjoin"  11 "connectbusprecharge"  10 "softdisconnectbus"  9 "disconnectbus"  8 "chargenormal"  7 "drivenormal"  6 "driverampdown"  5 "drivelimp"  4 "standbyready"  3 "standbyfault"  2 "standbynotready"  1 "standbysleeping"  0 "standbysleep"  ;
VAL_ 2566851322 BATT_modParentState_4  4 "Connect"  3 "Disconnect"  2 "Charge"  1 "Drive"  0 "Standby"  ;
VAL_ 2566851323 BATT_modStateRequested_5  4 "Connect"  3 "Disconnect"  2 "Charge"  1 "Drive"  0 "Standby"  ;
VAL_ 2566851323 BATT_modDataValid_5  1 "Valid"  0 "Not Valid"  ;
VAL_ 2566851323 BATT_prechargeState_5  6 "Fault"  5 "Complete"  4 "Idle"  3 "P0F1"  2 "P1F1"  1 "P1F0"  0 "P0F0"  ;
VAL_ 2566851323 BATT_fetPchgCommand_5  1 "Close"  0 "Open"  ;
VAL_ 2566851323 BATT_fetDsgCommand_5  1 "Close"  0 "Open"  ;
VAL_ 2566851323 BATT_fetChgCommand_5  1 "Close"  0 "Open"  ;
VAL_ 2566851323 BATT_fetDsgStatus_5  8 "Welded"  7 "OpenPending"  6 "FailToClose"  5 "FailToOpen"  4 "Closing"  3 "Opening"  2 "Closed"  1 "Open"  0 "Unknown"  ;
VAL_ 2566851323 BATT_fetChgStatus_5  8 "Welded"  7 "OpenPending"  6 "FailToClose"  5 "FailToOpen"  4 "Closing"  3 "Opening"  2 "Closed"  1 "Open"  0 "Unknown"  ;
VAL_ 2566851323 BATT_modPackState_5  10 "Disconnect"  9 "ConnectCharge"  8 "ConnectDrive"  7 "SelectCharge"  6 "SelectDrive"  5 "ChargeStandbyConnect"  4 "Reserved"  3 "Charge"  2 "Drive"  1 "StandbyReady"  0 "StandbyNotReady"  ;
VAL_ 2566851323 BATT_modChildState_5  12 "connectbusjoin"  11 "connectbusprecharge"  10 "softdisconnectbus"  9 "disconnectbus"  8 "chargenormal"  7 "drivenormal"  6 "driverampdown"  5 "drivelimp"  4 "standbyready"  3 "standbyfault"  2 "standbynotready"  1 "standbysleeping"  0 "standbysleep"  ;
VAL_ 2566851323 BATT_modParentState_5  4 "Connect"  3 "Disconnect"  2 "Charge"  1 "Drive"  0 "Standby"  ;
VAL_ 2566851324 BATT_modPackState_6  10 "Disconnect"  9 "ConnectCharge"  8 "ConnectDrive"  7 "SelectCharge"  6 "SelectDrive"  5 "ChargeStandbyConnect"  4 "Reserved"  3 "Charge"  2 "Drive"  1 "StandbyReady"  0 "StandbyNotReady"  ;
VAL_ 2566851324 BATT_modChildState_6  12 "connectbusjoin"  11 "connectbusprecharge"  10 "softdisconnectbus"  9 "disconnectbus"  8 "chargenormal"  7 "drivenormal"  6 "driverampdown"  5 "drivelimp"  4 "standbyready"  3 "standbyfault"  2 "standbynotready"  1 "standbysleeping"  0 "standbysleep"  ;
VAL_ 2566851324 BATT_modParentState_6  4 "Connect"  3 "Disconnect"  2 "Charge"  1 "Drive"  0 "Standby"  ;
VAL_ 2566851324 BATT_modStateRequested_6  4 "Connect"  3 "Disconnect"  2 "Charge"  1 "Drive"  0 "Standby"  ;
VAL_ 2566851324 BATT_modDataValid_6  1 "Valid"  0 "Not Valid"  ;
VAL_ 2566851324 BATT_prechargeState_6  6 "Fault"  5 "Complete"  4 "Idle"  3 "P0F1"  2 "P1F1"  1 "P1F0"  0 "P0F0"  ;
VAL_ 2566851324 BATT_fetPchgCommand_6  1 "Close"  0 "Open"  ;
VAL_ 2566851324 BATT_fetDsgCommand_6  1 "Close"  0 "Open"  ;
VAL_ 2566851324 BATT_fetChgCommand_6  1 "Close"  0 "Open"  ;
VAL_ 2566851324 BATT_fetDsgStatus_6  8 "Welded"  7 "OpenPending"  6 "FailToClose"  5 "FailToOpen"  4 "Closing"  3 "Opening"  2 "Closed"  1 "Open"  0 "Unknown"  ;
VAL_ 2566851324 BATT_fetChgStatus_6  8 "Welded"  7 "OpenPending"  6 "FailToClose"  5 "FailToOpen"  4 "Closing"  3 "Opening"  2 "Closed"  1 "Open"  0 "Unknown"  ;
VAL_ 2566851325 BATT_modStateRequested_7  4 "Connect"  3 "Disconnect"  2 "Charge"  1 "Drive"  0 "Standby"  ;
VAL_ 2566851325 BATT_modDataValid_7  1 "Valid"  0 "Not Valid"  ;
VAL_ 2566851325 BATT_prechargeState_7  6 "Fault"  5 "Complete"  4 "Idle"  3 "P0F1"  2 "P1F1"  1 "P1F0"  0 "P0F0"  ;
VAL_ 2566851325 BATT_fetPchgCommand_7  1 "Close"  0 "Open"  ;
VAL_ 2566851325 BATT_fetDsgCommand_7  1 "Close"  0 "Open"  ;
VAL_ 2566851325 BATT_fetChgCommand_7  1 "Close"  0 "Open"  ;
VAL_ 2566851325 BATT_fetDsgStatus_7  8 "Welded"  7 "OpenPending"  6 "FailToClose"  5 "FailToOpen"  4 "Closing"  3 "Opening"  2 "Closed"  1 "Open"  0 "Unknown"  ;
VAL_ 2566851325 BATT_fetChgStatus_7  8 "Welded"  7 "OpenPending"  6 "FailToClose"  5 "FailToOpen"  4 "Closing"  3 "Opening"  2 "Closed"  1 "Open"  0 "Unknown"  ;
VAL_ 2566851325 BATT_modPackState_7  10 "Disconnect"  9 "ConnectCharge"  8 "ConnectDrive"  7 "SelectCharge"  6 "SelectDrive"  5 "ChargeStandbyConnect"  4 "Reserved"  3 "Charge"  2 "Drive"  1 "StandbyReady"  0 "StandbyNotReady"  ;
VAL_ 2566851325 BATT_modChildState_7  12 "connectbusjoin"  11 "connectbusprecharge"  10 "softdisconnectbus"  9 "disconnectbus"  8 "chargenormal"  7 "drivenormal"  6 "driverampdown"  5 "drivelimp"  4 "standbyready"  3 "standbyfault"  2 "standbynotready"  1 "standbysleeping"  0 "standbysleep"  ;
VAL_ 2566851325 BATT_modParentState_7  4 "Connect"  3 "Disconnect"  2 "Charge"  1 "Drive"  0 "Standby"  ;
VAL_ 2566851326 BATT_modStateRequested_8  4 "Connect"  3 "Disconnect"  2 "Charge"  1 "Drive"  0 "Standby"  ;
VAL_ 2566851326 BATT_modDataValid_8  1 "Valid"  0 "Not Valid"  ;
VAL_ 2566851326 BATT_prechargeState_8  6 "Fault"  5 "Complete"  4 "Idle"  3 "P0F1"  2 "P1F1"  1 "P1F0"  0 "P0F0"  ;
VAL_ 2566851326 BATT_fetPchgCommand_8  1 "Close"  0 "Open"  ;
VAL_ 2566851326 BATT_fetDsgCommand_8  1 "Close"  0 "Open"  ;
VAL_ 2566851326 BATT_fetChgCommand_8  1 "Close"  0 "Open"  ;
VAL_ 2566851326 BATT_fetDsgStatus_8  8 "Welded"  7 "OpenPending"  6 "FailToClose"  5 "FailToOpen"  4 "Closing"  3 "Opening"  2 "Closed"  1 "Open"  0 "Unknown"  ;
VAL_ 2566851326 BATT_fetChgStatus_8  8 "Welded"  7 "OpenPending"  6 "FailToClose"  5 "FailToOpen"  4 "Closing"  3 "Opening"  2 "Closed"  1 "Open"  0 "Unknown"  ;
VAL_ 2566851326 BATT_modPackState_8  10 "Disconnect"  9 "ConnectCharge"  8 "ConnectDrive"  7 "SelectCharge"  6 "SelectDrive"  5 "ChargeStandbyConnect"  4 "Reserved"  3 "Charge"  2 "Drive"  1 "StandbyReady"  0 "StandbyNotReady"  ;
VAL_ 2566851326 BATT_modChildState_8  12 "connectbusjoin"  11 "connectbusprecharge"  10 "softdisconnectbus"  9 "disconnectbus"  8 "chargenormal"  7 "drivenormal"  6 "driverampdown"  5 "drivelimp"  4 "standbyready"  3 "standbyfault"  2 "standbynotready"  1 "standbysleeping"  0 "standbysleep"  ;
VAL_ 2566851326 BATT_modParentState_8  4 "Connect"  3 "Disconnect"  2 "Charge"  1 "Drive"  0 "Standby"  ;
VAL_ 2566851327 BATT_modStateRequested_9  4 "Connect"  3 "Disconnect"  2 "Charge"  1 "Drive"  0 "Standby"  ;
VAL_ 2566851327 BATT_modDataValid_9  1 "Valid"  0 "Not Valid"  ;
VAL_ 2566851327 BATT_prechargeState_9  6 "Fault"  5 "Complete"  4 "Idle"  3 "P0F1"  2 "P1F1"  1 "P1F0"  0 "P0F0"  ;
VAL_ 2566851327 BATT_fetPchgCommand_9  1 "Close"  0 "Open"  ;
VAL_ 2566851327 BATT_fetDsgCommand_9  1 "Close"  0 "Open"  ;
VAL_ 2566851327 BATT_fetChgCommand_9  1 "Close"  0 "Open"  ;
VAL_ 2566851327 BATT_fetDsgStatus_9  8 "Welded"  7 "OpenPending"  6 "FailToClose"  5 "FailToOpen"  4 "Closing"  3 "Opening"  2 "Closed"  1 "Open"  0 "Unknown"  ;
VAL_ 2566851327 BATT_fetChgStatus_9  8 "Welded"  7 "OpenPending"  6 "FailToClose"  5 "FailToOpen"  4 "Closing"  3 "Opening"  2 "Closed"  1 "Open"  0 "Unknown"  ;
VAL_ 2566851327 BATT_modPackState_9  10 "Disconnect"  9 "ConnectCharge"  8 "ConnectDrive"  7 "SelectCharge"  6 "SelectDrive"  5 "ChargeStandbyConnect"  4 "Reserved"  3 "Charge"  2 "Drive"  1 "StandbyReady"  0 "StandbyNotReady"  ;
VAL_ 2566851327 BATT_modChildState_9  12 "connectbusjoin"  11 "connectbusprecharge"  10 "softdisconnectbus"  9 "disconnectbus"  8 "chargenormal"  7 "drivenormal"  6 "driverampdown"  5 "drivelimp"  4 "standbyready"  3 "standbyfault"  2 "standbynotready"  1 "standbysleeping"  0 "standbysleep"  ;
VAL_ 2566851327 BATT_modParentState_9  4 "Connect"  3 "Disconnect"  2 "Charge"  1 "Drive"  0 "Standby"  ;
VAL_ 2566851830 BATT_vMod_0  65535 "SNA"  ;
VAL_ 2566851830 BATT_vModSumOfCells_0  65535 "SNA"  ;
VAL_ 2566851830 BATT_iMod_0  32767 "SNA"  ;
VAL_ 2566851830 BATT_iModFiltered_0  32767 "SNA"  ;
VAL_ 2566851831 BATT_vMod_1  65535 "SNA"  ;
VAL_ 2566851831 BATT_vModSumOfCells_1  65535 "SNA"  ;
VAL_ 2566851831 BATT_iMod_1  32767 "SNA"  ;
VAL_ 2566851831 BATT_iModFiltered_1  32767 "SNA"  ;
VAL_ 2566851832 BATT_vMod_2  65535 "SNA"  ;
VAL_ 2566851832 BATT_vModSumOfCells_2  65535 "SNA"  ;
VAL_ 2566851832 BATT_iMod_2  32767 "SNA"  ;
VAL_ 2566851832 BATT_iModFiltered_2  32767 "SNA"  ;
VAL_ 2566851833 BATT_vMod_3  65535 "SNA"  ;
VAL_ 2566851833 BATT_vModSumOfCells_3  65535 "SNA"  ;
VAL_ 2566851833 BATT_iMod_3  32767 "SNA"  ;
VAL_ 2566851833 BATT_iModFiltered_3  32767 "SNA"  ;
VAL_ 2566851834 BATT_vMod_4  65535 "SNA"  ;
VAL_ 2566851834 BATT_vModSumOfCells_4  65535 "SNA"  ;
VAL_ 2566851834 BATT_iMod_4  32767 "SNA"  ;
VAL_ 2566851834 BATT_iModFiltered_4  32767 "SNA"  ;
VAL_ 2566851835 BATT_vMod_5  65535 "SNA"  ;
VAL_ 2566851835 BATT_vModSumOfCells_5  65535 "SNA"  ;
VAL_ 2566851835 BATT_iMod_5  32767 "SNA"  ;
VAL_ 2566851835 BATT_iModFiltered_5  32767 "SNA"  ;
VAL_ 2566851836 BATT_vMod_6  65535 "SNA"  ;
VAL_ 2566851836 BATT_vModSumOfCells_6  65535 "SNA"  ;
VAL_ 2566851836 BATT_iMod_6  32767 "SNA"  ;
VAL_ 2566851836 BATT_iModFiltered_6  32767 "SNA"  ;
VAL_ 2566851837 BATT_vMod_7  65535 "SNA"  ;
VAL_ 2566851837 BATT_vModSumOfCells_7  65535 "SNA"  ;
VAL_ 2566851837 BATT_iMod_7  32767 "SNA"  ;
VAL_ 2566851837 BATT_iModFiltered_7  32767 "SNA"  ;
VAL_ 2566851838 BATT_vMod_8  65535 "SNA"  ;
VAL_ 2566851838 BATT_vModSumOfCells_8  65535 "SNA"  ;
VAL_ 2566851838 BATT_iMod_8  32767 "SNA"  ;
VAL_ 2566851838 BATT_iModFiltered_8  32767 "SNA"  ;
